VERSION "dbc-export 1 2025.20.8"

NS_ :

BS_:

BU_: ADSP APB APP APS BB BMS CC CP DAS DI DIF DIR EPAS3P EPAS3S EPBL EPBR GTW HVP ICR IDB PCS PM TCU UI UIS VC VCFRONT VCLEFT VCRIGHT VCSEC

BO_ 628 UI_vehicleControl3: 8 UI
 SG_ UI_lightFlashRequest : 0|2@1+ (1,0) [0|3] "" Vector__XXX
 SG_ UI_phoneCallActive : 3|1@1+ (1,0) [0|1] "" Vector__XXX
 SG_ UI_lightShowClosuresEnabled : 8|1@1+ (1,0) [0|1] "" Vector__XXX
 SG_ UI_steeringWheelHeatAutoReq : 9|1@1+ (1,0) [0|1] "" Vector__XXX
 SG_ UI_steeringWheelHeatLevelReq : 10|2@1+ (1,0) [0|3] "" Vector__XXX
 SG_ UI_headlightPulseRequest : 12|1@1+ (1,0) [0|1] "" Vector__XXX
 SG_ UI_displayRedShiftActive : 24|1@1+ (1,0) [0|1] "" Vector__XXX
 SG_ UI_fasciaCameraWashRequest : 26|1@1+ (1,0) [0|1] "" Vector__XXX
 SG_ UI_leftRearSeatAdjustmentRequest : 28|3@1+ (1,0) [0|7] "" Vector__XXX
 SG_ UI_rightRearSeatAdjustmentReques : 32|3@1+ (1,0) [0|7] "" Vector__XXX
 SG_ UI_blindSpotIndicatorLightReques : 35|1@1+ (1,0) [0|1] "" Vector__XXX
 SG_ UI_keepOnAccessoryPortsReq : 38|1@1+ (1,0) [0|1] "" Vector__XXX
 SG_ UI_fasciaCameraShown : 39|1@1+ (1,0) [0|1] "" Vector__XXX
 SG_ UI_rearSeatChildLock : 40|2@1+ (1,0) [0|3] "" Vector__XXX
 SG_ UI_windowPercentageRequest : 42|6@1- (5,0) [-100|100] "%" Vector__XXX
 SG_ UI_windowRequestedFL : 48|1@1+ (1,0) [0|1] "" Vector__XXX
 SG_ UI_windowRequestedFR : 49|1@1+ (1,0) [0|1] "" Vector__XXX
 SG_ UI_windowRequestedRL : 50|1@1+ (1,0) [0|1] "" Vector__XXX
 SG_ UI_windowRequestedRR : 51|1@1+ (1,0) [0|1] "" Vector__XXX
 SG_ UI_windowRequest : 52|3@1+ (1,0) [0|7] "" Vector__XXX
 SG_ UI_closeTrunkRequest : 55|1@1+ (1,0) [0|1] "" Vector__XXX
 SG_ UI_childPresenceDetectionDisable : 56|1@1+ (1,0) [0|1] "" Vector__XXX
 SG_ UI_derivedLoadshedFeature : 59|1@1+ (1,0) [0|1] "" Vector__XXX
 SG_ UI_selfParkStandingBy : 62|1@1+ (1,0) [0|1] "" Vector__XXX

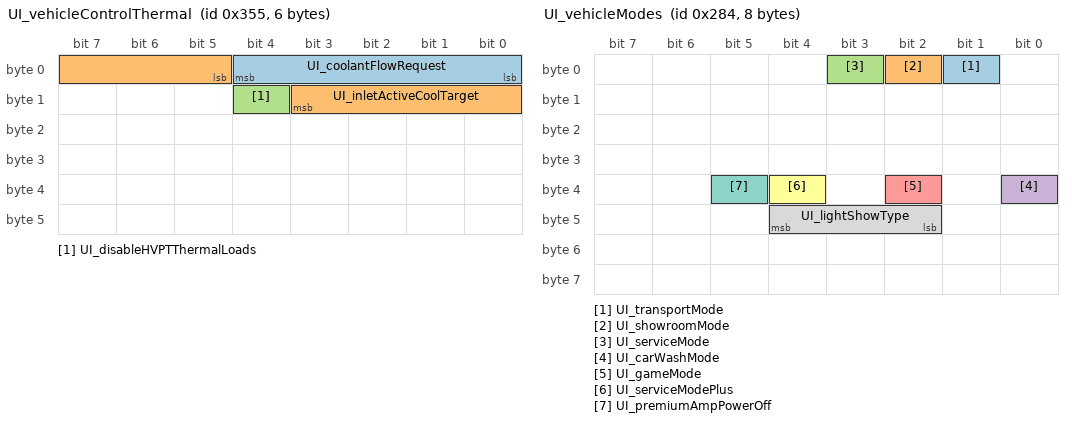
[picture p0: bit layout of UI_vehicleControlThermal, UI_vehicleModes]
BO_ 853 UI_vehicleControlThermal: 6 UI
 SG_ UI_coolantFlowRequest : 0|5@1+ (1,0) [0|25] "LPM" Vector__XXX
 SG_ UI_inletActiveCoolTarget : 5|7@1+ (1,0) [0|127] "degC" Vector__XXX
 SG_ UI_disableHVPTThermalLoads : 12|1@1+ (1,0) [0|1] "" Vector__XXX

BO_ 644 UI_vehicleModes: 8 UI
 SG_ UI_transportMode : 1|1@1+ (1,0) [0|1] "" Vector__XXX
 SG_ UI_showroomMode : 2|1@1+ (1,0) [0|1] "" Vector__XXX
 SG_ UI_serviceMode : 3|1@1+ (1,0) [0|1] "" Vector__XXX
 SG_ UI_carWashMode : 32|1@1+ (1,0) [0|1] "" Vector__XXX
 SG_ UI_gameMode : 34|1@1+ (1,0) [0|1] "" Vector__XXX
 SG_ UI_serviceModePlus : 36|1@1+ (1,0) [0|1] "" Vector__XXX
 SG_ UI_premiumAmpPowerOff : 37|1@1+ (1,0) [0|1] "" Vector__XXX
 SG_ UI_lightShowType : 42|3@1+ (1,0) [0|7] "" Vector__XXX

BO_ 595 UI_ventPanelControlRequest: 8 UI
 SG_ UI_ventPanelControlRequestIndex M : 0|1@1+ (1,0) [0|1] "" Vector__XXX
 SG_ UI_ventPanelLeftPositionX m0 : 8|8@1+ (0.5,0) [0|100] "%" Vector__XXX
 SG_ UI_ventPanelLeftPositionY m0 : 16|8@1+ (0.5,0) [0|100] "%" Vector__XXX
 SG_ UI_ventPanelLeftLateralSplit m0 : 24|8@1+ (0.5,0) [0|100] "%" Vector__XXX
 SG_ UI_ventPanelRightPositionX m0 : 32|8@1+ (0.5,0) [0|100] "%" Vector__XXX
 SG_ UI_ventPanelRightPositionY m0 : 40|8@1+ (0.5,0) [0|100] "%" Vector__XXX
 SG_ UI_ventPanelRightLateralSplit m0 : 48|8@1+ (0.5,0) [0|100] "%" Vector__XXX
 SG_ UI_ventPanelLeftLateralMode m0 : 56|2@1+ (1,0) [0|3] "" Vector__XXX
 SG_ UI_ventPanelRightLateralMode m0 : 58|2@1+ (1,0) [0|3] "" Vector__XXX
 SG_ UI_hvacReqActiveVents m0 : 60|2@1+ (1,0) [0|3] "" Vector__XXX
 SG_ UI_vent2RLeftPositionX m1 : 8|8@1+ (0.5,0) [0|100] "%" Vector__XXX
 SG_ UI_vent2RLeftPositionY m1 : 16|8@1+ (0.5,0) [0|100] "%" Vector__XXX
 SG_ UI_vent2RRightPositionX m1 : 24|8@1+ (0.5,0) [0|100] "%" Vector__XXX
 SG_ UI_vent2RRightPositionY m1 : 32|8@1+ (0.5,0) [0|100] "%" Vector__XXX

BO_ 609 VCFRONT_12VBatteryStatus: 8 VCFRONT
 SG_ VCFRONT_12VBatteryStatusIndex M : 0|3@1+ (1,0) [0|7] "" Vector__XXX
 SG_ VCFRONT_good12VforUpdate : 46|1@1+ (1,0) [0|1] "" Vector__XXX
 SG_ VCFRONT_LVLoadRequest : 47|1@1+ (1,0) [0|1] "" Vector__XXX
 SG_ VCFRONT_12VBatteryStatusCounter : 52|4@1+ (1,0) [0|15] "" Vector__XXX
 SG_ VCFRONT_12VBatteryStatusChecksum : 56|8@1+ (1,0) [0|255] "" Vector__XXX
 SG_ VCFRONT_batterySupportRequest m1 : 3|1@1+ (1,0) [0|1] "" Vector__XXX
 SG_ VCFRONT_batterySMState m1 : 4|4@1+ (1,0) [0|15] "" Vector__XXX
 SG_ VCFRONT_eFuseRecoveryStateDBG m1 : 8|3@1+ (1,0) [0|7] "" Vector__XXX
 SG_ VCFRONT_batteryLINScheduleDBG m1 : 11|3@1+ (1,0) [0|6] "" Vector__XXX
 SG_ VCFRONT_resistanceEstimationTest m1 : 14|2@1+ (1,0) [0|3] "" Vector__XXX
 SG_ VCFRONT_IBSCurrent m1 : 16|16@1- (0.005,0) [-163.84|163.835] "A" Vector__XXX
 SG_ VCFRONT_IBSVoltage m1 : 32|14@1+ (0.005443676,0) [0|65.535] "V" Vector__XXX
 SG_ VCFRONT_reverseBatteryFault m1 : 48|1@1+ (1,0) [0|1] "" Vector__XXX
 SG_ VCFRONT_LVBatterySupported m1 : 49|1@1+ (1,0) [0|1] "" Vector__XXX
 SG_ VCFRONT_LVBatteryCannotSupportVe m1 : 50|1@1+ (1,0) [0|1] "" Vector__XXX
 SG_ VCFRONT_goodTemp12VforUpdate m1 : 51|1@1+ (1,0) [0|1] "" Vector__XXX
 SG_ VCFRONT_12VBatteryTargetVoltage m2 : 3|13@1+ (0.01,0) [0|65.535] "V" Vector__XXX
 SG_ VCFRONT_IBSTemperature m2 : 16|11@1+ (0.1,-24) [-24|124] "degC" Vector__XXX
 SG_ VCFRONT_currentSensorMismatchLea m2 : 27|7@1+ (2,0) [0|254] "PCT" Vector__XXX
 SG_ VCFRONT_LVBatteryEnergyRemaining m2 : 37|7@1+ (1,0) [0|127] "%" Vector__XXX
 SG_ VCFRONT_LVBatteryStatusForDrive m2 : 44|2@1+ (1,0) [0|3] "" Vector__XXX
 SG_ VCFRONT_LVBatteryType m2 : 48|3@1+ (1,0) [0|7] "" Vector__XXX
 SG_ VCFRONT_resistanceEstimationNeed m2 : 51|1@1+ (1,0) [0|1] "" Vector__XXX
 SG_ VCFRONT_IBSVoltageFiltered m3 : 3|14@1+ (0.005443676,0) [0|65.535] "V" Vector__XXX
 SG_ VCFRONT_LVBMS_LVBusVoltageSource m3 : 17|2@1+ (1,0) [0|3] "" Vector__XXX
 SG_ VCFRONT_LVBMS_LVPackCurrentSourc m3 : 19|2@1+ (1,0) [0|3] "" Vector__XXX
 SG_ VCFRONT_LVBatterySupportRqrdTrig m3 : 24|14@1+ (1,0) [0|16383] "" Vector__XXX
 SG_ VCFRONT_goodForPCSPowerCycleLeak m3 : 40|5@1+ (0.0005,0) [0|0.0155] "Ah" Vector__XXX
 SG_ VCFRONT_LVBusControlsFutile m3 : 45|1@1+ (1,0) [0|1] "" Vector__XXX
 SG_ VCFRONT_resistanceEstimatio_0001 m3 : 48|1@1+ (1,0) [0|1] "" Vector__XXX
 SG_ VCFRONT_resistanceEstimatio_0002 m3 : 49|1@1+ (1,0) [0|1] "" Vector__XXX
 SG_ VCFRONT_goodLVChargeForUpdate m3 : 50|1@1+ (1,0) [0|1] "" Vector__XXX
 SG_ VCFRONT_opportunisticDCRTestNeed m3 : 51|1@1+ (1,0) [0|1] "" Vector__XXX
 SG_ VCFRONT_voltageProfile m4 : 3|2@1+ (1,0) [0|3] "" Vector__XXX
 SG_ VCFRONT_IBSAmpHours m4 : 5|14@1- (0.005,0) [-40.96|40.955] "Ah" Vector__XXX
 SG_ VCFRONT_IBSVoltageRawDBG m4 : 19|14@1+ (0.005443676,0) [0|65.535] "V" Vector__XXX
 SG_ VCFRONT_LVBatteryLINCommsDetecte m4 : 33|1@1+ (1,0) [0|1] "" Vector__XXX
 SG_ VCFRONT_voltageSensorMismatchLea m4 : 34|7@1+ (2,0) [0|254] "PCT" Vector__XXX
 SG_ VCFRONT_LVBatteryFctryLimOverrid m4 : 50|1@1+ (1,0) [0|1] "" Vector__XXX
 SG_ VCFRONT_LVBatterySPICommsDetecte m4 : 51|1@1+ (1,0) [0|1] "" Vector__XXX
 SG_ VCFRONT_targetCurrent m5 : 3|11@1+ (0.125,-127) [0|120] "A" Vector__XXX
 SG_ VCFRONT_PCSMia m5 : 14|1@1+ (1,0) [0|1] "" Vector__XXX
 SG_ VCFRONT_chargeNeeded m5 : 15|1@1+ (1,0) [0|1] "" Vector__XXX
 SG_ VCFRONT_voltageControlLoopIntegr m5 : 16|14@1+ (0.006,0) [0|65.535] "V" Vector__XXX
 SG_ VCFRONT_currentControlLoopIntegr m5 : 30|14@1+ (0.006,0) [0|65.535] "V" Vector__XXX

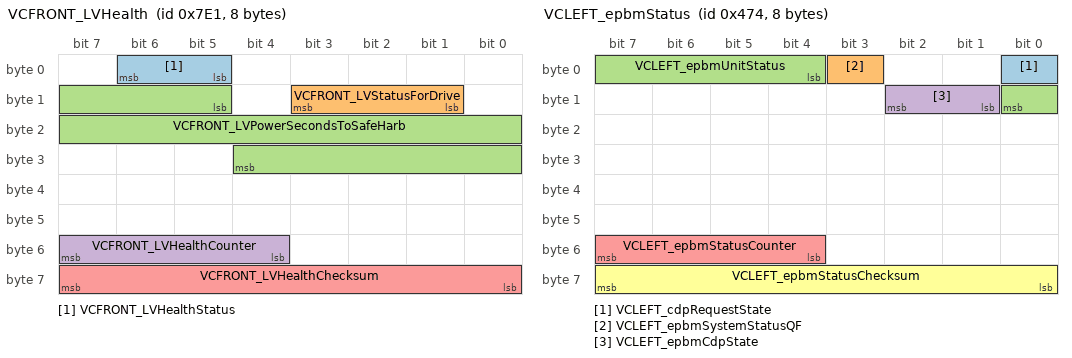
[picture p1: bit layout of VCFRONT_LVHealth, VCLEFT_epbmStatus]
BO_ 2017 VCFRONT_LVHealth: 8 VCFRONT
 SG_ VCFRONT_LVHealthStatus : 5|2@1+ (1,0) [0|3] "" Vector__XXX
 SG_ VCFRONT_LVStatusForDrive : 9|3@1+ (1,0) [0|7] "" Vector__XXX
 SG_ VCFRONT_LVPowerSecondsToSafeHarb : 13|16@1+ (1,0) [0|65535] "" Vector__XXX
 SG_ VCFRONT_LVHealthCounter : 52|4@1+ (1,0) [0|15] "" Vector__XXX
 SG_ VCFRONT_LVHealthChecksum : 56|8@1+ (1,0) [0|255] "" Vector__XXX

BO_ 2016 VCFRONT_LVHealthDebug: 6 VCFRONT
 SG_ VCFRONT_LVHealthDebugIndex M : 0|4@1+ (1,0) [0|15] "" Vector__XXX
 SG_ VCFRONT_LVHEALTH_placeholder m0 : 8|1@1+ (1,0) [0|1] "" Vector__XXX
 SG_ VCFRONT_LVHEALTH_activeDecelEner m0 : 9|1@1+ (1,0) [0|1] "" Vector__XXX
 SG_ VCFRONT_LVHEALTH_criticalPullove m0 : 10|1@1+ (1,0) [0|1] "" Vector__XXX
 SG_ VCFRONT_LVHEALTH_revBattEFuseOff m0 : 11|1@1+ (1,0) [0|1] "" Vector__XXX
 SG_ VCFRONT_LVHEALTH_LVBMBEFuseOpen m0 : 12|1@1+ (1,0) [0|1] "" Vector__XXX
 SG_ VCFRONT_LVHEALTH_lvBatteryCommsM m0 : 13|1@1+ (1,0) [0|1] "" Vector__XXX
 SG_ VCFRONT_LVHEALTH_pcsEFuseOff m0 : 14|1@1+ (1,0) [0|1] "" Vector__XXX
 SG_ VCFRONT_LVHEALTH_pcsNotActive m0 : 15|1@1+ (1,0) [0|1] "" Vector__XXX
 SG_ VCFRONT_LVHEALTH_pcsMIA m0 : 16|1@1+ (1,0) [0|1] "" Vector__XXX
 SG_ VCFRONT_LVHEALTH_IBSMIA m0 : 17|1@1+ (1,0) [0|1] "" Vector__XXX
 SG_ VCFRONT_LVHEALTH_LVBatteryElecDi m0 : 18|1@1+ (1,0) [0|1] "" Vector__XXX
 SG_ VCFRONT_LVHEALTH_LVBatteryE_0001 m0 : 19|1@1+ (1,0) [0|1] "" Vector__XXX
 SG_ VCFRONT_LVHEALTH_pcsOpenCircuit m0 : 20|1@1+ (1,0) [0|1] "" Vector__XXX
 SG_ VCFRONT_LVHEALTH_activeDecelPowe m0 : 21|1@1+ (1,0) [0|1] "" Vector__XXX
 SG_ VCFRONT_LVHEALTH_lvBatteryCapabi m0 : 22|1@1+ (1,0) [0|1] "" Vector__XXX
 SG_ VCFRONT_LVHEALTH_lvBatteryConfig m0 : 23|1@1+ (1,0) [0|1] "" Vector__XXX
 SG_ VCFRONT_LVHEALTH_lvBatteryImpeda m0 : 24|1@1+ (1,0) [0|1] "" Vector__XXX

BO_ 545 VCFRONT_LVPowerState: 8 VCFRONT
 SG_ VCFRONT_LVPowerStateIndex M : 0|5@1+ (1,0) [0|31] "" Vector__XXX
 SG_ VCFRONT_vehiclePowerState : 5|2@1+ (1,0) [0|3] "" Vector__XXX
 SG_ VCFRONT_inAccessoryPlus : 50|1@1+ (1,0) [0|1] "" Vector__XXX
 SG_ VCFRONT_LVShuttingDown : 51|1@1+ (1,0) [0|1] "" Vector__XXX
 SG_ VCFRONT_LVPowerStateCounter : 52|4@1+ (1,0) [0|15] "" Vector__XXX
 SG_ VCFRONT_LVPowerStateChecksum : 56|8@1+ (1,0) [0|255] "" Vector__XXX
 SG_ VCFRONT_cpLVRequest m1 : 8|2@1+ (1,0) [0|3] "" Vector__XXX
 SG_ VCFRONT_epasLVState m1 : 10|2@1+ (1,0) [0|3] "" Vector__XXX
 SG_ VCFRONT_hvcLVRequest m1 : 12|2@1+ (1,0) [0|3] "" Vector__XXX
 SG_ VCFRONT_tasLVState m1 : 14|2@1+ (1,0) [0|3] "" Vector__XXX
 SG_ VCFRONT_pcsLVState m1 : 16|2@1+ (1,0) [0|3] "" Vector__XXX
 SG_ VCFRONT_CMPDLVState m1 : 18|2@1+ (1,0) [0|3] "" Vector__XXX
 SG_ VCFRONT_hcmlLVState m1 : 20|2@1+ (1,0) [0|3] "" Vector__XXX
 SG_ VCFRONT_hcmrLVState m1 : 22|2@1+ (1,0) [0|3] "" Vector__XXX
 SG_ VCFRONT_MCUAudioLVState m1 : 24|2@1+ (1,0) [0|3] "" Vector__XXX
 SG_ VCFRONT_espValveLVState m1 : 26|2@1+ (1,0) [0|3] "" Vector__XXX
 SG_ VCFRONT_MCUGraphicsLVState m1 : 28|2@1+ (1,0) [0|3] "" Vector__XXX
 SG_ VC_dcdcSupportRequest m1 : 30|1@1+ (1,0) [0|1] "" Vector__XXX
 SG_ VC_hvStateRequest m1 : 31|3@1+ (1,0) [0|7] "" Vector__XXX
 SG_ VC_persistAccPowerRequestOverrid m1 : 39|1@1+ (1,0) [0|1] "" Vector__XXX
 SG_ VC_accPortPowerRequest m1 : 40|1@1+ (1,0) [0|1] "" Vector__XXX
 SG_ VC_persistAccPortPowerState m1 : 41|3@1+ (1,0) [0|7] "" Vector__XXX

BO_ 753 VCFRONT_eFuseDebugStatus: 8 VCFRONT
 SG_ VCFRONT_eFuseDebugStatusIndex M : 0|5@1+ (1,0) [0|31] "" Vector__XXX
 SG_ VCFRONT_leftControllerState m1 : 8|2@1+ (1,0) [0|2] "" Vector__XXX
 SG_ VCFRONT_leftControllerFault m1 : 10|1@1+ (1,0) [0|1] "" Vector__XXX
 SG_ VCFRONT_vcleftSelfTestResult m1 : 11|4@1+ (1,0) [0|15] "" Vector__XXX
 SG_ VCFRONT_leftControllerTemp m1 : 15|11@1+ (0.125,-40) [-40|150] "degC" Vector__XXX
 SG_ VCFRONT_leftControllerEFuseVNFSt m1 : 26|3@1+ (1,0) [0|7] "" Vector__XXX
 SG_ VCFRONT_leftControllerEFuseOutpu m1 : 29|1@1+ (1,0) [0|1] "" Vector__XXX
 SG_ VCFRONT_leftControllerEFuse_0002 m1 : 30|1@1+ (1,0) [0|1] "" Vector__XXX
 SG_ VCFRONT_leftControllerVoltage m1 : 31|14@1+ (0.1,0) [0|1638.3] "V" Vector__XXX
 SG_ VCFRONT_leftControllerEFuseBypas m1 : 45|1@1+ (1,0) [0|1] "" Vector__XXX
 SG_ VCFRONT_leftControllerEFuse_0001 m1 : 46|1@1+ (1,0) [0|1] "" Vector__XXX
 SG_ VCFRONT_leftControllerCurrent m1 : 47|14@1+ (0.1,0) [0|1638.3] "A" Vector__XXX
 SG_ VCFRONT_leftControllerEFuseVNFSe m1 : 61|2@1+ (1,0) [0|3] "" Vector__XXX
 SG_ VCFRONT_PCSState m2 : 8|2@1+ (1,0) [0|2] "" Vector__XXX
 SG_ VCFRONT_PCSFault m2 : 10|1@1+ (1,0) [0|1] "" Vector__XXX
 SG_ VCFRONT_pcsSelfTestResult m2 : 11|4@1+ (1,0) [0|15] "" Vector__XXX
 SG_ VCFRONT_PCSTemp m2 : 15|11@1+ (0.125,-40) [-40|150] "degC" Vector__XXX
 SG_ VCFRONT_PCSEFuseVNFState m2 : 26|3@1+ (1,0) [0|7] "" Vector__XXX
 SG_ VCFRONT_PCSEFuseOutput m2 : 29|1@1+ (1,0) [0|1] "" Vector__XXX
 SG_ VCFRONT_PCSEFuseOutputDesired m2 : 30|1@1+ (1,0) [0|1] "" Vector__XXX
 SG_ VCFRONT_PCSVoltage m2 : 31|14@1+ (0.1,0) [0|1638.3] "V" Vector__XXX
 SG_ VCFRONT_PCSEFuseBypass m2 : 45|1@1+ (1,0) [0|1] "" Vector__XXX
 SG_ VCFRONT_PCSEFuseBypassDesired m2 : 46|1@1+ (1,0) [0|1] "" Vector__XXX
 SG_ VCFRONT_PCSEFuseVNFSelfTestStatu m2 : 61|2@1+ (1,0) [0|3] "" Vector__XXX
 SG_ VCFRONT_iBoosterState m3 : 8|2@1+ (1,0) [0|2] "" Vector__XXX
 SG_ VCFRONT_iBoosterFault m3 : 10|1@1+ (1,0) [0|1] "" Vector__XXX
 SG_ VCFRONT_iBoosterSelfTestResult m3 : 11|4@1+ (1,0) [0|15] "" Vector__XXX
 SG_ VCFRONT_iBoosterTemp m3 : 15|11@1+ (0.125,-40) [-40|150] "degC" Vector__XXX
 SG_ VCFRONT_iBoosterVoltage m3 : 31|14@1+ (0.1,0) [0|51.1] "V" Vector__XXX
 SG_ VCFRONT_iBoosterCurrent m3 : 47|14@1+ (0.1,0) [0|1638.3] "A" Vector__XXX
 SG_ VCFRONT_EPAS3PState m4 : 8|2@1+ (1,0) [0|2] "" Vector__XXX
 SG_ VCFRONT_EPAS3PFault m4 : 10|1@1+ (1,0) [0|1] "" Vector__XXX
 SG_ VCFRONT_EPAS3PSelfTestResult m4 : 11|4@1+ (1,0) [0|15] "" Vector__XXX
 SG_ VCFRONT_EPAS3PTemp m4 : 15|11@1+ (0.125,-40) [-40|150] "degC" Vector__XXX
 SG_ VCFRONT_EPAS3PEFuseVNFState m4 : 26|3@1+ (1,0) [0|7] "" Vector__XXX
 SG_ VCFRONT_EPAS3PEFuseOutput m4 : 29|1@1+ (1,0) [0|1] "" Vector__XXX
 SG_ VCFRONT_EPAS3PEFuseOutputDesired m4 : 30|1@1+ (1,0) [0|1] "" Vector__XXX
 SG_ VCFRONT_EPAS3PVoltage m4 : 31|9@1+ (0.1,0) [0|51.1] "V" Vector__XXX
 SG_ VCFRONT_EPAS3PEFuseHardshortThre m4 : 40|4@1+ (1,0) [0|15] "" Vector__XXX
 SG_ VCFRONT_EPAS3PEFuseBypass m4 : 45|1@1+ (1,0) [0|1] "" Vector__XXX
 SG_ VCFRONT_EPAS3PEFuseBypassDesired m4 : 46|1@1+ (1,0) [0|1] "" Vector__XXX
 SG_ VCFRONT_EPAS3PCurrent m4 : 47|14@1+ (0.1,0) [0|1638.3] "A" Vector__XXX
 SG_ VCFRONT_EPAS3PEFuseVNFSelfTestSt m4 : 61|2@1+ (1,0) [0|3] "" Vector__XXX
 SG_ VCFRONT_EPAS3SState m5 : 8|2@1+ (1,0) [0|2] "" Vector__XXX
 SG_ VCFRONT_EPAS3SFault m5 : 10|1@1+ (1,0) [0|1] "" Vector__XXX
 SG_ VCFRONT_EPAS3SSelfTestResult m5 : 11|4@1+ (1,0) [0|15] "" Vector__XXX
 SG_ VCFRONT_EPAS3STemp m5 : 15|11@1+ (0.125,-40) [-40|150] "degC" Vector__XXX
 SG_ VCFRONT_EPAS3SEFuseVNFState m5 : 26|3@1+ (1,0) [0|7] "" Vector__XXX
 SG_ VCFRONT_EPAS3SEFuseOutput m5 : 29|1@1+ (1,0) [0|1] "" Vector__XXX
 SG_ VCFRONT_EPAS3SEFuseOutputDesired m5 : 30|1@1+ (1,0) [0|1] "" Vector__XXX
 SG_ VCFRONT_EPAS3SVoltage m5 : 31|14@1+ (0.1,0) [0|1638.3] "V" Vector__XXX
 SG_ VCFRONT_EPAS3SEFuseBypass m5 : 45|1@1+ (1,0) [0|1] "" Vector__XXX
 SG_ VCFRONT_EPAS3SEFuseBypassDesired m5 : 46|1@1+ (1,0) [0|1] "" Vector__XXX
 SG_ VCFRONT_EPAS3SCurrent m5 : 47|14@1+ (0.1,0) [0|1638.3] "A" Vector__XXX
 SG_ VCFRONT_EPAS3SEFuseVNFSelfTestSt m5 : 61|2@1+ (1,0) [0|3] "" Vector__XXX
 SG_ VCFRONT_ESPMotorState m6 : 8|2@1+ (1,0) [0|2] "" Vector__XXX
 SG_ VCFRONT_ESPMotorFault m6 : 10|1@1+ (1,0) [0|1] "" Vector__XXX
 SG_ VCFRONT_ESPMotorSelfTestResult m6 : 11|4@1+ (1,0) [0|15] "" Vector__XXX
 SG_ VCFRONT_ESPMotorTemp m6 : 15|11@1+ (0.125,-40) [-40|150] "degC" Vector__XXX
 SG_ VCFRONT_ESPMotorEFuseVNFState m6 : 26|3@1+ (1,0) [0|7] "" Vector__XXX
 SG_ VCFRONT_ESPMotorEFuseOutput m6 : 29|1@1+ (1,0) [0|1] "" Vector__XXX
 SG_ VCFRONT_ESPMotorEFuseOutputDesir m6 : 30|1@1+ (1,0) [0|1] "" Vector__XXX
 SG_ VCFRONT_ESPMotorVoltage m6 : 31|14@1+ (0.1,0) [0|1638.3] "V" Vector__XXX
 SG_ VCFRONT_ESPMotorEFuseBypass m6 : 45|1@1+ (1,0) [0|1] "" Vector__XXX
 SG_ VCFRONT_ESPMotorEFuseBypassDesir m6 : 46|1@1+ (1,0) [0|1] "" Vector__XXX
 SG_ VCFRONT_ESPMotorCurrent m6 : 47|14@1+ (0.1,0) [0|1638.3] "A" Vector__XXX
 SG_ VCFRONT_ESPMotorEFuseVNFSelfTest m6 : 61|2@1+ (1,0) [0|3] "" Vector__XXX
 SG_ VCFRONT_ESPValveState m7 : 8|2@1+ (1,0) [0|2] "" Vector__XXX
 SG_ VCFRONT_ESPValveFault m7 : 10|1@1+ (1,0) [0|1] "" Vector__XXX
 SG_ VCFRONT_ESPValveTemp m7 : 12|11@1+ (0.125,-40) [-40|150] "degC" Vector__XXX
 SG_ VCFRONT_ESPValveVoltage m7 : 28|16@1+ (0.1,0) [0|6553.5] "V" Vector__XXX
 SG_ VCFRONT_ESPValveCurrent m7 : 44|16@1+ (0.01,0) [0|655.35] "A" Vector__XXX
 SG_ VCFRONT_autopilot2State m9 : 8|2@1+ (1,0) [0|2] "" Vector__XXX
 SG_ VCFRONT_autopilot2Fault m9 : 10|1@1+ (1,0) [0|1] "" Vector__XXX
 SG_ VCFRONT_autopilot2Temp m9 : 11|11@1+ (0.125,-40) [-40|150] "degC" Vector__XXX
 SG_ VCFRONT_autopilot2Voltage m9 : 27|16@1+ (0.1,0) [0|6553.5] "V" Vector__XXX
 SG_ VCFRONT_autopilot2Current m9 : 43|10@1+ (0.044,0) [0|45.012] "A" Vector__XXX
 SG_ VCFRONT_sleepBypassState m10 : 8|1@1+ (1,0) [0|1] "" Vector__XXX
 SG_ VCFRONT_sleepBypassFault m10 : 9|1@1+ (1,0) [0|1] "" Vector__XXX
 SG_ VCFRONT_sleepBypassVoltage m10 : 10|16@1+ (0.1,0) [0|6553.5] "V" Vector__XXX
 SG_ VCFRONT_sleepBypassCurrent m10 : 26|16@1+ (0.1,0) [0|6553.5] "A" Vector__XXX
 SG_ VCFRONT_vbatFusedHighState m13 : 8|1@1+ (1,0) [0|1] "" Vector__XXX
 SG_ VCFRONT_vbatFusedHighFault m13 : 9|1@1+ (1,0) [0|1] "" Vector__XXX
 SG_ VCFRONT_vbatFusedSelfTestResult m13 : 10|4@1+ (1,0) [0|15] "" Vector__XXX
 SG_ VCFRONT_vbatFusedHighTemp m13 : 14|11@1+ (0.125,-40) [-40|150] "degC" Vector__XXX
 SG_ VCFRONT_vbatFusedHighVoltage m13 : 30|16@1+ (0.1,0) [0|6553.5] "V" Vector__XXX
 SG_ VCFRONT_vbatFusedHighCurrent m13 : 46|16@1+ (0.1,0) [0|6553.5] "A" Vector__XXX
 SG_ VCFRONT_chargedIBSAmpHours m17 : 8|16@1+ (1,0) [0|65535] "Ah" Vector__XXX
 SG_ VCFRONT_dischargedIBSAmpHours m17 : 24|16@1+ (1,0) [0|65535] "Ah" Vector__XXX
 SG_ VCFRONT_IBSUnfilteredTemperature m17 : 40|16@1- (0.01,0) [-327.67|327.67] "degC" Vector__XXX

BO_ 769 VCFRONT_info: 8 VCFRONT
 SG_ VCFRONT_infoIndex M : 0|8@1+ (1,0) [0|255] "" Vector__XXX
 SG_ VCFRONT_infoBuildType m10 : 8|3@1+ (1,0) [0|7] "" Vector__XXX
 SG_ VCFRONT_infoBuildConfigId m10 : 16|16@1+ (1,0) [0|65535] "" Vector__XXX
 SG_ VCFRONT_infoHardwareId m10 : 32|16@1+ (1,0) [0|65535] "" Vector__XXX
 SG_ VCFRONT_infoComponentId m10 : 48|16@1+ (1,0) [0|65535] "" Vector__XXX
 SG_ VCFRONT_infoPcbaId m11 : 8|8@1+ (1,0) [0|255] "" Vector__XXX
 SG_ VCFRONT_infoAssemblyId m11 : 16|8@1+ (1,0) [0|254] "" Vector__XXX
 SG_ VCFRONT_infoUsageId m11 : 24|16@1+ (1,0) [0|65535] "" Vector__XXX
 SG_ VCFRONT_infoSubUsageId m11 : 40|16@1+ (1,0) [0|65535] "" Vector__XXX
 SG_ VCFRONT_infoAppCrc m13 : 8|32@1+ (1,0) [0|4294967295] "" Vector__XXX
 SG_ VC_infoHCMLAppCRC m16 : 32|32@1+ (1,0) [0|4294967295] "" Vector__XXX
 SG_ VCFRONT_infoAppGitHash m17 : 8|56@1+ (1,0) [0|7.20575940379e+16] "" Vector__XXX
 SG_ VCFRONT_infoBootGitHash m18 : 8|56@1+ (1,0) [0|7.20575940379e+16] "" Vector__XXX
 SG_ VCFRONT_infoPlatformType m19 : 8|8@1+ (1,0) [0|255] "" Vector__XXX
 SG_ VCFRONT_infoBootUdsProtoVersion m20 : 8|16@1+ (1,0) [0|65535] "" Vector__XXX
 SG_ VCFRONT_infoBootCrc m20 : 24|32@1+ (1,0) [0|4294967295] "" Vector__XXX
 SG_ VC_infoHCMRAppCRC m23 : 32|32@1+ (1,0) [0|4294967295] "" Vector__XXX

BO_ 1801 VCFRONT_logging0point1Hz: 8 VCFRONT
 SG_ VCFRONT_logging0point1HzIndex M : 0|5@1+ (1,0) [0|31] "" Vector__XXX
 SG_ VC_hcmlFactoryOfOrigin m26 : 5|2@1+ (1,0) [0|3] "" Vector__XXX
 SG_ VC_hcmlHellaPartNumberStatus m26 : 7|1@1+ (1,0) [0|1] "" Vector__XXX
 SG_ VC_hcmlHellaPartNumber m26 : 8|32@1+ (1,0) [0|4294967295] "-" Vector__XXX
 SG_ VC_hcmlCurrentBinMappingType m26 : 40|2@1+ (1,0) [0|3] "" Vector__XXX
 SG_ VC_hcmlCurrentBin0Value m26 : 42|3@1+ (1,0) [1|7] "" Vector__XXX
 SG_ VC_hcmlCurrentBin1Value m26 : 45|3@1+ (1,0) [1|7] "" Vector__XXX
 SG_ VC_hcmlCurrentBin2Value m26 : 48|3@1+ (1,0) [1|7] "" Vector__XXX
 SG_ VC_hcmlCurrentBin3Value m26 : 51|3@1+ (1,0) [1|7] "" Vector__XXX
 SG_ VC_hcmlCurrentBin4Value m26 : 54|3@1+ (1,0) [1|7] "" Vector__XXX
 SG_ VC_hcmlCurrentBin5Value m26 : 57|3@1+ (1,0) [1|7] "" Vector__XXX
 SG_ VC_hcmlRegionAndSide m26 : 60|3@1+ (1,0) [1|7] "" Vector__XXX
 SG_ VC_hcmrFactoryOfOrigin m27 : 5|2@1+ (1,0) [0|3] "" Vector__XXX
 SG_ VC_hcmrHellaPartNumberStatus m27 : 7|1@1+ (1,0) [0|1] "" Vector__XXX
 SG_ VC_hcmrHellaPartNumber m27 : 8|32@1+ (1,0) [0|4294967295] "-" Vector__XXX
 SG_ VC_hcmrCurrentBinMappingType m27 : 40|2@1+ (1,0) [0|3] "" Vector__XXX
 SG_ VC_hcmrCurrentBin0Value m27 : 42|3@1+ (1,0) [1|7] "" Vector__XXX
 SG_ VC_hcmrCurrentBin1Value m27 : 45|3@1+ (1,0) [1|7] "" Vector__XXX
 SG_ VC_hcmrCurrentBin2Value m27 : 48|3@1+ (1,0) [1|7] "" Vector__XXX
 SG_ VC_hcmrCurrentBin3Value m27 : 51|3@1+ (1,0) [1|7] "" Vector__XXX
 SG_ VC_hcmrCurrentBin4Value m27 : 54|3@1+ (1,0) [1|7] "" Vector__XXX
 SG_ VC_hcmrCurrentBin5Value m27 : 57|3@1+ (1,0) [1|7] "" Vector__XXX
 SG_ VC_hcmrRegionAndSide m27 : 60|3@1+ (1,0) [1|7] "" Vector__XXX

BO_ 705 VCFRONT_logging10Hz: 8 VCFRONT
 SG_ VCFRONT_logging10HzIndex M : 0|3@1+ (1,0) [0|7] "" Vector__XXX
 SG_ VCFRONT_pumpBatteryOutVoltage m0 : 3|7@1+ (0.2,0) [0|20] "V" Vector__XXX
 SG_ VCFRONT_pumpPowertrainOutVoltage m0 : 10|7@1+ (0.2,0) [0|20] "V" Vector__XXX
 SG_ VCFRONT_pumpBatteryInitd m0 : 17|1@1+ (1,0) [0|1] "" Vector__XXX
 SG_ VCFRONT_pumpPowertrainInitd m0 : 18|1@1+ (1,0) [0|1] "" Vector__XXX
 SG_ VCFRONT_pumpBatteryEnabled m0 : 19|1@1+ (1,0) [0|1] "" Vector__XXX
 SG_ VCFRONT_pumpPowertrainEnabled m0 : 20|1@1+ (1,0) [0|1] "" Vector__XXX
 SG_ VCFRONT_pumpBatteryPowerOn m0 : 21|1@1+ (1,0) [0|1] "" Vector__XXX
 SG_ VCFRONT_pumpPowertrainPowerOn m0 : 22|1@1+ (1,0) [0|1] "" Vector__XXX
 SG_ VCFRONT_pumpsWake m0 : 23|1@1+ (1,0) [0|1] "" Vector__XXX
 SG_ VCFRONT_pumpBatSpiError m0 : 24|1@1+ (1,0) [0|1] "" Vector__XXX
 SG_ VCFRONT_pumpPtSpiError m0 : 25|1@1+ (1,0) [0|1] "" Vector__XXX
 SG_ VCFRONT_coolantFlowChillerActual m0 : 26|8@1+ (0.1,0) [0|25] "LPM" Vector__XXX
 SG_ VCFRONT_radiatorFanOutVoltage m0 : 34|7@1+ (0.2,0) [0|20] "V" Vector__XXX
 SG_ VCFRONT_radiatorFanInitd m0 : 41|1@1+ (1,0) [0|1] "" Vector__XXX
 SG_ VCFRONT_radiatorFanEnabled m0 : 42|1@1+ (1,0) [0|1] "" Vector__XXX
 SG_ VCFRONT_radiatorFanPowerOn m0 : 43|1@1+ (1,0) [0|1] "" Vector__XXX
 SG_ VCFRONT_radiatorFanPhaseCurrent m0 : 44|8@1+ (0.25,-10) [-10|50] "A" Vector__XXX
 SG_ VCFRONT_radiatorFanPhaseIMax m0 : 52|7@1+ (0.25,5) [5|35] "A" Vector__XXX
 SG_ VCFRONT_thmlFanSpiError m0 : 59|1@1+ (1,0) [0|1] "" Vector__XXX
 SG_ VCFRONT_chargeTrapNominalCOP1Bat m0 : 60|1@1+ (1,0) [0|1] "" Vector__XXX
 SG_ VCFRONT_chargeTrapNominalCOP1Chi m0 : 61|1@1+ (1,0) [0|1] "" Vector__XXX

BO_ 897 VCFRONT_logging1Hz: 8 VCFRONT
 SG_ VCFRONT_logging1HzIndex M : 0|5@1+ (1,0) [0|31] "" Vector__XXX
 SG_ VCFRONT_modeTransitionID m0 : 5|6@1+ (1,0) [0|63] "" Vector__XXX
 SG_ VCFRONT_modeDesired m0 : 11|2@1+ (1,0) [0|3] "" Vector__XXX
 SG_ VCFRONT_targetPTActiveCool m0 : 13|7@1+ (1,0) [0|100] "degC" Vector__XXX
 SG_ VCFRONT_targetPtOptionalActiveCo m0 : 20|7@1+ (1,0) [0|100] "degC" Vector__XXX
 SG_ VCFRONT_targetPTPassive m0 : 27|7@1+ (1,-20) [-20|80] "degC" Vector__XXX
 SG_ VCFRONT_targetBatActiveCool m0 : 34|7@1+ (1,0) [0|100] "degC" Vector__XXX
 SG_ VCFRONT_targetBatOptionalActiveC m0 : 41|7@1+ (1,0) [0|100] "degC" Vector__XXX
 SG_ VCFRONT_targetBatPassive m0 : 48|7@1+ (1,-20) [-20|80] "degC" Vector__XXX
 SG_ VCFRONT_targetBatActiveHeat m0 : 55|7@1+ (1,-40) [-40|60] "degC" Vector__XXX
 SG_ VCFRONT_condenserPressureLimit m1 : 5|6@1+ (0.16,10) [10|20] "bar" Vector__XXX
 SG_ VCFRONT_fanDemandCondenser m1 : 11|7@1+ (1,0) [0|100] "%" Vector__XXX
 SG_ VCFRONT_fanDemandRadiator m1 : 18|7@1+ (1,0) [0|100] "%" Vector__XXX
 SG_ VCFRONT_tempRefrigSuction m1 : 25|8@1+ (0.5,-40) [-40|85] "degC" Vector__XXX
 SG_ VCFRONT_pumpBatteryFETTemp m1 : 33|8@1+ (1,-40) [-40|150] "degC" Vector__XXX
 SG_ VCFRONT_pumpPowertrainFETTemp m1 : 41|8@1+ (1,-40) [-40|150] "degC" Vector__XXX
 SG_ VCFRONT_radiatorFanFETTemp m1 : 49|8@1+ (1,-40) [-40|150] "degC" Vector__XXX
 SG_ VCFRONT_radiatorFanRunReason m1 : 57|4@1+ (1,0) [0|15] "" Vector__XXX
 SG_ VCFRONT_coolantValveModeWrong m1 : 61|1@1+ (1,0) [0|1] "" Vector__XXX
 SG_ VCFRONT_coolantTempBasedMode m1 : 62|2@1+ (1,0) [0|3] "" Vector__XXX
 SG_ VCFRONT_coolantValveRecalReason m2 : 5|3@1+ (1,0) [0|7] "" Vector__XXX
 SG_ VCFRONT_coolantValveCountRange m2 : 8|10@1+ (1,375) [375|1375] "ticks" Vector__XXX
 SG_ VCFRONT_coolantValveAngleDrift m2 : 18|10@1+ (0.25,-127) [-127|127] "degrees" Vector__XXX
 SG_ VCFRONT_coolantValveRecalCount m2 : 28|16@1+ (1,0) [0|65535] "" Vector__XXX
 SG_ VCFRONT_coolantValveWindupEst m2 : 44|6@1+ (2,0) [0|126] "ticks" Vector__XXX
 SG_ VCFRONT_coolantValveRadBypass m2 : 50|7@1+ (1,0) [0|100] "%" Vector__XXX
 SG_ VCFRONT_usingModeledPs m2 : 57|1@1+ (1,0) [0|1] "" Vector__XXX
 SG_ VCFRONT_usingModeledPd m2 : 58|1@1+ (1,0) [0|1] "" Vector__XXX
 SG_ VCFRONT_usingModeledPl m2 : 59|1@1+ (1,0) [0|1] "" Vector__XXX
 SG_ VCFRONT_usingModeledTs m2 : 60|1@1+ (1,0) [0|1] "" Vector__XXX
 SG_ VCFRONT_usingModeledTd m2 : 61|1@1+ (1,0) [0|1] "" Vector__XXX
 SG_ VCFRONT_usingModeledTl m2 : 62|1@1+ (1,0) [0|1] "" Vector__XXX
 SG_ VCFRONT_hpChargeCableType m5 : 5|2@1+ (1,0) [0|3] "" Vector__XXX
 SG_ VCFRONT_subcoolActual m5 : 8|7@1- (0.4,15.2) [-10|40] "degC" Vector__XXX
 SG_ VCFRONT_hpSubcoolTarget m5 : 16|5@1+ (1,0) [0|31] "degC" Vector__XXX
 SG_ VCFRONT_CMPDischargeSuperheat m5 : 21|5@1- (1,6) [-10|21] "degC" Vector__XXX
 SG_ VCFRONT_hpCOP m5 : 26|6@1+ (0.1,0) [0|6] "-" Vector__XXX
 SG_ VCFRONT_lowSideWattsLift m5 : 32|7@1+ (60,0) [0|7600] "W" Vector__XXX
 SG_ VCFRONT_tempSuperheatActual m5 : 39|10@1+ (0.1,-20) [-20|80] "degC" Vector__XXX
 SG_ VCFRONT_tempSuperheatTarget m5 : 49|10@1+ (0.1,0) [0|60] "degC" Vector__XXX
 SG_ VCFRONT_refrigerantHasBeenFilled m5 : 59|1@1+ (1,0) [0|1] "" Vector__XXX
 SG_ VCFRONT_refCommissionStatus m5 : 60|2@1+ (1,0) [0|3] "" Vector__XXX
 SG_ VCFRONT_LCCPurgeActive m5 : 62|1@1+ (1,0) [0|1] "" Vector__XXX
 SG_ VCFRONT_exteriorQuietModeEnabled m6 : 5|1@1+ (1,0) [0|1] "" Vector__XXX
 SG_ VCFRONT_exteriorQuietModeAllowed m6 : 6|1@1+ (1,0) [0|1] "" Vector__XXX
 SG_ VCFRONT_CCQdotFdFrwrdTarget m6 : 7|7@1+ (80,0) [0|10100] "W" Vector__XXX
 SG_ VCFRONT_CCQdotFdbk m6 : 14|7@1- (80,0) [-5000|5000] "W" Vector__XXX
 SG_ VCFRONT_CCQdotActual m6 : 21|7@1+ (80,0) [0|10100] "W" Vector__XXX
 SG_ VCFRONT_evapFdFrwrdTarget m6 : 28|7@1+ (80,0) [0|10100] "W" Vector__XXX
 SG_ VCFRONT_evapFdbk m6 : 35|7@1- (100,-3300) [-9700|3000] "W" Vector__XXX
 SG_ VCFRONT_DIQdotA m6 : 42|7@1+ (80,0) [0|10000] "W" Vector__XXX
 SG_ VCFRONT_evapFdFrwrdTargetMinimum m6 : 49|7@1+ (80,0) [0|10000] "W" Vector__XXX
 SG_ VCFRONT_passiveCoolingState m6 : 56|2@1+ (1,0) [0|3] "" Vector__XXX
 SG_ VCFRONT_totalLoadCoolingDominant m6 : 58|1@1+ (1,0) [0|1] "" Vector__XXX
 SG_ VCFRONT_feedfwdLoadCoolingDomina m6 : 59|1@1+ (1,0) [0|1] "" Vector__XXX
 SG_ VCFRONT_modelLoadCoolingDominant m6 : 60|1@1+ (1,0) [0|1] "" Vector__XXX
 SG_ VCFRONT_hpPotentialLowRefrig m6 : 61|1@1+ (1,0) [0|1] "" Vector__XXX
 SG_ VCFRONT_hpRefrigerantPurgeState m6 : 62|2@1+ (1,0) [0|3] "" Vector__XXX
 SG_ VCFRONT_estPressureLiq m7 : 5|6@1+ (0.5,0) [0|31] "bar" Vector__XXX
 SG_ VCFRONT_estPressureSuct m7 : 11|7@1+ (0.125,0) [0|11.5] "bar" Vector__XXX
 SG_ VCFRONT_estPressureDisch m7 : 18|7@1+ (0.25,0) [0|31.75] "bar" Vector__XXX
 SG_ VCFRONT_estTempLiq m7 : 25|8@1- (0.8,68.8) [-33|170] "degC" Vector__XXX
 SG_ VCFRONT_estTempSuct m7 : 33|6@1- (1,2) [-30|33] "degC" Vector__XXX
 SG_ VCFRONT_estTempDisch m7 : 39|7@1- (1.5,75) [-20|169] "degC" Vector__XXX
 SG_ VCFRONT_estCompressorRpm m7 : 46|9@1+ (30,0) [0|15000] "rpm" Vector__XXX
 SG_ VCFRONT_estQLift m7 : 55|6@1+ (100,0) [0|6300] "W" Vector__XXX
 SG_ VCFRONT_cycleModelConverged m7 : 61|1@1+ (1,0) [0|1] "" Vector__XXX
 SG_ VCFRONT_compStandbyCoastDownMode m7 : 62|1@1+ (1,0) [0|1] "" Vector__XXX
 SG_ VCFRONT_compStandbyShowroomMode m7 : 63|1@1+ (1,0) [0|1] "" Vector__XXX
 SG_ VCFRONT_chillerExvCalibOffset m8 : 5|5@1- (8,0) [-127|120] "ticks" Vector__XXX
 SG_ VCFRONT_evapExvCalibOffset m8 : 10|5@1- (8,0) [-127|120] "ticks" Vector__XXX
 SG_ VCFRONT_recircExvCalibOffset m8 : 15|5@1- (8,0) [-127|120] "ticks" Vector__XXX
 SG_ VCFRONT_lccExvCalibOffset m8 : 20|5@1- (8,0) [-127|120] "ticks" Vector__XXX
 SG_ VCFRONT_ccLeftExvCalibOffset m8 : 25|5@1- (8,0) [-127|120] "ticks" Vector__XXX
 SG_ VCFRONT_ccRightExvCalibOffset m8 : 30|5@1- (8,0) [-127|120] "ticks" Vector__XXX
 SG_ VCFRONT_chillerEXVControlState m8 : 35|3@1+ (1,0) [0|7] "" Vector__XXX
 SG_ VCFRONT_evapEXVControlState m8 : 38|3@1+ (1,0) [0|7] "" Vector__XXX
 SG_ VCFRONT_recircEXVControlState m8 : 41|3@1+ (1,0) [0|7] "" Vector__XXX
 SG_ VCFRONT_lccEXVControlState m8 : 44|3@1+ (1,0) [0|7] "" Vector__XXX
 SG_ VCFRONT_cclEXVControlState m8 : 47|3@1+ (1,0) [0|7] "" Vector__XXX
 SG_ VCFRONT_ccrEXVControlState m8 : 50|3@1+ (1,0) [0|7] "" Vector__XXX
 SG_ VCFRONT_chillerExvCalibFailed m8 : 53|1@1+ (1,0) [0|1] "" Vector__XXX
 SG_ VCFRONT_evapExvCalibFailed m8 : 54|1@1+ (1,0) [0|1] "" Vector__XXX
 SG_ VCFRONT_recircExvCalibFailed m8 : 55|1@1+ (1,0) [0|1] "" Vector__XXX
 SG_ VCFRONT_lccExvCalibFailed m8 : 56|1@1+ (1,0) [0|1] "" Vector__XXX
 SG_ VCFRONT_ccLeftExvCalibFailed m8 : 57|1@1+ (1,0) [0|1] "" Vector__XXX
 SG_ VCFRONT_ccRightExvCalibFailed m8 : 58|1@1+ (1,0) [0|1] "" Vector__XXX
 SG_ VCFRONT_ambientTempSniffActive m8 : 59|1@1+ (1,0) [0|1] "" Vector__XXX
 SG_ VCFRONT_ambientTempPassiveSniffi m8 : 60|1@1+ (1,0) [0|1] "" Vector__XXX
 SG_ VCFRONT_ambientTempRadSampling m8 : 61|1@1+ (1,0) [0|1] "" Vector__XXX
 SG_ VCFRONT_ambientTempSpeedSampling m8 : 62|1@1+ (1,0) [0|1] "" Vector__XXX
 SG_ VCFRONT_feedFwdMDotEvaporator m12 : 5|8@1+ (0.005,0) [0|1] "-" Vector__XXX
 SG_ VCFRONT_hpCabinHeatBatteryHeatAm m12 : 13|1@1+ (1,0) [0|1] "" Vector__XXX
 SG_ VCFRONT_hpCabinHeatBatteryHeatCO m12 : 14|1@1+ (1,0) [0|1] "" Vector__XXX
 SG_ VCFRONT_feedFwdMDotCabinCondense m12 : 15|8@1+ (0.005,0) [0|1] "-" Vector__XXX
 SG_ VCFRONT_feedBackEvapTempControll m12 : 23|7@1+ (0.01,-0.5) [-0.5|0.5] "-" Vector__XXX
 SG_ VCFRONT_feedBackDuctTempControll m12 : 30|8@1+ (0.01,-1) [-1|1] "-" Vector__XXX
 SG_ VCFRONT_isSolenoidAllowed m12 : 38|1@1+ (1,0) [0|1] "" Vector__XXX
 SG_ VCFRONT_maxChillerCoolingPower m12 : 39|8@1+ (100,0) [0|20000] "W" Vector__XXX
 SG_ VCFRONT_fanControlRadCanCool m12 : 47|1@1+ (1,0) [0|1] "" Vector__XXX
 SG_ VCFRONT_fanControlFeedfwdActive m12 : 48|1@1+ (1,0) [0|1] "" Vector__XXX
 SG_ VCFRONT_fanControlRadiatorUa m12 : 49|7@1+ (8,0) [0|1000] "W/C" Vector__XXX
 SG_ VCFRONT_fanControlRadiatorInletT m12 : 56|6@1- (1.8,36) [-20|90] "C" Vector__XXX
 SG_ VCFRONT_hpASBatteryHeatingAllowe m14 : 5|1@1+ (1,0) [0|1] "" Vector__XXX
 SG_ VCFRONT_hpCOP1BatteryHeatingAllo m14 : 6|1@1+ (1,0) [0|1] "" Vector__XXX
 SG_ VCFRONT_hpCabinHeatScavengeOnly m14 : 7|1@1+ (1,0) [0|1] "" Vector__XXX
 SG_ VCFRONT_hpCabinHeatAmbientSource m14 : 8|1@1+ (1,0) [0|1] "" Vector__XXX
 SG_ VCFRONT_hpCabinHeatReheatScaveng m14 : 9|1@1+ (1,0) [0|1] "" Vector__XXX
 SG_ VCFRONT_hpCabinHeatReheatAmbient m14 : 10|1@1+ (1,0) [0|1] "" Vector__XXX
 SG_ VCFRONT_hpCabinHeatBlend m14 : 11|1@1+ (1,0) [0|1] "" Vector__XXX
 SG_ VCFRONT_hpCabinHeatCOP1 m14 : 12|1@1+ (1,0) [0|1] "" Vector__XXX
 SG_ VCFRONT_hpCabinHeatBatteryHeatRe m14 : 13|1@1+ (1,0) [0|1] "" Vector__XXX
 SG_ VCFRONT_hpCabinHeatBatteryCoolRe m14 : 14|1@1+ (1,0) [0|1] "" Vector__XXX
 SG_ VCFRONT_hpCabinCoolEvaporator m14 : 15|1@1+ (1,0) [0|1] "" Vector__XXX
 SG_ VCFRONT_hpCabinCoolEvaporatorReh m14 : 16|1@1+ (1,0) [0|1] "" Vector__XXX
 SG_ VCFRONT_hpBatteryHeatAmbientSour m14 : 17|1@1+ (1,0) [0|1] "" Vector__XXX
 SG_ VCFRONT_hpBatteryHeatCOP1 m14 : 18|1@1+ (1,0) [0|1] "" Vector__XXX
 SG_ VCFRONT_hpBatteryCool m14 : 19|1@1+ (1,0) [0|1] "" Vector__XXX
 SG_ VCFRONT_hpBatteryCoolCabinConden m14 : 20|1@1+ (1,0) [0|1] "" Vector__XXX
 SG_ VCFRONT_hpBatteryCoolCabinC_0001 m14 : 21|1@1+ (1,0) [0|1] "" Vector__XXX
 SG_ VCFRONT_hpBatteryCoolCabinReheat m14 : 22|1@1+ (1,0) [0|1] "" Vector__XXX
 SG_ VCFRONT_hpBatteryCoolEvaporator m14 : 23|1@1+ (1,0) [0|1] "" Vector__XXX
 SG_ VCFRONT_suctionSuperheatEstTsSNA m14 : 24|4@1+ (2,0) [0|30] "degC" Vector__XXX
 SG_ VCFRONT_tempRefrigSuctionEst m14 : 28|6@1- (1.2,0) [-25|37.2] "degC" Vector__XXX
 SG_ VCFRONT_hpBattOverTempHvacDisabl m14 : 34|1@1+ (1,0) [0|1] "" Vector__XXX
 SG_ VCFRONT_hpDiagLouverCalib m14 : 35|1@1+ (1,0) [0|1] "" Vector__XXX
 SG_ VCFRONT_hpDiagHighSideNotNominal m14 : 36|1@1+ (1,0) [0|1] "" Vector__XXX
 SG_ VCFRONT_hpForceModeRadClear m14 : 37|1@1+ (1,0) [0|1] "" Vector__XXX
 SG_ VCFRONT_estPressureDischargeSat m14 : 38|7@1+ (0.25,0) [0|31.75] "bar" Vector__XXX
 SG_ VCFRONT_tempRefrigLiquid m14 : 45|11@1+ (0.125,-40) [-40|150] "degC" Vector__XXX
 SG_ VCFRONT_totalBattHeatingPower m14 : 56|7@1+ (150,0) [0|19050] "W" Vector__XXX
 SG_ VCFRONT_hpPotentialFrozenRadiato m14 : 63|1@1+ (1,0) [0|1] "" Vector__XXX
 SG_ VCFRONT_passiveSeriesRegOn m16 : 5|1@1+ (1,0) [0|1] "" Vector__XXX
 SG_ VCFRONT_passiveDemandRadBypass m16 : 8|7@1+ (1,0) [0|100] "%" Vector__XXX
 SG_ VCFRONT_targetLccActiveCoolCap m16 : 16|7@1+ (1,0) [0|100] "degC" Vector__XXX
 SG_ VCFRONT_targetLccActiveCoolEff m16 : 24|7@1+ (1,0) [0|100] "degC" Vector__XXX
 SG_ VCFRONT_coolantValveDailyAngleTr m16 : 32|7@1+ (60,0) [0|7500] "degrees" Vector__XXX
 SG_ VCFRONT_dischargePressureLimit m16 : 40|7@1+ (0.25,0) [0|26] "bar" Vector__XXX
 SG_ VCFRONT_radMovementBlockActive m16 : 47|1@1+ (1,0) [0|1] "" Vector__XXX
 SG_ VCFRONT_radBypassMoveReason m16 : 48|4@1+ (1,0) [0|15] "" Vector__XXX
 SG_ VCFRONT_hpBattHeatingPower m16 : 52|7@1+ (100,0) [0|10000] "W" Vector__XXX
 SG_ VCFRONT_hpColdStagnationLimit m17 : 8|7@1+ (1,-40) [-40|80] "degC" Vector__XXX
 SG_ VCFRONT_hpHotStagnationLimit m17 : 16|7@1+ (1,-40) [-40|80] "degC" Vector__XXX
 SG_ VCFRONT_hpCompFlowIndex m17 : 23|8@1+ (1,0) [30|255] "-" Vector__XXX
 SG_ VCFRONT_hpCompFlowIndexFiltered m17 : 31|8@1+ (1,0) [30|255] "-" Vector__XXX
 SG_ VCFRONT_subcoolEstTlSNA m17 : 39|6@1- (2,0) [-10|53] "degC" Vector__XXX
 SG_ VCFRONT_subcoolEstPlSNA m17 : 45|6@1- (2,0) [-10|53] "degC" Vector__XXX
 SG_ VCFRONT_tempRefrigLiquidEst m17 : 51|6@1+ (2,0) [0|125] "degC" Vector__XXX
 SG_ VCFRONT_pressureRefrigLiquidEst m17 : 57|6@1+ (0.5,0) [0|31] "bar" Vector__XXX
 SG_ VCFRONT_cmpIsentropicCheckPassed m17 : 63|1@1+ (1,0) [0|1] "" Vector__XXX
 SG_ VCFRONT_louverPosReason m18 : 5|4@1+ (1,0) [0|15] "" Vector__XXX
 SG_ VCFRONT_hpEnergyFlowIndex m18 : 9|8@1+ (4,0) [0|1020] "-" Vector__XXX
 SG_ VCFRONT_hpEnergyFlowIndexFiltere m18 : 17|8@1+ (4,0) [0|1020] "-" Vector__XXX
 SG_ VCFRONT_ductLeftAtSS m18 : 25|1@1+ (1,0) [0|1] "" Vector__XXX
 SG_ VCFRONT_ductRightAtSS m18 : 26|1@1+ (1,0) [0|1] "" Vector__XXX
 SG_ VCFRONT_minCompressorRPMAllowed m18 : 27|7@1+ (90,0) [0|11430] "rpm" Vector__XXX
 SG_ VCFRONT_ccRefrigerantMassFlow m18 : 34|6@1+ (4,0) [0|251] "g/s" Vector__XXX
 SG_ VCFRONT_highSideDpResidual m18 : 40|7@1- (0.1,0) [-6|6] "bar" Vector__XXX
 SG_ VCFRONT_abnormalHighSuctionSuper m18 : 47|1@1+ (1,0) [0|1] "" Vector__XXX
 SG_ VCFRONT_coolantValveAngleTravel m18 : 48|10@1+ (5,0) [0|5000] "degrees" Vector__XXX
 SG_ VCFRONT_chargeShuttleType m18 : 58|2@1+ (1,0) [0|3] "" Vector__XXX
 SG_ VCFRONT_hpRefrigTempSensorCheckC m18 : 60|1@1+ (1,0) [0|1] "" Vector__XXX
 SG_ VCFRONT_hpRefrigPressureSensorCh m18 : 61|1@1+ (1,0) [0|1] "" Vector__XXX
 SG_ VCFRONT_tempSuperheatActFiltered m21 : 5|8@1- (0.25,26.5) [-5|58] "degC" Vector__XXX
 SG_ VCFRONT_tempRefrigDischarge m21 : 13|11@1+ (0.125,-40) [-40|150] "degC" Vector__XXX
 SG_ VCFRONT_pumpBatteryRPMTarget m21 : 24|8@1+ (30,0) [0|7500] "rpm" Vector__XXX
 SG_ VCFRONT_pumpPowertrainRPMTarget m21 : 32|8@1+ (30,0) [0|7500] "rpm" Vector__XXX
 SG_ VCFRONT_coolantFlowChillerTarget m21 : 40|8@1+ (0.161,0) [0|25] "LPM" Vector__XXX
 SG_ VCFRONT_radiatorFanRPMTarget m21 : 48|8@1+ (40,0) [0|10000] "rpm" Vector__XXX
 SG_ VCFRONT_preventReEntryTillNexthp m21 : 59|1@1+ (1,0) [0|1] "" Vector__XXX
 SG_ VCFRONT_chillerBattHeatingPowerA m21 : 60|1@1+ (1,0) [0|1] "" Vector__XXX
 SG_ VCFRONT_isExpectedQChillerVeryHi m21 : 61|1@1+ (1,0) [0|1] "" Vector__XXX
 SG_ VCFRONT_superheatProtectionLimit m25 : 5|10@1+ (0.1,0) [0|60] "degC" Vector__XXX
 SG_ VCFRONT_chillerDemandWatts m25 : 16|8@1+ (100,0) [0|20000] "W" Vector__XXX
 SG_ VCFRONT_nominalTevapHWLimit m25 : 24|7@1+ (0.5,0) [0|60] "degC" Vector__XXX
 SG_ VCFRONT_battCoolEvapEnableDelay m25 : 38|1@1+ (1,0) [0|1] "" Vector__XXX
 SG_ VCFRONT_ambientTempState m25 : 46|2@1+ (1,0) [0|3] "" Vector__XXX
 SG_ VCFRONT_ambientTempUnlatchReason m25 : 48|3@1+ (1,0) [0|7] "" Vector__XXX
 SG_ VCFRONT_compressorSuctionVaporQu m25 : 51|5@1+ (0.01,0.7) [0.7|1] "-" Vector__XXX
 SG_ VCFRONT_cabinHeatingCOP1MinActiv m25 : 56|7@1+ (10,0) [0|1100] "-" Vector__XXX

BO_ 513 VCFRONT_loggingAndVitals10Hz: 8 VCFRONT
 SG_ VCFRONT_loggingAndVitals10HzInde M : 0|3@1+ (1,0) [0|7] "" Vector__XXX
 SG_ VCFRONT_pumpBatteryRPMActual m0 : 8|8@1+ (30,0) [0|7500] "rpm" Vector__XXX
 SG_ VCFRONT_pumpPowertrainRPMActual m0 : 16|8@1+ (30,0) [0|7500] "rpm" Vector__XXX
 SG_ VCFRONT_radiatorFanRPMActual m0 : 24|8@1+ (40,0) [0|10000] "rpm" Vector__XXX
 SG_ VCFRONT_exvFlowTarget m0 : 32|8@1+ (0.5,0) [0|100] "%" Vector__XXX
 SG_ VCFRONT_activeLouverOpenPosTarg m0 : 40|7@1+ (1,0) [0|100] "%" Vector__XXX
 SG_ VCFRONT_pressureRefrigLiquid m0 : 47|9@1+ (0.08,0) [0|37.25] "bar" Vector__XXX
 SG_ VCFRONT_compSleepRequest m0 : 56|1@1+ (1,0) [0|1] "" Vector__XXX
 SG_ VCFRONT_fanDemand m1 : 3|7@1+ (1,0) [0|100] "%" Vector__XXX
 SG_ VCFRONT_compressorState m1 : 10|2@1+ (1,0) [0|3] "" Vector__XXX
 SG_ VCFRONT_compDemandEvap m1 : 12|7@1+ (1,0) [0|100] "%" Vector__XXX
 SG_ VCFRONT_exvState m1 : 19|4@1+ (1,0) [0|15] "" Vector__XXX
 SG_ VCFRONT_solenoidEvapState m1 : 23|2@1+ (1,0) [0|3] "" Vector__XXX
 SG_ VCFRONT_compDemandChiller m1 : 25|7@1+ (1,0) [0|100] "%" Vector__XXX
 SG_ VCFRONT_coolantValveMode m1 : 32|2@1+ (1,0) [0|3] "" Vector__XXX
 SG_ VCFRONT_compFaultSeverity m1 : 34|2@1+ (1,0) [0|3] "" Vector__XXX
 SG_ VCFRONT_solenoidEngaged m1 : 36|1@1+ (1,0) [0|1] "" Vector__XXX
 SG_ VCFRONT_hpHighSideHX m1 : 37|2@1+ (1,0) [0|3] "" Vector__XXX
 SG_ VCFRONT_hpLowSideHX m1 : 39|2@1+ (1,0) [0|3] "" Vector__XXX
 SG_ VCFRONT_hpDominantLoad m1 : 41|3@1+ (1,0) [0|7] "" Vector__XXX
 SG_ VCFRONT_hpBlendType m1 : 44|2@1+ (1,0) [0|3] "" Vector__XXX
 SG_ VCFRONT_hpQuietModeEnabled m1 : 46|1@1+ (1,0) [0|1] "" Vector__XXX
 SG_ VCFRONT_hpCabinLoadType m1 : 47|2@1+ (1,0) [0|3] "" Vector__XXX
 SG_ VCFRONT_hpBatteryLoadType m1 : 49|2@1+ (1,0) [0|3] "" Vector__XXX
 SG_ VCFRONT_hpReqCoolantMode m1 : 51|3@1+ (1,0) [0|7] "" Vector__XXX
 SG_ VCFRONT_hpReqTransScavenge m1 : 54|1@1+ (1,0) [0|1] "" Vector__XXX
 SG_ VCFRONT_compLiqPumpOutState m1 : 55|3@1+ (1,0) [0|7] "" Vector__XXX
 SG_ VCFRONT_frunkStateDBG m1 : 58|4@1+ (1,0) [0|15] "" Vector__XXX
 SG_ VCFRONT_frunkSwitchGroupState m1 : 62|2@1+ (1,0) [0|3] "" Vector__XXX
 SG_ VCFRONT_chillerExvFlow m2 : 3|8@1+ (0.5,0) [0|100] "%" Vector__XXX
 SG_ VCFRONT_evapExvFlow m2 : 11|8@1+ (0.5,0) [0|100] "%" Vector__XXX
 SG_ VCFRONT_recircExvFlow m2 : 19|8@1+ (0.5,0) [0|100] "%" Vector__XXX
 SG_ VCFRONT_lccExvFlow m2 : 27|8@1+ (0.5,0) [0|100] "%" Vector__XXX
 SG_ VCFRONT_cclExvFlow m2 : 35|8@1+ (0.5,0) [0|100] "%" Vector__XXX
 SG_ VCFRONT_ccrExvFlow m2 : 43|8@1+ (0.5,0) [0|100] "%" Vector__XXX
 SG_ VCFRONT_chillerExvState m2 : 51|4@1+ (1,0) [0|15] "" Vector__XXX
 SG_ VCFRONT_evapExvState m2 : 55|4@1+ (1,0) [0|15] "" Vector__XXX
 SG_ VCFRONT_recircExvState m2 : 59|4@1+ (1,0) [0|15] "" Vector__XXX
 SG_ VCFRONT_chillerExvFlowTarget m3 : 3|8@1+ (0.5,0) [0|100] "%" Vector__XXX
 SG_ VCFRONT_evapExvFlowTarget m3 : 11|8@1+ (0.5,0) [0|100] "%" Vector__XXX
 SG_ VCFRONT_recircExvFlowTarget m3 : 19|8@1+ (0.5,0) [0|100] "%" Vector__XXX
 SG_ VCFRONT_lccExvFlowTarget m3 : 27|8@1+ (0.5,0) [0|100] "%" Vector__XXX
 SG_ VCFRONT_cclExvFlowTarget m3 : 35|8@1+ (0.5,0) [0|100] "%" Vector__XXX
 SG_ VCFRONT_ccrExvFlowTarget m3 : 43|8@1+ (0.5,0) [0|100] "%" Vector__XXX
 SG_ VCFRONT_lccExvState m3 : 51|4@1+ (1,0) [0|15] "" Vector__XXX
 SG_ VCFRONT_cclExvState m3 : 55|4@1+ (1,0) [0|15] "" Vector__XXX
 SG_ VCFRONT_ccrExvState m3 : 59|4@1+ (1,0) [0|15] "" Vector__XXX

BO_ 737 VCFRONT_status: 8 VCFRONT
 SG_ VCFRONT_statusIndex M : 0|3@1+ (1,0) [0|7] "" Vector__XXX
 SG_ VCFRONT_homelinkV2Response0 m2 : 8|8@1+ (1,0) [0|255] "" Vector__XXX
 SG_ VCFRONT_homelinkV2Response1 m2 : 16|8@1+ (1,0) [0|255] "" Vector__XXX
 SG_ VCFRONT_homelinkV2Response2 m2 : 24|8@1+ (1,0) [0|255] "" Vector__XXX
 SG_ VCFRONT_homelinkV2Response3 m2 : 32|8@1+ (1,0) [0|255] "" Vector__XXX
 SG_ VCFRONT_homelinkV2Response4 m2 : 40|8@1+ (1,0) [0|255] "" Vector__XXX
 SG_ VCFRONT_homelinkCommStatus m2 : 48|2@1+ (1,0) [1|3] "" Vector__XXX

BO_ 929 VCFRONT_vehicleStatus: 8 VCFRONT
 SG_ VCFRONT_vehicleStatusMuxIndex M : 0|1@1+ (1,0) [0|1] "" Vector__XXX
 SG_ VCFRONT_vehicleStatusCounter : 52|4@1+ (1,0) [0|15] "" Vector__XXX
 SG_ VCFRONT_vehicleStatusChecksum : 56|8@1+ (1,0) [0|255] "" Vector__XXX
 SG_ VCFRONT_preconditionRequest m0 : 1|1@1+ (1,0) [0|1] "" Vector__XXX
 SG_ VCFRONT_APGlassHeaterState m0 : 2|3@1+ (1,0) [1|7] "" Vector__XXX
 SG_ VCFRONT_thermalSystemType m0 : 5|1@1+ (1,0) [0|1] "" Vector__XXX
 SG_ VCFRONT_standbySupplySupported m0 : 6|1@1+ (1,0) [0|1] "" Vector__XXX
 SG_ VCFRONT_driverPresent m0 : 7|1@1+ (1,0) [0|1] "" Vector__XXX
 SG_ VCFRONT_passengerPresent m0 : 8|1@1+ (1,0) [0|1] "" Vector__XXX
 SG_ VCFRONT_accPlusAvailable m0 : 9|1@1+ (1,0) [0|1] "" Vector__XXX
 SG_ VCFRONT_diPowerOnState m0 : 10|3@1+ (1,0) [0|7] "" Vector__XXX
 SG_ VCFRONT_12vStatusForDrive m0 : 14|2@1+ (1,0) [0|3] "" Vector__XXX
 SG_ VCFRONT_dcr12VMilliOhms m0 : 16|8@1+ (1,0) [0|255] "mOhm" Vector__XXX
 SG_ VC_userPresenceState m0 : 24|2@1+ (1,0) [0|3] "" Vector__XXX
 SG_ VCFRONT_factoryLimitsOverrideOk m0 : 27|1@1+ (1,0) [0|1] "" Vector__XXX
 SG_ VCFRONT_ota12VSupportRequest m0 : 29|1@1+ (1,0) [0|1] "" Vector__XXX
 SG_ VCFRONT_driverBuckleStatus m0 : 30|1@1+ (1,0) [0|1] "" Vector__XXX
 SG_ VCFRONT_driverDoorStatus m0 : 31|1@1+ (1,0) [0|1] "" Vector__XXX
 SG_ VCFRONT_driverUnbuckled m0 : 32|2@1+ (1,0) [0|3] "" Vector__XXX
 SG_ VCFRONT_passengerUnbuckled m0 : 34|2@1+ (1,0) [0|3] "" Vector__XXX
 SG_ VCFRONT_2RowLeftUnbuckled m0 : 36|2@1+ (1,0) [0|3] "" Vector__XXX
 SG_ VCFRONT_2RowCenterUnbuckled m0 : 38|2@1+ (1,0) [0|3] "" Vector__XXX
 SG_ VCFRONT_2RowRightUnbuckled m0 : 40|2@1+ (1,0) [0|3] "" Vector__XXX
 SG_ VCFRONT_pcsEFuseVoltage m0 : 42|10@1+ (0.1,0) [0|102.2] "V" Vector__XXX
 SG_ VCFRONT_bmsHvChargeEnable m1 : 1|1@1+ (1,0) [0|1] "" Vector__XXX
 SG_ VCFRONT_3RowLeftUnbuckled m1 : 2|2@1+ (1,0) [0|3] "" Vector__XXX
 SG_ VCFRONT_3RowRightUnbuckled m1 : 4|2@1+ (1,0) [0|3] "" Vector__XXX
 SG_ VCFRONT_maxBattHeatRejection m1 : 6|10@1+ (30,0) [0|30690] "W" Vector__XXX
 SG_ VCFRONT_hvacReqBattCoolOutTemp m1 : 16|9@1+ (0.1,40) [40|91.1] "degC" Vector__XXX
 SG_ VCFRONT_PCSCurrent m1 : 25|13@1- (0.1,0) [-409.6|409.5] "A" Vector__XXX
 SG_ VCFRONT_refSystemNominal m1 : 38|1@1+ (1,0) [0|1] "" Vector__XXX
 SG_ VCFRONT_driverEnteredCabinEstima m1 : 39|1@1+ (1,0) [0|1] "" Vector__XXX
 SG_ VCFRONT_anySWEFuseActive m1 : 40|1@1+ (1,0) [0|1] "" Vector__XXX
 SG_ VCFRONT_hpBattHeatingPowerTrgt m1 : 41|7@1+ (100,0) [0|10000] "W" Vector__XXX

BO_ 258 VCLEFT_doorStatus: 8 VCLEFT
 SG_ VCLEFT_doorClosureStatusFront : 0|4@1+ (1,0) [1|15] "" Vector__XXX
 SG_ VCLEFT_doorClosureStatusRear : 4|4@1+ (1,0) [1|15] "" Vector__XXX
 SG_ VCLEFT_frontLatchSwitch : 8|1@1+ (1,0) [0|1] "" Vector__XXX
 SG_ VCLEFT_rearLatchSwitch : 9|1@1+ (1,0) [0|1] "" Vector__XXX
 SG_ VCLEFT_frontHandlePulled : 10|1@1+ (1,0) [0|1] "" Vector__XXX
 SG_ VCLEFT_rearHandlePulled : 11|1@1+ (1,0) [0|1] "" Vector__XXX
 SG_ VCLEFT_frontRelActuatorSwitch : 12|1@1+ (1,0) [0|1] "" Vector__XXX
 SG_ VCLEFT_rearRelActuatorSwitch : 13|1@1+ (1,0) [0|1] "" Vector__XXX
 SG_ VCLEFT_frontLatchStatus : 14|4@1+ (1,0) [1|15] "" Vector__XXX
 SG_ VCLEFT_rearLatchStatus : 18|4@1+ (1,0) [1|15] "" Vector__XXX
 SG_ VCLEFT_lastDoorReqSourceFront : 22|3@1+ (1,0) [0|7] "" Vector__XXX
 SG_ VCLEFT_lastDoorReqSourceRear : 25|3@1+ (1,0) [0|7] "" Vector__XXX
 SG_ VCLEFT_frontIntSwitchPressed : 31|1@1+ (1,0) [0|1] "" Vector__XXX
 SG_ VCLEFT_rearIntSwitchPressed : 32|1@1+ (1,0) [0|1] "" Vector__XXX
 SG_ VCLEFT_mirrorTiltXPosition : 33|8@1+ (0.02,0) [0|5] "V" Vector__XXX
 SG_ VCLEFT_mirrorTiltYPosition : 41|8@1+ (0.02,0) [0|5] "V" Vector__XXX
 SG_ VCLEFT_mirrorState : 49|3@1+ (1,0) [0|7] "" Vector__XXX
 SG_ VCLEFT_mirrorFoldState : 52|3@1+ (1,0) [0|7] "" Vector__XXX
 SG_ VCLEFT_mirrorRecallState : 55|3@1+ (1,0) [0|7] "" Vector__XXX
 SG_ VCLEFT_mirrorHeatState : 58|3@1+ (1,0) [1|7] "" Vector__XXX
 SG_ VCLEFT_rearHandlePulledPersist : 61|1@1+ (1,0) [0|1] "" Vector__XXX
 SG_ VCLEFT_frontHandlePulledPersist : 62|1@1+ (1,0) [0|1] "" Vector__XXX
 SG_ VCLEFT_mirrorDipped : 63|1@1+ (1,0) [0|1] "" Vector__XXX

BO_ 626 VCLEFT_epbmDebug: 8 VCLEFT
 SG_ VCLEFT_epbmDebugIndex M : 0|1@1+ (1,0) [0|1] "" Vector__XXX
 SG_ VCLEFT_epbmCaliperState m0 : 1|3@1+ (1,0) [0|7] "" Vector__XXX
 SG_ VCLEFT_epbmMotorEnabled m0 : 4|1@1+ (1,0) [0|1] "" Vector__XXX
 SG_ VCLEFT_epbMotorCurrent m0 : 5|11@1+ (0.01,0) [0|20.47] "A" Vector__XXX
 SG_ VCLEFT_epbmApplyVoltage m0 : 16|11@1+ (0.01,0) [0|20.47] "A" Vector__XXX
 SG_ VCLEFT_epbmReleaseVoltage m0 : 27|11@1+ (0.01,0) [0|20.47] "A" Vector__XXX
 SG_ VCLEFT_summonFaultReason m0 : 40|5@1+ (1,0) [0|31] "" Vector__XXX
 SG_ VCLEFT_epbSummonState m0 : 45|3@1+ (1,0) [0|7] "" Vector__XXX
 SG_ VCLEFT_epbmSummonState m0 : 48|3@1+ (1,0) [0|7] "" Vector__XXX
 SG_ VCLEFT_epbUnitStatus m0 : 51|5@1+ (1,0) [0|31] "" Vector__XXX
 SG_ VCLEFT_epbmFaultStatus m0 : 56|2@1+ (1,0) [0|3] "" Vector__XXX
 SG_ VCLEFT_epbFaultStatus m0 : 58|2@1+ (1,0) [0|3] "" Vector__XXX
 SG_ VCLEFT_epbmSystemStatus m0 : 60|4@1+ (1,0) [0|15] "" Vector__XXX

BO_ 1140 VCLEFT_epbmStatus: 8 VCLEFT
 SG_ VCLEFT_cdpRequestState : 0|1@1+ (1,0) [0|1] "" Vector__XXX
 SG_ VCLEFT_epbmSystemStatusQF : 3|1@1+ (1,0) [0|1] "" Vector__XXX
 SG_ VCLEFT_epbmUnitStatus : 4|5@1+ (1,0) [0|31] "" Vector__XXX
 SG_ VCLEFT_epbmCdpState : 9|2@1+ (1,0) [0|3] "" Vector__XXX
 SG_ VCLEFT_epbmStatusCounter : 52|4@1+ (1,0) [0|15] "" Vector__XXX
 SG_ VCLEFT_epbmStatusChecksum : 56|8@1+ (1,0) [0|255] "" Vector__XXX

BO_ 770 VCLEFT_info: 8 VCLEFT
 SG_ VCLEFT_infoIndex M : 0|8@1+ (1,0) [0|255] "" Vector__XXX
 SG_ VCLEFT_infoBuildType m10 : 8|3@1+ (1,0) [0|7] "" Vector__XXX
 SG_ VCLEFT_infoBuildConfigId m10 : 16|16@1+ (1,0) [0|65535] "" Vector__XXX
 SG_ VCLEFT_infoHardwareId m10 : 32|16@1+ (1,0) [0|65535] "" Vector__XXX
 SG_ VCLEFT_infoComponentId m10 : 48|16@1+ (1,0) [0|65535] "" Vector__XXX
 SG_ VCLEFT_infoPcbaId m11 : 8|8@1+ (1,0) [0|255] "" Vector__XXX
 SG_ VCLEFT_infoAssemblyId m11 : 16|8@1+ (1,0) [0|254] "" Vector__XXX
 SG_ VCLEFT_infoUsageId m11 : 24|16@1+ (1,0) [0|65535] "" Vector__XXX
 SG_ VCLEFT_infoSubUsageId m11 : 40|16@1+ (1,0) [0|65535] "" Vector__XXX
 SG_ VCLEFT_infoAppCrc m13 : 8|32@1+ (1,0) [0|4294967295] "" Vector__XXX
 SG_ VCLEFT_infoAppGitHash m17 : 8|56@1+ (1,0) [0|7.20575940379e+16] "" Vector__XXX
 SG_ VCLEFT_infoBootGitHash m18 : 8|56@1+ (1,0) [0|7.20575940379e+16] "" Vector__XXX
 SG_ VCLEFT_infoPlatformType m19 : 8|8@1+ (1,0) [0|255] "" Vector__XXX
 SG_ VCLEFT_infoBootUdsProtoVersion m20 : 8|16@1+ (1,0) [0|65535] "" Vector__XXX
 SG_ VCLEFT_infoBootCrc m20 : 24|32@1+ (1,0) [0|4294967295] "" Vector__XXX

BO_TX_BU_ 628 : UI;
BO_TX_BU_ 853 : UI;
BO_TX_BU_ 644 : UI;
BO_TX_BU_ 595 : UI;
BO_TX_BU_ 609 : VCFRONT;
BO_TX_BU_ 2017 : VCFRONT;
BO_TX_BU_ 2016 : VCFRONT;
BO_TX_BU_ 545 : VCFRONT;
BO_TX_BU_ 753 : VCFRONT;
BO_TX_BU_ 769 : VCFRONT;
BO_TX_BU_ 1801 : VCFRONT;
BO_TX_BU_ 705 : VCFRONT;
BO_TX_BU_ 897 : VCFRONT;
BO_TX_BU_ 513 : VCFRONT;
BO_TX_BU_ 737 : VCFRONT;
BO_TX_BU_ 929 : VCFRONT;
BO_TX_BU_ 258 : VCLEFT;
BO_TX_BU_ 626 : VCLEFT;
BO_TX_BU_ 1140 : VCLEFT;
BO_TX_BU_ 770 : VCLEFT;
CM_ BO_ 628 "Touchscreen user interface computer message: vehicle control3";
CM_ SG_ 628 UI_lightFlashRequest "UI flash lights request";
CM_ SG_ 628 UI_phoneCallActive "On phone call via Bluetooth if active";
CM_ SG_ 628 UI_lightShowClosuresEnabled "Closure movements enabled during light show";
CM_ SG_ 628 UI_steeringWheelHeatAutoReq "UI setting to request auto steering wheel heat";
CM_ SG_ 628 UI_steeringWheelHeatLevelReq "Request for steering wheel heat";
CM_ SG_ 628 UI_headlightPulseRequest "Request headlights to pulse";
CM_ SG_ 628 UI_displayRedShiftActive "UI's reduce blue light setting is active";
CM_ SG_ 628 UI_fasciaCameraWashRequest "User request to activate fascia camera wash";
CM_ SG_ 628 UI_leftRearSeatAdjustmentRequest "Reports request from UI to actuate the left rear seat";
CM_ SG_ 628 UI_rightRearSeatAdjustmentReques "Reports request from UI to actuate the right rear seat";
CM_ SG_ 628 UI_blindSpotIndicatorLightReques "Request for blind spot indicator light";
CM_ SG_ 628 UI_keepOnAccessoryPortsReq "User setting to keep 12V outlets, USB ports, and phone chargers powered in CONDITIONING";
CM_ SG_ 628 UI_fasciaCameraShown "Whether the UI is currently showing the fascia camera view";
CM_ SG_ 628 UI_rearSeatChildLock "Reports the state of second row seat fold flat child lock from the UI";
CM_ SG_ 628 UI_windowPercentageRequest "Reports the window percentage value when window request is WINDOW_REQUEST_GOTO_PERCENT.";
CM_ SG_ 628 UI_windowRequestedFL "Reports that the front left window is requested.";
CM_ SG_ 628 UI_windowRequestedFR "Reports that the front right window is requested.";
CM_ SG_ 628 UI_windowRequestedRL "Reports that the rear left window is requested.";
CM_ SG_ 628 UI_windowRequestedRR "Reports that the rear right window is requested.";
CM_ SG_ 628 UI_windowRequest "Window operation request from the mobile app.";
CM_ SG_ 628 UI_closeTrunkRequest "Explicity request for the rear trunk to close";
CM_ SG_ 628 UI_childPresenceDetectionDisable "User request to disable child presence detection behaviors until the next drive cycle";
CM_ SG_ 628 UI_derivedLoadshedFeature "Reports whether vehicle controllers should enable derived loadshed feature.";
CM_ SG_ 628 UI_selfParkStandingBy "Reports that summon is in standby.";
CM_ BO_ 853 "Touchscreen user interface computer message: vehicle control thermal";
CM_ SG_ 853 UI_coolantFlowRequest "request for coolant flow to MCU in LPM";
CM_ SG_ 853 UI_inletActiveCoolTarget "request for coolant temperature at Car Computer inlet";
CM_ SG_ 853 UI_disableHVPTThermalLoads "Request thermal system to disable active battery heating";
CM_ BO_ 644 "Touchscreen user interface computer message: vehicle modes";
CM_ SG_ 644 UI_transportMode "Reports UI Transport mode. Distinct from GTW transport mode.";
CM_ SG_ 644 UI_showroomMode "Reports UI showroom mode.";
CM_ SG_ 644 UI_serviceMode "Service diagnostics mode active";
CM_ SG_ 644 UI_carWashMode "Car Wash Mode";
CM_ SG_ 644 UI_gameMode "Game mode";
CM_ SG_ 644 UI_serviceModePlus "Extended service diagnostics mode active";
CM_ SG_ 644 UI_premiumAmpPowerOff "Premium amplifier power off request";
CM_ SG_ 644 UI_lightShowType "Type of the light show to be run";
CM_ BO_ 595 "Touchscreen user interface computer message: vent panel control request";
CM_ SG_ 595 UI_ventPanelControlRequestIndex "Touchscreen user interface computer: vent panel control request index";
CM_ SG_ 595 UI_ventPanelLeftPositionX "Airwave left X position.";
CM_ SG_ 595 UI_ventPanelLeftPositionY "Airwave left Y position.";
CM_ SG_ 595 UI_ventPanelLeftLateralSplit "Airwave left split amount.";
CM_ SG_ 595 UI_ventPanelRightPositionX "Airwave right X position.";
CM_ SG_ 595 UI_ventPanelRightPositionY "Airwave right Y position.";
CM_ SG_ 595 UI_ventPanelRightLateralSplit "Airwave right split amount.";
CM_ SG_ 595 UI_ventPanelLeftLateralMode "Airwave left focus or split.";
CM_ SG_ 595 UI_ventPanelRightLateralMode "Airwave right focus or split.";
CM_ SG_ 595 UI_hvacReqActiveVents "Active airwave sides - left/right/both";
CM_ SG_ 595 UI_vent2RLeftPositionX "Airwave left X position.";
CM_ SG_ 595 UI_vent2RLeftPositionY "Airwave left Y position.";
CM_ SG_ 595 UI_vent2RRightPositionX "Airwave left X position.";
CM_ SG_ 595 UI_vent2RRightPositionY "Airwave left Y position.";
CM_ BO_ 609 "Front body controller message: 12 v battery status";
CM_ SG_ 609 VCFRONT_12VBatteryStatusIndex "Front body controller: 12 v battery status index";
CM_ SG_ 609 VCFRONT_good12VforUpdate "Indicates the Low Voltage (LV) battery health as it pertains to permitting an Over-The-Air (OTA) update.";
CM_ SG_ 609 VCFRONT_LVLoadRequest "Controls the loading of the Low Voltage (LV) battery for diagnostic purposes.";
CM_ SG_ 609 VCFRONT_12VBatteryStatusCounter "Front body controller: 12 v battery status counter";
CM_ SG_ 609 VCFRONT_12VBatteryStatusChecksum "Front body controller: 12 v battery status checksum";
CM_ SG_ 609 VCFRONT_batterySupportRequest "Reports the request to the Power Conversion System (PCS) to supply power to the Low Voltage (LV) battery.";
CM_ SG_ 609 VCFRONT_batterySMState "Reports the Low Voltage (LV) battery maintenance state machine state.";
CM_ SG_ 609 VCFRONT_eFuseRecoveryStateDBG "Reports the state of the Low Voltage (LV) battery eFuse recovery state machine.";
CM_ SG_ 609 VCFRONT_batteryLINScheduleDBG "Front body controller: battery LIN schedule DBG; raw 7 = signal not available (SNA)";
CM_ SG_ 609 VCFRONT_resistanceEstimationTest "Front body controller: resistance estimation test counter";
CM_ SG_ 609 VCFRONT_IBSCurrent "Electrical current into the 12V battery";
CM_ SG_ 609 VCFRONT_IBSVoltage "Voltage of the 12V battery; raw 4095 = signal not available (SNA)";
CM_ SG_ 609 VCFRONT_reverseBatteryFault "Indicates a fault on the reverse battery eFuse.";
CM_ SG_ 609 VCFRONT_LVBatterySupported "Indicates whether the Low Voltage (LV) battery is being supported.";
CM_ SG_ 609 VCFRONT_LVBatteryCannotSupportVe "Front body controller: LV battery cannot support vehicle";
CM_ SG_ 609 VCFRONT_goodTemp12VforUpdate "Front body controller: good temp12 vfor update";
CM_ SG_ 609 VCFRONT_12VBatteryTargetVoltage "Reports the target Low Voltage (LV) battery voltage.";
CM_ SG_ 609 VCFRONT_IBSTemperature "Front body controller: IBS temperature; raw 2047 = signal not available (SNA)";
CM_ SG_ 609 VCFRONT_currentSensorMismatchLea "Front body controller: current sensor mismatch leaky bkt pct DBG";
CM_ SG_ 609 VCFRONT_LVBatteryEnergyRemaining "Reports the percentage of energy remaining in the Low Voltage (LV) battery.";
CM_ SG_ 609 VCFRONT_LVBatteryStatusForDrive "Indicates the Low Voltage (LV) battery health status as it pertains to drive readiness. May trigger a Graceful Power Off (GPO) and block drive.";
CM_ SG_ 609 VCFRONT_LVBatteryType "Reports the type of Low Voltage (LV) battery that the firmware is configured for.";
CM_ SG_ 609 VCFRONT_resistanceEstimationNeed "Indication that the conditions which require a resistance estimation test to be performed have been met";
CM_ SG_ 609 VCFRONT_IBSVoltageFiltered "Measures the filtered voltage of the Low Voltage (LV) bus; raw 16383 = signal not available (SNA)";
CM_ SG_ 609 VCFRONT_LVBMS_LVBusVoltageSource "Reports the source of the Low Voltage (LV) bus voltage used for the Low Voltage Battery Management System (LVBMS).";
CM_ SG_ 609 VCFRONT_LVBMS_LVPackCurrentSourc "Reports the source of the Low Voltage (LV) pack current used for LV battery charge regulation.";
CM_ SG_ 609 VCFRONT_LVBatterySupportRqrdTrig "Reports what caused the Low Voltage (LV) battery support required trigger when the vehicle wakes to charge.";
CM_ SG_ 609 VCFRONT_goodForPCSPowerCycleLeak "Front body controller: good for PCS power cycle leaky bkt DBG";
CM_ SG_ 609 VCFRONT_LVBusControlsFutile "Indicates that a required condition is not met for the Low Voltage (LV) bus controllers to operate properly.";
CM_ SG_ 609 VCFRONT_resistanceEstimatio_0001 "Front body controller: resistance estimation test valid";
CM_ SG_ 609 VCFRONT_resistanceEstimatio_0002 "Front body controller: resistance estimation tests expended";
CM_ SG_ 609 VCFRONT_goodLVChargeForUpdate "Indicates that the Low Voltage (LV) battery charge is sufficient to permit an Over-The-Air (OTA) update.";
CM_ SG_ 609 VCFRONT_opportunisticDCRTestNeed "Front body controller: opportunistic DCR test needed";
CM_ SG_ 609 VCFRONT_voltageProfile "Indicates which voltage profile is used to support the 12V battery";
CM_ SG_ 609 VCFRONT_IBSAmpHours "Measures the energy state of the Low Voltage (LV) battery in amp hours.";
CM_ SG_ 609 VCFRONT_IBSVoltageRawDBG "Front body controller: IBS voltage raw DBG; raw 16383 = signal not available (SNA)";
CM_ SG_ 609 VCFRONT_LVBatteryLINCommsDetecte "Front body controller: LV battery LIN comms detected DBG";
CM_ SG_ 609 VCFRONT_voltageSensorMismatchLea "Front body controller: voltage sensor mismatch leaky bkt pct DBG";
CM_ SG_ 609 VCFRONT_LVBatteryFctryLimOverrid "Front body controller: LV battery fctry lim override ok";
CM_ SG_ 609 VCFRONT_LVBatterySPICommsDetecte "Front body controller: LV battery SPI comms detected DBG";
CM_ SG_ 609 VCFRONT_targetCurrent "Reports the target current set by the Low Voltage Battery Management System (LVBMS).";
CM_ SG_ 609 VCFRONT_PCSMia "Indicates that the Power Conversion System (PCS) is not communicating on CAN.";
CM_ SG_ 609 VCFRONT_chargeNeeded "Indicates that the Low Voltage (LV) battery needs to be charged.";
CM_ SG_ 609 VCFRONT_voltageControlLoopIntegr "Front body controller: voltage control loop integration val";
CM_ SG_ 609 VCFRONT_currentControlLoopIntegr "Front body controller: current control loop integration val";
CM_ BO_ 2017 "Front body controller message: LV health";
CM_ SG_ 2017 VCFRONT_LVHealthStatus "Health status of the LV system";
CM_ SG_ 2017 VCFRONT_LVStatusForDrive "Front body controller: LV status for drive";
CM_ SG_ 2017 VCFRONT_LVPowerSecondsToSafeHarb "Reports the amount of time (in seconds) the Low Voltage (LV) power system indicates the vehicle has to achieve safe harbor.";
CM_ SG_ 2017 VCFRONT_LVHealthCounter "Front body controller: LV health counter";
CM_ SG_ 2017 VCFRONT_LVHealthChecksum "Front body controller: LV health checksum";
CM_ BO_ 2016 "Front body controller message: LV health debug";
CM_ SG_ 2016 VCFRONT_LVHealthDebugIndex "Front body controller: LV health debug index";
CM_ SG_ 2016 VCFRONT_LVHEALTH_placeholder "Whether the LV health has determined that the <placeholder>";
CM_ SG_ 2016 VCFRONT_LVHEALTH_activeDecelEner "Whether the VCFRONT cannot confirm that the battery has sufficient energy to support an active decel scenario";
CM_ SG_ 2016 VCFRONT_LVHEALTH_criticalPullove "Whether the VCFRONT cannot confirm that the battery has sufficient energy to support a critical pullover scenario";
CM_ SG_ 2016 VCFRONT_LVHEALTH_revBattEFuseOff "Whether the LV health has determined that the LVBMB EFuse has opened";
CM_ SG_ 2016 VCFRONT_LVHEALTH_LVBMBEFuseOpen "Whether the LV health has determined that the LVBMB EFuse has opened";
CM_ SG_ 2016 VCFRONT_LVHEALTH_lvBatteryCommsM "Whether the LV health has determined that LV battery communications are missing";
CM_ SG_ 2016 VCFRONT_LVHEALTH_pcsEFuseOff "Whether VCFRONT has determined that the PCS eFuse is off or faulted when it's needed to be on";
CM_ SG_ 2016 VCFRONT_LVHEALTH_pcsNotActive "Whether the LV health has determined that the PCS is not actively providing LV support";
CM_ SG_ 2016 VCFRONT_LVHEALTH_pcsMIA "Whether the LV health has determined that messages are missing from PCS critical for determining health";
CM_ SG_ 2016 VCFRONT_LVHEALTH_IBSMIA "Whether the LV health has determined that the INA228 LV battery sensor signals are invalid or not yet configured";
CM_ SG_ 2016 VCFRONT_LVHEALTH_LVBatteryElecDi "Whether the VCFRONT has determined that the LV battery is electrically disconnected";
CM_ SG_ 2016 VCFRONT_LVHEALTH_LVBatteryE_0001 "Whether the VCFRONT has determined that the LV battery electrical connection status has been unknown for too long";
CM_ SG_ 2016 VCFRONT_LVHEALTH_pcsOpenCircuit "Whether VCFRONT has determined that the electrical connection between the PCS and VCFRONT is disconnected";
CM_ SG_ 2016 VCFRONT_LVHEALTH_activeDecelPowe "Whether the VCFRONT cannot confirm that the battery has sufficient power to support a active decel scenario";
CM_ SG_ 2016 VCFRONT_LVHEALTH_lvBatteryCapabi "Whether the LV health has determined that LV battery power/energy capability estimation accuracy is too low";
CM_ SG_ 2016 VCFRONT_LVHEALTH_lvBatteryConfig "Whether the LV health has determined that LV battery configuration is incorrect";
CM_ SG_ 2016 VCFRONT_LVHEALTH_lvBatteryImpeda "Whether the LV health has determined that LV battery impedance is too high";
CM_ BO_ 545 "Front body controller message: LV power state";
CM_ SG_ 545 VCFRONT_LVPowerStateIndex "Front body controller: LV power state index";
CM_ SG_ 545 VCFRONT_vehiclePowerState "Front body controller: vehicle power state";
CM_ SG_ 545 VCFRONT_inAccessoryPlus "Front body controller: in accessory plus";
CM_ SG_ 545 VCFRONT_LVShuttingDown "Front body controller: LV shutting down";
CM_ SG_ 545 VCFRONT_LVPowerStateCounter "Front body controller: LV power state counter";
CM_ SG_ 545 VCFRONT_LVPowerStateChecksum "Front body controller: LV power state checksum";
CM_ SG_ 545 VCFRONT_cpLVRequest "Front body controller: cp LV request";
CM_ SG_ 545 VCFRONT_epasLVState "Front body controller: epas LV state";
CM_ SG_ 545 VCFRONT_hvcLVRequest "Front body controller: hvc LV request";
CM_ SG_ 545 VCFRONT_tasLVState "Front body controller: tas LV state";
CM_ SG_ 545 VCFRONT_pcsLVState "Front body controller: pcs LV state";
CM_ SG_ 545 VCFRONT_CMPDLVState "Front body controller: CMPDLV state";
CM_ SG_ 545 VCFRONT_hcmlLVState "Front body controller: hcml LV state";
CM_ SG_ 545 VCFRONT_hcmrLVState "Front body controller: hcmr LV state";
CM_ SG_ 545 VCFRONT_MCUAudioLVState "Front body controller: MCU audio LV state";
CM_ SG_ 545 VCFRONT_espValveLVState "Front body controller: esp valve LV state";
CM_ SG_ 545 VCFRONT_MCUGraphicsLVState "Front body controller: MCU graphics LV state";
CM_ SG_ 545 VC_dcdcSupportRequest "Front body controller: dcdc support request";
CM_ SG_ 545 VC_hvStateRequest "Reports the request for the High Voltage (HV) system state.";
CM_ SG_ 545 VC_persistAccPowerRequestOverrid "Front body controller: persist acc power request overridden";
CM_ SG_ 545 VC_accPortPowerRequest "Front body controller: acc port power request";
CM_ SG_ 545 VC_persistAccPortPowerState "Front body controller: persist acc port power state";
CM_ BO_ 753 "Front body controller message: e fuse debug status";
CM_ SG_ 753 VCFRONT_eFuseDebugStatusIndex "Front body controller: e fuse debug status index";
CM_ SG_ 753 VCFRONT_leftControllerState "Front body controller: left controller state; raw 3 = signal not available (SNA)";
CM_ SG_ 753 VCFRONT_leftControllerFault "Front body controller: left controller fault";
CM_ SG_ 753 VCFRONT_vcleftSelfTestResult "Reports the result of the most recent self-test of the Vehicle Controller Left (VCLEFT) eFuse; raw 12 = signal not available (SNA)";
CM_ SG_ 753 VCFRONT_leftControllerTemp "Front body controller: left controller temp";
CM_ SG_ 753 VCFRONT_leftControllerEFuseVNFSt "State of the leftController eFuse";
CM_ SG_ 753 VCFRONT_leftControllerEFuseOutpu "Output state of the leftController efuse";
CM_ SG_ 753 VCFRONT_leftControllerEFuse_0002 "Output of the leftController efuse";
CM_ SG_ 753 VCFRONT_leftControllerVoltage "Front body controller: left controller voltage";
CM_ SG_ 753 VCFRONT_leftControllerEFuseBypas "Bypass output state of the leftController efuse";
CM_ SG_ 753 VCFRONT_leftControllerEFuse_0001 "Bypass output of the leftController efuse";
CM_ SG_ 753 VCFRONT_leftControllerCurrent "Front body controller: left controller current";
CM_ SG_ 753 VCFRONT_leftControllerEFuseVNFSe "Front body controller: left controller e fuse VNF self test status";
CM_ SG_ 753 VCFRONT_PCSState "Front body controller: PCS state; raw 3 = signal not available (SNA)";
CM_ SG_ 753 VCFRONT_PCSFault "Front body controller: PCS fault";
CM_ SG_ 753 VCFRONT_pcsSelfTestResult "Reports the result of the most recent self-test of the Power Conversion System (PCS) eFuse; raw 12 = signal not available (SNA)";
CM_ SG_ 753 VCFRONT_PCSTemp "Front body controller: PCS temp";
CM_ SG_ 753 VCFRONT_PCSEFuseVNFState "State of the PCS eFuse";
CM_ SG_ 753 VCFRONT_PCSEFuseOutput "Output state of the PCS efuse";
CM_ SG_ 753 VCFRONT_PCSEFuseOutputDesired "Output of the PCS efuse";
CM_ SG_ 753 VCFRONT_PCSVoltage "Voltage of the power conversion system circuit";
CM_ SG_ 753 VCFRONT_PCSEFuseBypass "Bypass output state of the PCS efuse";
CM_ SG_ 753 VCFRONT_PCSEFuseBypassDesired "Bypass output of the PCS efuse";
CM_ SG_ 753 VCFRONT_PCSEFuseVNFSelfTestStatu "Front body controller: PCSE fuse VNF self test status";
CM_ SG_ 753 VCFRONT_iBoosterState "Front body controller: i booster state; raw 3 = signal not available (SNA)";
CM_ SG_ 753 VCFRONT_iBoosterFault "Front body controller: i booster fault";
CM_ SG_ 753 VCFRONT_iBoosterSelfTestResult "Reports the result of the most recent self-test of the iBooster eFuse; raw 12 = signal not available (SNA)";
CM_ SG_ 753 VCFRONT_iBoosterTemp "Front body controller: i booster temp";
CM_ SG_ 753 VCFRONT_iBoosterVoltage "Front body controller: i booster voltage";
CM_ SG_ 753 VCFRONT_iBoosterCurrent "Front body controller: i booster current";
CM_ SG_ 753 VCFRONT_EPAS3PState "State of the primary power steering circuit; raw 3 = signal not available (SNA)";
CM_ SG_ 753 VCFRONT_EPAS3PFault "Front body controller: EPAS3 p fault";
CM_ SG_ 753 VCFRONT_EPAS3PSelfTestResult "Reports the result of the most recent self-test of the Electric Power Assisted Steering Primary (EPAS3P) eFuse; raw 12 = signal not available (SNA)";
CM_ SG_ 753 VCFRONT_EPAS3PTemp "Front body controller: EPAS3 p temp";
CM_ SG_ 753 VCFRONT_EPAS3PEFuseVNFState "State of the EPAS3P eFuse";
CM_ SG_ 753 VCFRONT_EPAS3PEFuseOutput "Output state of the EPAS3P efuse";
CM_ SG_ 753 VCFRONT_EPAS3PEFuseOutputDesired "Output of the EPAS3P efuse";
CM_ SG_ 753 VCFRONT_EPAS3PVoltage "Voltage of the primary power steering circuit";
CM_ SG_ 753 VCFRONT_EPAS3PEFuseHardshortThre "Front body controller: EPAS3 PE fuse hardshort threshold dbg";
CM_ SG_ 753 VCFRONT_EPAS3PEFuseBypass "Bypass output state of the EPAS3P efuse";
CM_ SG_ 753 VCFRONT_EPAS3PEFuseBypassDesired "Bypass output of the EPAS3P efuse";
CM_ SG_ 753 VCFRONT_EPAS3PCurrent "Electrical current of the primary power steering circuit";
CM_ SG_ 753 VCFRONT_EPAS3PEFuseVNFSelfTestSt "Front body controller: EPAS3 PE fuse VNF self test status";
CM_ SG_ 753 VCFRONT_EPAS3SState "State of the secondary power steering circuit; raw 3 = signal not available (SNA)";
CM_ SG_ 753 VCFRONT_EPAS3SFault "Front body controller: EPAS3 s fault";
CM_ SG_ 753 VCFRONT_EPAS3SSelfTestResult "Reports the result of the most recent self-test of the Electric Power Assisted Steering Secondary (EPAS3S) eFuse; raw 12 = signal not available (SNA)";
CM_ SG_ 753 VCFRONT_EPAS3STemp "Front body controller: EPAS3 s temp";
CM_ SG_ 753 VCFRONT_EPAS3SEFuseVNFState "State of the EPAS3S eFuse";
CM_ SG_ 753 VCFRONT_EPAS3SEFuseOutput "Output state of the EPAS3S efuse";
CM_ SG_ 753 VCFRONT_EPAS3SEFuseOutputDesired "Output of the EPAS3S efuse";
CM_ SG_ 753 VCFRONT_EPAS3SVoltage "Voltage of the secondary power steering circuit";
CM_ SG_ 753 VCFRONT_EPAS3SEFuseBypass "Bypass output state of the EPAS3S efuse";
CM_ SG_ 753 VCFRONT_EPAS3SEFuseBypassDesired "Bypass output of the EPAS3S efuse";
CM_ SG_ 753 VCFRONT_EPAS3SCurrent "Electrical current of the secondary power steering circuit";
CM_ SG_ 753 VCFRONT_EPAS3SEFuseVNFSelfTestSt "Front body controller: EPAS3 SE fuse VNF self test status";
CM_ SG_ 753 VCFRONT_ESPMotorState "Front body controller: ESP motor state; raw 3 = signal not available (SNA)";
CM_ SG_ 753 VCFRONT_ESPMotorFault "Front body controller: ESP motor fault";
CM_ SG_ 753 VCFRONT_ESPMotorSelfTestResult "Reports the result of the most recent self-test of the Electronic Stability Program Motor (ESP Motor) eFuse; raw 12 = signal not available (SNA)";
CM_ SG_ 753 VCFRONT_ESPMotorTemp "Front body controller: ESP motor temp";
CM_ SG_ 753 VCFRONT_ESPMotorEFuseVNFState "State of the ESPMotor eFuse";
CM_ SG_ 753 VCFRONT_ESPMotorEFuseOutput "Output state of the ESPMotor efuse";
CM_ SG_ 753 VCFRONT_ESPMotorEFuseOutputDesir "Output of the ESPMotor efuse";
CM_ SG_ 753 VCFRONT_ESPMotorVoltage "Front body controller: ESP motor voltage";
CM_ SG_ 753 VCFRONT_ESPMotorEFuseBypass "Bypass output state of the ESPMotor efuse";
CM_ SG_ 753 VCFRONT_ESPMotorEFuseBypassDesir "Bypass output of the ESPMotor efuse";
CM_ SG_ 753 VCFRONT_ESPMotorCurrent "Front body controller: ESP motor current";
CM_ SG_ 753 VCFRONT_ESPMotorEFuseVNFSelfTest "Front body controller: ESP motor e fuse VNF self test status";
CM_ SG_ 753 VCFRONT_ESPValveState "State of the stability controller motor circuit; raw 3 = signal not available (SNA)";
CM_ SG_ 753 VCFRONT_ESPValveFault "Front body controller: ESP valve fault";
CM_ SG_ 753 VCFRONT_ESPValveTemp "Front body controller: ESP valve temp";
CM_ SG_ 753 VCFRONT_ESPValveVoltage "Front body controller: ESP valve voltage";
CM_ SG_ 753 VCFRONT_ESPValveCurrent "Electrical current of the stability controller motor circuit";
CM_ SG_ 753 VCFRONT_autopilot2State "Front body controller: autopilot2 state; raw 3 = signal not available (SNA)";
CM_ SG_ 753 VCFRONT_autopilot2Fault "Front body controller: autopilot2 fault";
CM_ SG_ 753 VCFRONT_autopilot2Temp "Front body controller: autopilot2 temp";
CM_ SG_ 753 VCFRONT_autopilot2Voltage "Front body controller: autopilot2 voltage";
CM_ SG_ 753 VCFRONT_autopilot2Current "Front body controller: autopilot2 current";
CM_ SG_ 753 VCFRONT_sleepBypassState "State of the sleep bypass circuit";
CM_ SG_ 753 VCFRONT_sleepBypassFault "Front body controller: sleep bypass fault";
CM_ SG_ 753 VCFRONT_sleepBypassVoltage "Front body controller: sleep bypass voltage";
CM_ SG_ 753 VCFRONT_sleepBypassCurrent "Front body controller: sleep bypass current";
CM_ SG_ 753 VCFRONT_vbatFusedHighState "Front body controller: vbat fused high state";
CM_ SG_ 753 VCFRONT_vbatFusedHighFault "Front body controller: vbat fused high fault";
CM_ SG_ 753 VCFRONT_vbatFusedSelfTestResult "Front body controller: vbat fused self test result; raw 12 = signal not available (SNA)";
CM_ SG_ 753 VCFRONT_vbatFusedHighTemp "Front body controller: vbat fused high temp";
CM_ SG_ 753 VCFRONT_vbatFusedHighVoltage "Front body controller: vbat fused high voltage";
CM_ SG_ 753 VCFRONT_vbatFusedHighCurrent "Front body controller: vbat fused high current";
CM_ SG_ 753 VCFRONT_chargedIBSAmpHours "Front body controller: charged IBS amp hours";
CM_ SG_ 753 VCFRONT_dischargedIBSAmpHours "Front body controller: discharged IBS amp hours";
CM_ SG_ 753 VCFRONT_IBSUnfilteredTemperature "Front body controller: IBS unfiltered temperature; raw 32768 = signal not available (SNA)";
CM_ BO_ 769 "Front body controller message: info";
CM_ SG_ 769 VCFRONT_infoIndex "Front body controller: info index";
CM_ SG_ 769 VCFRONT_infoBuildType "Front body controller: info build type";
CM_ SG_ 769 VCFRONT_infoBuildConfigId "Front body controller: info build config id";
CM_ SG_ 769 VCFRONT_infoHardwareId "Front body controller: info hardware id";
CM_ SG_ 769 VCFRONT_infoComponentId "Front body controller: info component id";
CM_ SG_ 769 VCFRONT_infoPcbaId "Front body controller: info pcba id";
CM_ SG_ 769 VCFRONT_infoAssemblyId "Front body controller: info assembly id; raw 255 = signal not available (SNA)";
CM_ SG_ 769 VCFRONT_infoUsageId "Front body controller: info usage id";
CM_ SG_ 769 VCFRONT_infoSubUsageId "Front body controller: info sub usage id";
CM_ SG_ 769 VCFRONT_infoAppCrc "Front body controller: info app crc";
CM_ SG_ 769 VC_infoHCMLAppCRC "Front body controller: info HCML app CRC";
CM_ SG_ 769 VCFRONT_infoAppGitHash "Front body controller: info app git hash";
CM_ SG_ 769 VCFRONT_infoBootGitHash "Front body controller: info boot git hash";
CM_ SG_ 769 VCFRONT_infoPlatformType "Front body controller: info platform type";
CM_ SG_ 769 VCFRONT_infoBootUdsProtoVersion "Front body controller: info boot uds proto version";
CM_ SG_ 769 VCFRONT_infoBootCrc "Front body controller: info boot crc";
CM_ SG_ 769 VC_infoHCMRAppCRC "Front body controller: info HCMR app CRC";
CM_ BO_ 1801 "Front body controller message: logging0point1 hz";
CM_ SG_ 1801 VCFRONT_logging0point1HzIndex "Front body controller: logging0point1 hz index";
CM_ SG_ 1801 VC_hcmlFactoryOfOrigin "Tier 1 supplier (Hella) factory of origin of the left headlamp";
CM_ SG_ 1801 VC_hcmlHellaPartNumberStatus "Front body controller: hcml hella part number status";
CM_ SG_ 1801 VC_hcmlHellaPartNumber "Value of the Hella Part Number written into EEPROM in the left headlamp";
CM_ SG_ 1801 VC_hcmlCurrentBinMappingType "Front body controller: hcml current bin mapping type";
CM_ SG_ 1801 VC_hcmlCurrentBin0Value "Front body controller: hcml current bin0 value; raw 0 = signal not available (SNA)";
CM_ SG_ 1801 VC_hcmlCurrentBin1Value "Front body controller: hcml current bin1 value; raw 0 = signal not available (SNA)";
CM_ SG_ 1801 VC_hcmlCurrentBin2Value "Front body controller: hcml current bin2 value; raw 0 = signal not available (SNA)";
CM_ SG_ 1801 VC_hcmlCurrentBin3Value "Front body controller: hcml current bin3 value; raw 0 = signal not available (SNA)";
CM_ SG_ 1801 VC_hcmlCurrentBin4Value "Front body controller: hcml current bin4 value; raw 0 = signal not available (SNA)";
CM_ SG_ 1801 VC_hcmlCurrentBin5Value "Front body controller: hcml current bin5 value; raw 0 = signal not available (SNA)";
CM_ SG_ 1801 VC_hcmlRegionAndSide "Left headlamp EEPROM region and side; raw 0 = signal not available (SNA)";
CM_ SG_ 1801 VC_hcmrFactoryOfOrigin "Tier 1 supplier (Hella) factory of origin of the right headlamp";
CM_ SG_ 1801 VC_hcmrHellaPartNumberStatus "Front body controller: hcmr hella part number status";
CM_ SG_ 1801 VC_hcmrHellaPartNumber "Value of the Hella Part Number written into EEPROM in the right headlamp";
CM_ SG_ 1801 VC_hcmrCurrentBinMappingType "Front body controller: hcmr current bin mapping type";
CM_ SG_ 1801 VC_hcmrCurrentBin0Value "Front body controller: hcmr current bin0 value; raw 0 = signal not available (SNA)";
CM_ SG_ 1801 VC_hcmrCurrentBin1Value "Front body controller: hcmr current bin1 value; raw 0 = signal not available (SNA)";
CM_ SG_ 1801 VC_hcmrCurrentBin2Value "Front body controller: hcmr current bin2 value; raw 0 = signal not available (SNA)";
CM_ SG_ 1801 VC_hcmrCurrentBin3Value "Front body controller: hcmr current bin3 value; raw 0 = signal not available (SNA)";
CM_ SG_ 1801 VC_hcmrCurrentBin4Value "Front body controller: hcmr current bin4 value; raw 0 = signal not available (SNA)";
CM_ SG_ 1801 VC_hcmrCurrentBin5Value "Front body controller: hcmr current bin5 value; raw 0 = signal not available (SNA)";
CM_ SG_ 1801 VC_hcmrRegionAndSide "Right headlamp EEPROM region and side; raw 0 = signal not available (SNA)";
CM_ BO_ 705 "Front body controller message: logging10 hz";
CM_ SG_ 705 VCFRONT_logging10HzIndex "Front body controller: logging10 hz index";
CM_ SG_ 705 VCFRONT_pumpBatteryOutVoltage "Front body controller: pump battery out voltage";
CM_ SG_ 705 VCFRONT_pumpPowertrainOutVoltage "Front body controller: pump powertrain out voltage";
CM_ SG_ 705 VCFRONT_pumpBatteryInitd "Front body controller: pump battery initd";
CM_ SG_ 705 VCFRONT_pumpPowertrainInitd "Front body controller: pump powertrain initd";
CM_ SG_ 705 VCFRONT_pumpBatteryEnabled "Front body controller: pump battery enabled";
CM_ SG_ 705 VCFRONT_pumpPowertrainEnabled "Front body controller: pump powertrain enabled";
CM_ SG_ 705 VCFRONT_pumpBatteryPowerOn "Front body controller: pump battery power on";
CM_ SG_ 705 VCFRONT_pumpPowertrainPowerOn "Front body controller: pump powertrain power on";
CM_ SG_ 705 VCFRONT_pumpsWake "Front body controller: pumps wake";
CM_ SG_ 705 VCFRONT_pumpBatSpiError "Front body controller: pump bat spi error";
CM_ SG_ 705 VCFRONT_pumpPtSpiError "Front body controller: pump pt spi error";
CM_ SG_ 705 VCFRONT_coolantFlowChillerActual "Front body controller: coolant flow chiller actual";
CM_ SG_ 705 VCFRONT_radiatorFanOutVoltage "Front body controller: radiator fan out voltage";
CM_ SG_ 705 VCFRONT_radiatorFanInitd "Front body controller: radiator fan initd";
CM_ SG_ 705 VCFRONT_radiatorFanEnabled "Indication that the cooling fan is enabled";
CM_ SG_ 705 VCFRONT_radiatorFanPowerOn "Indication that the cooling fan is powered on";
CM_ SG_ 705 VCFRONT_radiatorFanPhaseCurrent "Front body controller: radiator fan phase current";
CM_ SG_ 705 VCFRONT_radiatorFanPhaseIMax "Front body controller: radiator fan phase i max";
CM_ SG_ 705 VCFRONT_thmlFanSpiError "Front body controller: thml fan spi error";
CM_ SG_ 705 VCFRONT_chargeTrapNominalCOP1Bat "Front body controller: charge trap nominal COP1 batt heat";
CM_ SG_ 705 VCFRONT_chargeTrapNominalCOP1Chi "Front body controller: charge trap nominal COP1 chiller batt heat";
CM_ BO_ 897 "Front body controller message: logging1 hz";
CM_ SG_ 897 VCFRONT_logging1HzIndex "Front body controller: logging1 hz index";
CM_ SG_ 897 VCFRONT_modeTransitionID "Front body controller: mode transition ID";
CM_ SG_ 897 VCFRONT_modeDesired "Front body controller: mode desired";
CM_ SG_ 897 VCFRONT_targetPTActiveCool "Front body controller: target PT active cool";
CM_ SG_ 897 VCFRONT_targetPtOptionalActiveCo "Front body controller: target pt optional active cool";
CM_ SG_ 897 VCFRONT_targetPTPassive "Front body controller: target PT passive";
CM_ SG_ 897 VCFRONT_targetBatActiveCool "Front body controller: target bat active cool";
CM_ SG_ 897 VCFRONT_targetBatOptionalActiveC "Front body controller: target bat optional active cool";
CM_ SG_ 897 VCFRONT_targetBatPassive "Front body controller: target bat passive";
CM_ SG_ 897 VCFRONT_targetBatActiveHeat "Active heating temperature target for the battery coolant loop";
CM_ SG_ 897 VCFRONT_condenserPressureLimit "Front body controller: condenser pressure limit";
CM_ SG_ 897 VCFRONT_fanDemandCondenser "Front body controller: fan demand condenser";
CM_ SG_ 897 VCFRONT_fanDemandRadiator "Front body controller: fan demand radiator";
CM_ SG_ 897 VCFRONT_tempRefrigSuction "Refrigerant system suction temperature; raw 255 = signal not available (SNA)";
CM_ SG_ 897 VCFRONT_pumpBatteryFETTemp "Front body controller: pump battery FET temp; raw 255 = signal not available (SNA)";
CM_ SG_ 897 VCFRONT_pumpPowertrainFETTemp "Front body controller: pump powertrain FET temp; raw 255 = signal not available (SNA)";
CM_ SG_ 897 VCFRONT_radiatorFanFETTemp "Front body controller: radiator fan FET temp; raw 255 = signal not available (SNA)";
CM_ SG_ 897 VCFRONT_radiatorFanRunReason "Current radiator fan run readon";
CM_ SG_ 897 VCFRONT_coolantValveModeWrong "Front body controller: coolant valve mode wrong";
CM_ SG_ 897 VCFRONT_coolantTempBasedMode "Front body controller: coolant temp based mode";
CM_ SG_ 897 VCFRONT_coolantValveRecalReason "coolant Valve Reason for Recalibration";
CM_ SG_ 897 VCFRONT_coolantValveCountRange "Range of tick counts of the coolant valve actuator; raw 1023 = signal not available (SNA)";
CM_ SG_ 897 VCFRONT_coolantValveAngleDrift "Estimated angular drift of the coolant valve";
CM_ SG_ 897 VCFRONT_coolantValveRecalCount "coolant Valve Calibration Count";
CM_ SG_ 897 VCFRONT_coolantValveWindupEst "Front body controller: coolant valve windup est";
CM_ SG_ 897 VCFRONT_coolantValveRadBypass "Percent of coolant bypassing the powertrain radiator; raw 127 = signal not available (SNA)";
CM_ SG_ 897 VCFRONT_usingModeledPs "Front body controller: using modeled ps";
CM_ SG_ 897 VCFRONT_usingModeledPd "Front body controller: using modeled pd";
CM_ SG_ 897 VCFRONT_usingModeledPl "Front body controller: using modeled pl";
CM_ SG_ 897 VCFRONT_usingModeledTs "Front body controller: using modeled ts";
CM_ SG_ 897 VCFRONT_usingModeledTd "Front body controller: using modeled td";
CM_ SG_ 897 VCFRONT_usingModeledTl "Front body controller: using modeled tl";
CM_ SG_ 897 VCFRONT_hpChargeCableType "Front body controller: hp charge cable type";
CM_ SG_ 897 VCFRONT_subcoolActual "Front body controller: subcool actual";
CM_ SG_ 897 VCFRONT_hpSubcoolTarget "Front body controller: hp subcool target";
CM_ SG_ 897 VCFRONT_CMPDischargeSuperheat "Front body controller: CMP discharge superheat";
CM_ SG_ 897 VCFRONT_hpCOP "Front body controller: hp COP";
CM_ SG_ 897 VCFRONT_lowSideWattsLift "Front body controller: low side watts lift";
CM_ SG_ 897 VCFRONT_tempSuperheatActual "Front body controller: temp superheat actual; raw 1023 = signal not available (SNA)";
CM_ SG_ 897 VCFRONT_tempSuperheatTarget "Front body controller: temp superheat target";
CM_ SG_ 897 VCFRONT_refrigerantHasBeenFilled "Front body controller: refrigerant has been filled";
CM_ SG_ 897 VCFRONT_refCommissionStatus "Front body controller: ref commission status";
CM_ SG_ 897 VCFRONT_LCCPurgeActive "Reports if Liquid Cooled Condenser (LCC) refrigerant purge is active on the heat pump.";
CM_ SG_ 897 VCFRONT_exteriorQuietModeEnabled "Front body controller: exterior quiet mode enabled";
CM_ SG_ 897 VCFRONT_exteriorQuietModeAllowed "Front body controller: exterior quiet mode allowed";
CM_ SG_ 897 VCFRONT_CCQdotFdFrwrdTarget "Front body controller: CC qdot fd frwrd target";
CM_ SG_ 897 VCFRONT_CCQdotFdbk "Front body controller: CC qdot fdbk";
CM_ SG_ 897 VCFRONT_CCQdotActual "Front body controller: CC qdot actual";
CM_ SG_ 897 VCFRONT_evapFdFrwrdTarget "Front body controller: evap fd frwrd target";
CM_ SG_ 897 VCFRONT_evapFdbk "Front body controller: evap fdbk";
CM_ SG_ 897 VCFRONT_DIQdotA "Front body controller: DI qdot a";
CM_ SG_ 897 VCFRONT_evapFdFrwrdTargetMinimum "Front body controller: evap fd frwrd target minimum";
CM_ SG_ 897 VCFRONT_passiveCoolingState "Front body controller: passive cooling state";
CM_ SG_ 897 VCFRONT_totalLoadCoolingDominant "Front body controller: total load cooling dominant";
CM_ SG_ 897 VCFRONT_feedfwdLoadCoolingDomina "Front body controller: feedfwd load cooling dominant";
CM_ SG_ 897 VCFRONT_modelLoadCoolingDominant "Front body controller: model load cooling dominant";
CM_ SG_ 897 VCFRONT_hpPotentialLowRefrig "Front body controller: hp potential low refrig";
CM_ SG_ 897 VCFRONT_hpRefrigerantPurgeState "Front body controller: hp refrigerant purge state";
CM_ SG_ 897 VCFRONT_estPressureLiq "Front body controller: est pressure liq";
CM_ SG_ 897 VCFRONT_estPressureSuct "Front body controller: est pressure suct";
CM_ SG_ 897 VCFRONT_estPressureDisch "Front body controller: est pressure disch";
CM_ SG_ 897 VCFRONT_estTempLiq "Front body controller: est temp liq";
CM_ SG_ 897 VCFRONT_estTempSuct "Front body controller: est temp suct";
CM_ SG_ 897 VCFRONT_estTempDisch "Front body controller: est temp disch";
CM_ SG_ 897 VCFRONT_estCompressorRpm "Front body controller: est compressor rpm";
CM_ SG_ 897 VCFRONT_estQLift "Front body controller: est q lift";
CM_ SG_ 897 VCFRONT_cycleModelConverged "Front body controller: cycle model converged";
CM_ SG_ 897 VCFRONT_compStandbyCoastDownMode "Front body controller: comp standby coast down mode";
CM_ SG_ 897 VCFRONT_compStandbyShowroomMode "Front body controller: comp standby showroom mode";
CM_ SG_ 897 VCFRONT_chillerExvCalibOffset "Last calibration offset calculated for the Chiller EXV";
CM_ SG_ 897 VCFRONT_evapExvCalibOffset "Last calibration offset calculated for the Evaporator EXV";
CM_ SG_ 897 VCFRONT_recircExvCalibOffset "Last calibration offset calculated for the Recirc EXV";
CM_ SG_ 897 VCFRONT_lccExvCalibOffset "Last calibration offset calculated for the Liquid Cooled Condenser EXV";
CM_ SG_ 897 VCFRONT_ccLeftExvCalibOffset "Last calibration offset calculated for the Left Cabin Condenser EXV";
CM_ SG_ 897 VCFRONT_ccRightExvCalibOffset "Last calibration offset calculated for the Right Cabin Condenser EXV";
CM_ SG_ 897 VCFRONT_chillerEXVControlState "Control State of the chiller electronic expansion valve";
CM_ SG_ 897 VCFRONT_evapEXVControlState "Control State of the evaporator electronic expansion valve";
CM_ SG_ 897 VCFRONT_recircEXVControlState "Control State of the recirc electronic expansion valve";
CM_ SG_ 897 VCFRONT_lccEXVControlState "Control State of the liquid cooled condenser electronic expansion valve";
CM_ SG_ 897 VCFRONT_cclEXVControlState "Control State of the chiller electronic expansion valve";
CM_ SG_ 897 VCFRONT_ccrEXVControlState "Control State of the right cabin condenser electronic expansion valve";
CM_ SG_ 897 VCFRONT_chillerExvCalibFailed "State of the last calibration for the Chiller EXV";
CM_ SG_ 897 VCFRONT_evapExvCalibFailed "State of the last calibration for the Evaporator EXV";
CM_ SG_ 897 VCFRONT_recircExvCalibFailed "State of the last calibration for the Recirc EXV";
CM_ SG_ 897 VCFRONT_lccExvCalibFailed "State of the last calibration for the Liquid Cooled Condenser EXV";
CM_ SG_ 897 VCFRONT_ccLeftExvCalibFailed "State of the last calibration for the Left Cabin Condenser EXV";
CM_ SG_ 897 VCFRONT_ccRightExvCalibFailed "State of the last calibration for the Right Cabin Condenser EXV";
CM_ SG_ 897 VCFRONT_ambientTempSniffActive "Front body controller: ambient temp sniff active";
CM_ SG_ 897 VCFRONT_ambientTempPassiveSniffi "Front body controller: ambient temp passive sniffing";
CM_ SG_ 897 VCFRONT_ambientTempRadSampling "Front body controller: ambient temp rad sampling";
CM_ SG_ 897 VCFRONT_ambientTempSpeedSampling "Front body controller: ambient temp speed sampling";
CM_ SG_ 897 VCFRONT_feedFwdMDotEvaporator "Front body controller: feed fwd m dot evaporator";
CM_ SG_ 897 VCFRONT_hpCabinHeatBatteryHeatAm "Front body controller: hp cabin heat battery heat amb src";
CM_ SG_ 897 VCFRONT_hpCabinHeatBatteryHeatCO "Front body controller: hp cabin heat battery heat COP1";
CM_ SG_ 897 VCFRONT_feedFwdMDotCabinCondense "Feed forward MDOT for the cabin condenser controller.";
CM_ SG_ 897 VCFRONT_feedBackEvapTempControll "Evap temperature controller feedback.";
CM_ SG_ 897 VCFRONT_feedBackDuctTempControll "Feedback for the duct temp controller.";
CM_ SG_ 897 VCFRONT_isSolenoidAllowed "Front body controller: is solenoid allowed";
CM_ SG_ 897 VCFRONT_maxChillerCoolingPower "Front body controller: max chiller cooling power";
CM_ SG_ 897 VCFRONT_fanControlRadCanCool "Front body controller: fan control rad can cool";
CM_ SG_ 897 VCFRONT_fanControlFeedfwdActive "Front body controller: fan control feedfwd active";
CM_ SG_ 897 VCFRONT_fanControlRadiatorUa "Front body controller: fan control radiator ua";
CM_ SG_ 897 VCFRONT_fanControlRadiatorInletT "Front body controller: fan control radiator inlet temp";
CM_ SG_ 897 VCFRONT_hpASBatteryHeatingAllowe "Front body controller: hp AS battery heating allowed";
CM_ SG_ 897 VCFRONT_hpCOP1BatteryHeatingAllo "Front body controller: hp COP1 battery heating allowed";
CM_ SG_ 897 VCFRONT_hpCabinHeatScavengeOnly "Front body controller: hp cabin heat scavenge only";
CM_ SG_ 897 VCFRONT_hpCabinHeatAmbientSource "Front body controller: hp cabin heat ambient source";
CM_ SG_ 897 VCFRONT_hpCabinHeatReheatScaveng "Front body controller: hp cabin heat reheat scavenge";
CM_ SG_ 897 VCFRONT_hpCabinHeatReheatAmbient "Front body controller: hp cabin heat reheat ambient source";
CM_ SG_ 897 VCFRONT_hpCabinHeatBlend "Front body controller: hp cabin heat blend";
CM_ SG_ 897 VCFRONT_hpCabinHeatCOP1 "Front body controller: hp cabin heat COP1";
CM_ SG_ 897 VCFRONT_hpCabinHeatBatteryHeatRe "Front body controller: hp cabin heat battery heat reheat amb src";
CM_ SG_ 897 VCFRONT_hpCabinHeatBatteryCoolRe "Front body controller: hp cabin heat battery cool reheat";
CM_ SG_ 897 VCFRONT_hpCabinCoolEvaporator "Front body controller: hp cabin cool evaporator";
CM_ SG_ 897 VCFRONT_hpCabinCoolEvaporatorReh "Front body controller: hp cabin cool evaporator reheat";
CM_ SG_ 897 VCFRONT_hpBatteryHeatAmbientSour "Front body controller: hp battery heat ambient source";
CM_ SG_ 897 VCFRONT_hpBatteryHeatCOP1 "Front body controller: hp battery heat COP1";
CM_ SG_ 897 VCFRONT_hpBatteryCool "Front body controller: hp battery cool";
CM_ SG_ 897 VCFRONT_hpBatteryCoolCabinConden "Front body controller: hp battery cool cabin condenser CD";
CM_ SG_ 897 VCFRONT_hpBatteryCoolCabinC_0001 "Front body controller: hp battery cool cabin condenser HD";
CM_ SG_ 897 VCFRONT_hpBatteryCoolCabinReheat "Front body controller: hp battery cool cabin reheat";
CM_ SG_ 897 VCFRONT_hpBatteryCoolEvaporator "Front body controller: hp battery cool evaporator";
CM_ SG_ 897 VCFRONT_suctionSuperheatEstTsSNA "Front body controller: suction superheat est ts SNA";
CM_ SG_ 897 VCFRONT_tempRefrigSuctionEst "Front body controller: temp refrig suction est";
CM_ SG_ 897 VCFRONT_hpBattOverTempHvacDisabl "Front body controller: hp batt over temp hvac disable";
CM_ SG_ 897 VCFRONT_hpDiagLouverCalib "Diagnostics requested a louver calibration.";
CM_ SG_ 897 VCFRONT_hpDiagHighSideNotNominal "Front body controller: hp diag high side not nominal";
CM_ SG_ 897 VCFRONT_hpForceModeRadClear "Front body controller: hp force mode rad clear";
CM_ SG_ 897 VCFRONT_estPressureDischargeSat "Front body controller: est pressure discharge sat";
CM_ SG_ 897 VCFRONT_tempRefrigLiquid "Refrigerant system liquid line temperature; raw 2047 = signal not available (SNA)";
CM_ SG_ 897 VCFRONT_totalBattHeatingPower "Total battery heating power requested";
CM_ SG_ 897 VCFRONT_hpPotentialFrozenRadiato "Front body controller: hp potential frozen radiator";
CM_ SG_ 897 VCFRONT_passiveSeriesRegOn "Front body controller: passive series reg on";
CM_ SG_ 897 VCFRONT_passiveDemandRadBypass "Front body controller: passive demand rad bypass";
CM_ SG_ 897 VCFRONT_targetLccActiveCoolCap "Front body controller: target lcc active cool cap";
CM_ SG_ 897 VCFRONT_targetLccActiveCoolEff "Front body controller: target lcc active cool eff";
CM_ SG_ 897 VCFRONT_coolantValveDailyAngleTr "Running 10-day average of daily angular travel";
CM_ SG_ 897 VCFRONT_dischargePressureLimit "Front body controller: discharge pressure limit";
CM_ SG_ 897 VCFRONT_radMovementBlockActive "Front body controller: rad movement block active";
CM_ SG_ 897 VCFRONT_radBypassMoveReason "Front body controller: rad bypass move reason";
CM_ SG_ 897 VCFRONT_hpBattHeatingPower "Front body controller: hp batt heating power";
CM_ SG_ 897 VCFRONT_hpColdStagnationLimit "Front body controller: hp cold stagnation limit";
CM_ SG_ 897 VCFRONT_hpHotStagnationLimit "Front body controller: hp hot stagnation limit";
CM_ SG_ 897 VCFRONT_hpCompFlowIndex "Front body controller: hp comp flow index";
CM_ SG_ 897 VCFRONT_hpCompFlowIndexFiltered "Front body controller: hp comp flow index filtered";
CM_ SG_ 897 VCFRONT_subcoolEstTlSNA "Front body controller: subcool est tl SNA";
CM_ SG_ 897 VCFRONT_subcoolEstPlSNA "Front body controller: subcool est pl SNA";
CM_ SG_ 897 VCFRONT_tempRefrigLiquidEst "Front body controller: temp refrig liquid est";
CM_ SG_ 897 VCFRONT_pressureRefrigLiquidEst "Front body controller: pressure refrig liquid est";
CM_ SG_ 897 VCFRONT_cmpIsentropicCheckPassed "Front body controller: cmp isentropic check passed";
CM_ SG_ 897 VCFRONT_louverPosReason "Front body controller: louver pos reason";
CM_ SG_ 897 VCFRONT_hpEnergyFlowIndex "Front body controller: hp energy flow index";
CM_ SG_ 897 VCFRONT_hpEnergyFlowIndexFiltere "Refrigerant system modeled energy flow index filtered";
CM_ SG_ 897 VCFRONT_ductLeftAtSS "Front body controller: duct left at SS";
CM_ SG_ 897 VCFRONT_ductRightAtSS "Front body controller: duct right at SS";
CM_ SG_ 897 VCFRONT_minCompressorRPMAllowed "Front body controller: min compressor RPM allowed";
CM_ SG_ 897 VCFRONT_ccRefrigerantMassFlow "Front body controller: cc refrigerant mass flow";
CM_ SG_ 897 VCFRONT_highSideDpResidual "Front body controller: high side dp residual";
CM_ SG_ 897 VCFRONT_abnormalHighSuctionSuper "Front body controller: abnormal high suction superheat";
CM_ SG_ 897 VCFRONT_coolantValveAngleTravel "Total angular travel since last (re)calibration";
CM_ SG_ 897 VCFRONT_chargeShuttleType "Front body controller: charge shuttle type";
CM_ SG_ 897 VCFRONT_hpRefrigTempSensorCheckC "Front body controller: hp refrig temp sensor check can fire";
CM_ SG_ 897 VCFRONT_hpRefrigPressureSensorCh "Front body controller: hp refrig pressure sensor check can fire";
CM_ SG_ 897 VCFRONT_tempSuperheatActFiltered "Front body controller: temp superheat act filtered";
CM_ SG_ 897 VCFRONT_tempRefrigDischarge "Refrigerant system discharge temperature; raw 2047 = signal not available (SNA)";
CM_ SG_ 897 VCFRONT_pumpBatteryRPMTarget "Front body controller: pump battery RPM target; raw 255 = signal not available (SNA)";
CM_ SG_ 897 VCFRONT_pumpPowertrainRPMTarget "Front body controller: pump powertrain RPM target; raw 255 = signal not available (SNA)";
CM_ SG_ 897 VCFRONT_coolantFlowChillerTarget "Front body controller: coolant flow chiller target";
CM_ SG_ 897 VCFRONT_radiatorFanRPMTarget "Front body controller: radiator fan RPM target; raw 255 = signal not available (SNA)";
CM_ SG_ 897 VCFRONT_preventReEntryTillNexthp "Front body controller: prevent re entry till nexthp reset COP1";
CM_ SG_ 897 VCFRONT_chillerBattHeatingPowerA "Front body controller: chiller batt heating power available";
CM_ SG_ 897 VCFRONT_isExpectedQChillerVeryHi "Front body controller: is expected q chiller very high COP1";
CM_ SG_ 897 VCFRONT_superheatProtectionLimit "Front body controller: superheat protection limit";
CM_ SG_ 897 VCFRONT_chillerDemandWatts "Front body controller: chiller demand watts";
CM_ SG_ 897 VCFRONT_nominalTevapHWLimit "Front body controller: nominal tevap HW limit";
CM_ SG_ 897 VCFRONT_battCoolEvapEnableDelay "Front body controller: batt cool evap enable delay";
CM_ SG_ 897 VCFRONT_ambientTempState "Front body controller: ambient temp state";
CM_ SG_ 897 VCFRONT_ambientTempUnlatchReason "Front body controller: ambient temp unlatch reason";
CM_ SG_ 897 VCFRONT_compressorSuctionVaporQu "Front body controller: compressor suction vapor quality";
CM_ SG_ 897 VCFRONT_cabinHeatingCOP1MinActiv "Estimation of minimal active refrigerant charge during cabin heating COP1 mode";
CM_ BO_ 513 "Front body controller message: logging and vitals10 hz";
CM_ SG_ 513 VCFRONT_loggingAndVitals10HzInde "Front body controller: logging and vitals10 hz index";
CM_ SG_ 513 VCFRONT_pumpBatteryRPMActual "Front body controller: pump battery RPM actual; raw 255 = signal not available (SNA)";
CM_ SG_ 513 VCFRONT_pumpPowertrainRPMActual "Front body controller: pump powertrain RPM actual; raw 255 = signal not available (SNA)";
CM_ SG_ 513 VCFRONT_radiatorFanRPMActual "Front body controller: radiator fan RPM actual; raw 255 = signal not available (SNA)";
CM_ SG_ 513 VCFRONT_exvFlowTarget "Front body controller: exv flow target";
CM_ SG_ 513 VCFRONT_activeLouverOpenPosTarg "The target position for the active louver";
CM_ SG_ 513 VCFRONT_pressureRefrigLiquid "Refrigerant system Liquid line pressure; raw 511 = signal not available (SNA)";
CM_ SG_ 513 VCFRONT_compSleepRequest "Front body controller: comp sleep request";
CM_ SG_ 513 VCFRONT_fanDemand "Front body controller: fan demand";
CM_ SG_ 513 VCFRONT_compressorState "State of the refrigerant compressor.";
CM_ SG_ 513 VCFRONT_compDemandEvap "Front body controller: comp demand evap";
CM_ SG_ 513 VCFRONT_exvState "Front body controller: exv state";
CM_ SG_ 513 VCFRONT_solenoidEvapState "Front body controller: solenoid evap state";
CM_ SG_ 513 VCFRONT_compDemandChiller "Front body controller: comp demand chiller";
CM_ SG_ 513 VCFRONT_coolantValveMode "Coolant mode of the powertrain cooling circuit";
CM_ SG_ 513 VCFRONT_compFaultSeverity "Front body controller: comp fault severity";
CM_ SG_ 513 VCFRONT_solenoidEngaged "Front body controller: solenoid engaged";
CM_ SG_ 513 VCFRONT_hpHighSideHX "Front body controller: hp high side HX";
CM_ SG_ 513 VCFRONT_hpLowSideHX "Front body controller: hp low side HX";
CM_ SG_ 513 VCFRONT_hpDominantLoad "Dominant load type for the refrigerant system";
CM_ SG_ 513 VCFRONT_hpBlendType "Front body controller: hp blend type";
CM_ SG_ 513 VCFRONT_hpQuietModeEnabled "Front body controller: hp quiet mode enabled";
CM_ SG_ 513 VCFRONT_hpCabinLoadType "Front body controller: hp cabin load type";
CM_ SG_ 513 VCFRONT_hpBatteryLoadType "Front body controller: hp battery load type";
CM_ SG_ 513 VCFRONT_hpReqCoolantMode "Front body controller: hp req coolant mode";
CM_ SG_ 513 VCFRONT_hpReqTransScavenge "Front body controller: hp req trans scavenge";
CM_ SG_ 513 VCFRONT_compLiqPumpOutState "Front body controller: comp liq pump out state";
CM_ SG_ 513 VCFRONT_frunkStateDBG "The verbose debug state of the frunk latch";
CM_ SG_ 513 VCFRONT_frunkSwitchGroupState "Front body controller: frunk switch group state";
CM_ SG_ 513 VCFRONT_chillerExvFlow "Percent of full range that the Chiller EXV has opened";
CM_ SG_ 513 VCFRONT_evapExvFlow "Percent of full range that the evap EXV has opened";
CM_ SG_ 513 VCFRONT_recircExvFlow "Percent of full range that the recirc EXV has opened";
CM_ SG_ 513 VCFRONT_lccExvFlow "Percent of full range that the Liquid cooled condenser EXV has opened";
CM_ SG_ 513 VCFRONT_cclExvFlow "Percent of full range that the left cabin condenser EXV has opened";
CM_ SG_ 513 VCFRONT_ccrExvFlow "Percent of full range that the right cabin condenser EXV has opened";
CM_ SG_ 513 VCFRONT_chillerExvState "State of the chiller electronic expansion valve";
CM_ SG_ 513 VCFRONT_evapExvState "State of the evaporator electronic expansion valve";
CM_ SG_ 513 VCFRONT_recircExvState "State of the recirc electronic expansion valve";
CM_ SG_ 513 VCFRONT_chillerExvFlowTarget "Target percentage of full range that the chiler electronic expansion valve is commanded to open";
CM_ SG_ 513 VCFRONT_evapExvFlowTarget "Target percentage of full range that the evap electronic expansion valve is commanded to open";
CM_ SG_ 513 VCFRONT_recircExvFlowTarget "Target percentage of full range that the recirc electronic expansion valve is commanded to open";
CM_ SG_ 513 VCFRONT_lccExvFlowTarget "Target percentage of full range that the liquid cooled condenser electronic expansion valve is commanded to open";
CM_ SG_ 513 VCFRONT_cclExvFlowTarget "Target percentage of full range that the cabin condenser left electronic expansion valve is commanded to open";
CM_ SG_ 513 VCFRONT_ccrExvFlowTarget "Target percentage of full range that the cabin condenser right electronic expansion valve is commanded to open";
CM_ SG_ 513 VCFRONT_lccExvState "State of the liquid cooled condenser electronic expansion valve";
CM_ SG_ 513 VCFRONT_cclExvState "State of the cabin condenser left electronic expansion valve";
CM_ SG_ 513 VCFRONT_ccrExvState "State of the cabin conddenser left electronic expansion valve";
CM_ BO_ 737 "Front body controller message: status";
CM_ SG_ 737 VCFRONT_statusIndex "Front body controller: status index";
CM_ SG_ 737 VCFRONT_homelinkV2Response0 "Front body controller: homelink V2 response0";
CM_ SG_ 737 VCFRONT_homelinkV2Response1 "Front body controller: homelink V2 response1";
CM_ SG_ 737 VCFRONT_homelinkV2Response2 "Front body controller: homelink V2 response2";
CM_ SG_ 737 VCFRONT_homelinkV2Response3 "Front body controller: homelink V2 response3";
CM_ SG_ 737 VCFRONT_homelinkV2Response4 "Front body controller: homelink V2 response4";
CM_ SG_ 737 VCFRONT_homelinkCommStatus "Homelink communication status; raw 0 = signal not available (SNA)";
CM_ BO_ 929 "Front body controller message: vehicle status";
CM_ SG_ 929 VCFRONT_vehicleStatusMuxIndex "Front body controller: vehicle status mux index";
CM_ SG_ 929 VCFRONT_vehicleStatusCounter "Front body controller: vehicle status counter";
CM_ SG_ 929 VCFRONT_vehicleStatusChecksum "Front body controller: vehicle status checksum";
CM_ SG_ 929 VCFRONT_preconditionRequest "Front body controller: precondition request";
CM_ SG_ 929 VCFRONT_APGlassHeaterState "Front body controller: AP glass heater state; raw 0 = signal not available (SNA)";
CM_ SG_ 929 VCFRONT_thermalSystemType "Front body controller: thermal system type; raw 1 = signal not available (SNA)";
CM_ SG_ 929 VCFRONT_standbySupplySupported "Front body controller: standby supply supported";
CM_ SG_ 929 VCFRONT_driverPresent "Front body controller: driver present";
CM_ SG_ 929 VCFRONT_passengerPresent "Front body controller: passenger present";
CM_ SG_ 929 VCFRONT_accPlusAvailable "Front body controller: acc plus available";
CM_ SG_ 929 VCFRONT_diPowerOnState "Front body controller: di power on state";
CM_ SG_ 929 VCFRONT_12vStatusForDrive "Front body controller: 12v status for drive";
CM_ SG_ 929 VCFRONT_dcr12VMilliOhms "Front body controller: dcr12 v milli ohms";
CM_ SG_ 929 VC_userPresenceState "User presence state";
CM_ SG_ 929 VCFRONT_factoryLimitsOverrideOk "Front body controller: factory limits override ok";
CM_ SG_ 929 VCFRONT_ota12VSupportRequest "Front body controller: ota12 v support request";
CM_ SG_ 929 VCFRONT_driverBuckleStatus "Front body controller: driver buckle status";
CM_ SG_ 929 VCFRONT_driverDoorStatus "Front body controller: driver door status";
CM_ SG_ 929 VCFRONT_driverUnbuckled "Front body controller: driver unbuckled; raw 2 = signal not available (SNA)";
CM_ SG_ 929 VCFRONT_passengerUnbuckled "Front body controller: passenger unbuckled; raw 2 = signal not available (SNA)";
CM_ SG_ 929 VCFRONT_2RowLeftUnbuckled "Front body controller: 2 row left unbuckled; raw 2 = signal not available (SNA)";
CM_ SG_ 929 VCFRONT_2RowCenterUnbuckled "Front body controller: 2 row center unbuckled; raw 2 = signal not available (SNA)";
CM_ SG_ 929 VCFRONT_2RowRightUnbuckled "Front body controller: 2 row right unbuckled; raw 2 = signal not available (SNA)";
CM_ SG_ 929 VCFRONT_pcsEFuseVoltage "Front body controller: pcs e fuse voltage; raw 1023 = signal not available (SNA)";
CM_ SG_ 929 VCFRONT_bmsHvChargeEnable "Front body controller: bms hv charge enable";
CM_ SG_ 929 VCFRONT_3RowLeftUnbuckled "Indication that the third row left passenger has unbuckled their seat belt; raw 2 = signal not available (SNA)";
CM_ SG_ 929 VCFRONT_3RowRightUnbuckled "Indication that the third row right passenger has unbuckled their seat belt; raw 2 = signal not available (SNA)";
CM_ SG_ 929 VCFRONT_maxBattHeatRejection "Radiator max heat rejection estimated at zero vehicle speed.";
CM_ SG_ 929 VCFRONT_hvacReqBattCoolOutTemp "Battery outlet coolant temp target to allow HVAC min comfort";
CM_ SG_ 929 VCFRONT_PCSCurrent "Front body controller: PCS current";
CM_ SG_ 929 VCFRONT_refSystemNominal "Front body controller: ref system nominal";
CM_ SG_ 929 VCFRONT_driverEnteredCabinEstima "Front body controller: driver entered cabin estimate DBG";
CM_ SG_ 929 VCFRONT_anySWEFuseActive "Front body controller: any SWE fuse active";
CM_ SG_ 929 VCFRONT_hpBattHeatingPowerTrgt "Reports the heat pump battery heating power target.";
CM_ BO_ 258 "Left body controller message: door status";
CM_ SG_ 258 VCLEFT_doorClosureStatusFront "Status of the door from a closures perspective; raw 0 = signal not available (SNA)";
CM_ SG_ 258 VCLEFT_doorClosureStatusRear "Status of the door from a closures perspective; raw 0 = signal not available (SNA)";
CM_ SG_ 258 VCLEFT_frontLatchSwitch "State of front left door latch switch representing door open/closed. 0 is open and 1 is closed";
CM_ SG_ 258 VCLEFT_rearLatchSwitch "State of rear left door latch switch representing door open/closed. 0 is open and 1 is closed";
CM_ SG_ 258 VCLEFT_frontHandlePulled "Left body controller: front handle pulled";
CM_ SG_ 258 VCLEFT_rearHandlePulled "Left body controller: rear handle pulled";
CM_ SG_ 258 VCLEFT_frontRelActuatorSwitch "State of front left door latch switch representing latch arm/unarmed. Disarms while door handle is pulled.";
CM_ SG_ 258 VCLEFT_rearRelActuatorSwitch "State of rear left door latch switch representing latch arm/unarmed. Disarms while door handle is pulled";
CM_ SG_ 258 VCLEFT_frontLatchStatus "Status of left front door latch; raw 0 = signal not available (SNA)";
CM_ SG_ 258 VCLEFT_rearLatchStatus "Status of rear left door latch; raw 0 = signal not available (SNA)";
CM_ SG_ 258 VCLEFT_lastDoorReqSourceFront "last source of front door open request";
CM_ SG_ 258 VCLEFT_lastDoorReqSourceRear "last source of rear door open request";
CM_ SG_ 258 VCLEFT_frontIntSwitchPressed "Left body controller: front int switch pressed";
CM_ SG_ 258 VCLEFT_rearIntSwitchPressed "Left body controller: rear int switch pressed";
CM_ SG_ 258 VCLEFT_mirrorTiltXPosition "Value representing left side view mirror tilt horizontal position";
CM_ SG_ 258 VCLEFT_mirrorTiltYPosition "Value representing left side view mirror tilt vertical position";
CM_ SG_ 258 VCLEFT_mirrorState "State of the left side view mirror.";
CM_ SG_ 258 VCLEFT_mirrorFoldState "Fold state for the left side view mirror";
CM_ SG_ 258 VCLEFT_mirrorRecallState "State of Mirror Recall.";
CM_ SG_ 258 VCLEFT_mirrorHeatState "Left body controller: mirror heat state; raw 0 = signal not available (SNA)";
CM_ SG_ 258 VCLEFT_rearHandlePulledPersist "Left body controller: rear handle pulled persist";
CM_ SG_ 258 VCLEFT_frontHandlePulledPersist "Left body controller: front handle pulled persist";
CM_ SG_ 258 VCLEFT_mirrorDipped "Reports if the side view mirrors in are in the dipped position.";
CM_ BO_ 626 "Left body controller message: epbm debug";
CM_ SG_ 626 VCLEFT_epbmDebugIndex "Left body controller: epbm debug index";
CM_ SG_ 626 VCLEFT_epbmCaliperState "Left body controller: epbm caliper state";
CM_ SG_ 626 VCLEFT_epbmMotorEnabled "Left body controller: epbm motor enabled";
CM_ SG_ 626 VCLEFT_epbMotorCurrent "Left body controller: epb motor current";
CM_ SG_ 626 VCLEFT_epbmApplyVoltage "Left body controller: epbm apply voltage";
CM_ SG_ 626 VCLEFT_epbmReleaseVoltage "Left body controller: epbm release voltage";
CM_ SG_ 626 VCLEFT_summonFaultReason "Electronic Parking Brake Monitors error code associated with previous summon failure.";
CM_ SG_ 626 VCLEFT_epbSummonState "Electronic Parking Brake Monitors reading of Electronic Parking Brake's summon state.";
CM_ SG_ 626 VCLEFT_epbmSummonState "Electronic Parking Brake Monitors summon state.";
CM_ SG_ 626 VCLEFT_epbUnitStatus "Electronic Parking Brake Monitors reading of Electronic Parking Brake's state.";
CM_ SG_ 626 VCLEFT_epbmFaultStatus "Electronic Parking Brake Monitors fault state.";
CM_ SG_ 626 VCLEFT_epbFaultStatus "Electronic Parking Brake Monitors reading of Electronic Parking Brake's fault state.";
CM_ SG_ 626 VCLEFT_epbmSystemStatus "Electronic Parking Brake Monitors reading of Electronic Parking Brake's state.";
CM_ BO_ 1140 "Left body controller message: epbm status";
CM_ SG_ 1140 VCLEFT_cdpRequestState "If the Electronic Parking Brake makes a Controlled Deceleration for Parking Brake request, when cdpOkayToRequest is EPB_CDP_REQUEST_INVALID, cdpRequestState shall transition to EPB_CDP_REQUEST_INVALID, untill the Electronic Parking Brake Monitor enters unitStatus PARKED. Stability Control listens to this signal to qualify Controlled Deceleration for Parking Brake requests from the Electronic Parking Brake.";
CM_ SG_ 1140 VCLEFT_epbmSystemStatusQF "Left body controller: epbm system status QF";
CM_ SG_ 1140 VCLEFT_epbmUnitStatus "Electronic Parking Brake Monitors state.";
CM_ SG_ 1140 VCLEFT_epbmCdpState "Left body controller: epbm cdp state";
CM_ SG_ 1140 VCLEFT_epbmStatusCounter "Left body controller: epbm status counter";
CM_ SG_ 1140 VCLEFT_epbmStatusChecksum "Left body controller: epbm status checksum";
CM_ BO_ 770 "Left body controller message: info";
CM_ SG_ 770 VCLEFT_infoIndex "Left body controller: info index";
CM_ SG_ 770 VCLEFT_infoBuildType "Left body controller: info build type";
CM_ SG_ 770 VCLEFT_infoBuildConfigId "Left body controller: info build config id";
CM_ SG_ 770 VCLEFT_infoHardwareId "Left body controller: info hardware id";
CM_ SG_ 770 VCLEFT_infoComponentId "Left body controller: info component id";
CM_ SG_ 770 VCLEFT_infoPcbaId "Left body controller: info pcba id";
CM_ SG_ 770 VCLEFT_infoAssemblyId "Left body controller: info assembly id; raw 255 = signal not available (SNA)";
CM_ SG_ 770 VCLEFT_infoUsageId "Left body controller: info usage id";
CM_ SG_ 770 VCLEFT_infoSubUsageId "Left body controller: info sub usage id";
CM_ SG_ 770 VCLEFT_infoAppCrc "Left body controller: info app crc";
CM_ SG_ 770 VCLEFT_infoAppGitHash "Left body controller: info app git hash";
CM_ SG_ 770 VCLEFT_infoBootGitHash "Left body controller: info boot git hash";
CM_ SG_ 770 VCLEFT_infoPlatformType "Left body controller: info platform type";
CM_ SG_ 770 VCLEFT_infoBootUdsProtoVersion "Left body controller: info boot uds proto version";
CM_ SG_ 770 VCLEFT_infoBootCrc "Left body controller: info boot crc";
BA_DEF_ BO_ "GenMsgCycleTime" INT 0 3600000;
BA_DEF_ BO_ "GenMsgSendType" ENUM "Cyclic","NotUsed","NotUsed","NotUsed","NotUsed","NotUsed","NotUsed","IfActive","NoMsgSendType","NotUsed";
BA_DEF_ BO_ "VFrameFormat" ENUM "StandardCAN","ExtendedCAN","reserved","J1939PG","reserved","reserved","reserved","reserved","reserved","reserved","reserved","reserved","reserved","reserved","StandardCAN_FD","ExtendedCAN_FD";
BA_DEF_ BO_ "CANFD_BRS" ENUM "0","1";
BA_DEF_ SG_ "GenSigSNA" STRING;
BA_DEF_ SG_ "SystemSignalLongSymbol" STRING;
BA_DEF_ SG_ "Confidence" ENUM "validated","plausible","layout-only","contradicted";
BA_DEF_DEF_ "GenMsgCycleTime" 0;
BA_DEF_DEF_ "GenMsgSendType" "NoMsgSendType";
BA_DEF_DEF_ "VFrameFormat" "StandardCAN";
BA_DEF_DEF_ "CANFD_BRS" "1";
BA_DEF_DEF_ "GenSigSNA" "";
BA_DEF_DEF_ "SystemSignalLongSymbol" "";
BA_DEF_DEF_ "Confidence" "layout-only";
BA_ "GenMsgCycleTime" BO_ 628 500;
BA_ "GenMsgSendType" BO_ 628 0;
BA_ "GenMsgCycleTime" BO_ 853 1000;
BA_ "GenMsgSendType" BO_ 853 0;
BA_ "GenMsgCycleTime" BO_ 644 500;
BA_ "GenMsgSendType" BO_ 644 0;
BA_ "GenMsgCycleTime" BO_ 595 500;
BA_ "GenMsgSendType" BO_ 595 0;
BA_ "GenMsgCycleTime" BO_ 609 16;
BA_ "GenMsgSendType" BO_ 609 0;
BA_ "GenMsgCycleTime" BO_ 2017 100;
BA_ "GenMsgSendType" BO_ 2017 0;
BA_ "GenMsgCycleTime" BO_ 2016 1000;
BA_ "GenMsgSendType" BO_ 2016 0;
BA_ "GenMsgCycleTime" BO_ 545 50;
BA_ "GenMsgSendType" BO_ 545 0;
BA_ "GenMsgCycleTime" BO_ 753 100;
BA_ "GenMsgSendType" BO_ 753 0;
BA_ "GenMsgCycleTime" BO_ 769 1000;
BA_ "GenMsgSendType" BO_ 769 0;
BA_ "GenMsgCycleTime" BO_ 1801 322;
BA_ "GenMsgSendType" BO_ 1801 0;
BA_ "GenMsgCycleTime" BO_ 705 20;
BA_ "GenMsgSendType" BO_ 705 0;
BA_ "GenMsgCycleTime" BO_ 897 38;
BA_ "GenMsgSendType" BO_ 897 0;
BA_ "GenMsgCycleTime" BO_ 513 25;
BA_ "GenMsgSendType" BO_ 513 0;
BA_ "GenMsgCycleTime" BO_ 737 14;
BA_ "GenMsgSendType" BO_ 737 0;
BA_ "GenMsgCycleTime" BO_ 929 50;
BA_ "GenMsgSendType" BO_ 929 0;
BA_ "GenMsgCycleTime" BO_ 258 100;
BA_ "GenMsgSendType" BO_ 258 0;
BA_ "GenMsgCycleTime" BO_ 626 100;
BA_ "GenMsgSendType" BO_ 626 0;
BA_ "GenMsgCycleTime" BO_ 1140 100;
BA_ "GenMsgSendType" BO_ 1140 0;
BA_ "GenMsgCycleTime" BO_ 770 1000;
BA_ "GenMsgSendType" BO_ 770 0;
BA_ "Confidence" SG_ 628 UI_lightFlashRequest 0;
BA_ "Confidence" SG_ 628 UI_phoneCallActive 0;
BA_ "Confidence" SG_ 628 UI_lightShowClosuresEnabled 0;
BA_ "Confidence" SG_ 628 UI_steeringWheelHeatAutoReq 0;
BA_ "Confidence" SG_ 628 UI_steeringWheelHeatLevelReq 0;
BA_ "Confidence" SG_ 628 UI_headlightPulseRequest 0;
BA_ "Confidence" SG_ 628 UI_displayRedShiftActive 0;
BA_ "Confidence" SG_ 628 UI_fasciaCameraWashRequest 0;
BA_ "Confidence" SG_ 628 UI_leftRearSeatAdjustmentRequest 0;
BA_ "Confidence" SG_ 628 UI_rightRearSeatAdjustmentReques 0;
BA_ "SystemSignalLongSymbol" SG_ 628 UI_rightRearSeatAdjustmentReques "UI_rightRearSeatAdjustmentRequest";
BA_ "Confidence" SG_ 628 UI_blindSpotIndicatorLightReques 0;
BA_ "SystemSignalLongSymbol" SG_ 628 UI_blindSpotIndicatorLightReques "UI_blindSpotIndicatorLightRequest";
BA_ "Confidence" SG_ 628 UI_keepOnAccessoryPortsReq 0;
BA_ "Confidence" SG_ 628 UI_fasciaCameraShown 0;
BA_ "Confidence" SG_ 628 UI_rearSeatChildLock 0;
BA_ "Confidence" SG_ 628 UI_windowPercentageRequest 0;
BA_ "Confidence" SG_ 628 UI_windowRequestedFL 0;
BA_ "Confidence" SG_ 628 UI_windowRequestedFR 0;
BA_ "Confidence" SG_ 628 UI_windowRequestedRL 0;
BA_ "Confidence" SG_ 628 UI_windowRequestedRR 0;
BA_ "Confidence" SG_ 628 UI_windowRequest 0;
BA_ "Confidence" SG_ 628 UI_closeTrunkRequest 0;
BA_ "Confidence" SG_ 628 UI_childPresenceDetectionDisable 0;
BA_ "SystemSignalLongSymbol" SG_ 628 UI_childPresenceDetectionDisable "UI_childPresenceDetectionDisableRequest";
BA_ "Confidence" SG_ 628 UI_derivedLoadshedFeature 0;
BA_ "Confidence" SG_ 628 UI_selfParkStandingBy 0;
BA_ "Confidence" SG_ 853 UI_coolantFlowRequest 0;
BA_ "Confidence" SG_ 853 UI_inletActiveCoolTarget 0;
BA_ "Confidence" SG_ 853 UI_disableHVPTThermalLoads 0;
BA_ "Confidence" SG_ 644 UI_transportMode 0;
BA_ "Confidence" SG_ 644 UI_showroomMode 0;
BA_ "Confidence" SG_ 644 UI_serviceMode 0;
BA_ "Confidence" SG_ 644 UI_carWashMode 0;
BA_ "Confidence" SG_ 644 UI_gameMode 0;
BA_ "Confidence" SG_ 644 UI_serviceModePlus 0;
BA_ "Confidence" SG_ 644 UI_premiumAmpPowerOff 0;
BA_ "Confidence" SG_ 644 UI_lightShowType 0;
BA_ "Confidence" SG_ 595 UI_ventPanelControlRequestIndex 1;
BA_ "Confidence" SG_ 595 UI_ventPanelLeftPositionX 0;
BA_ "Confidence" SG_ 595 UI_ventPanelLeftPositionY 0;
BA_ "Confidence" SG_ 595 UI_ventPanelLeftLateralSplit 0;
BA_ "Confidence" SG_ 595 UI_ventPanelRightPositionX 0;
BA_ "Confidence" SG_ 595 UI_ventPanelRightPositionY 0;
BA_ "Confidence" SG_ 595 UI_ventPanelRightLateralSplit 0;
BA_ "Confidence" SG_ 595 UI_ventPanelLeftLateralMode 0;
BA_ "Confidence" SG_ 595 UI_ventPanelRightLateralMode 0;
BA_ "Confidence" SG_ 595 UI_hvacReqActiveVents 0;
BA_ "Confidence" SG_ 595 UI_vent2RLeftPositionX 0;
BA_ "Confidence" SG_ 595 UI_vent2RLeftPositionY 0;
BA_ "Confidence" SG_ 595 UI_vent2RRightPositionX 0;
BA_ "Confidence" SG_ 595 UI_vent2RRightPositionY 0;
BA_ "Confidence" SG_ 609 VCFRONT_12VBatteryStatusIndex 1;
BA_ "Confidence" SG_ 609 VCFRONT_good12VforUpdate 0;
BA_ "Confidence" SG_ 609 VCFRONT_LVLoadRequest 0;
BA_ "Confidence" SG_ 609 VCFRONT_12VBatteryStatusCounter 0;
BA_ "Confidence" SG_ 609 VCFRONT_12VBatteryStatusChecksum 0;
BA_ "Confidence" SG_ 609 VCFRONT_batterySupportRequest 0;
BA_ "Confidence" SG_ 609 VCFRONT_batterySMState 0;
BA_ "Confidence" SG_ 609 VCFRONT_eFuseRecoveryStateDBG 0;
BA_ "Confidence" SG_ 609 VCFRONT_batteryLINScheduleDBG 0;
BA_ "GenSigSNA" SG_ 609 VCFRONT_batteryLINScheduleDBG "7";
BA_ "Confidence" SG_ 609 VCFRONT_resistanceEstimationTest 0;
BA_ "SystemSignalLongSymbol" SG_ 609 VCFRONT_resistanceEstimationTest "VCFRONT_resistanceEstimationTestCounter";
BA_ "Confidence" SG_ 609 VCFRONT_IBSCurrent 0;
BA_ "Confidence" SG_ 609 VCFRONT_IBSVoltage 0;
BA_ "GenSigSNA" SG_ 609 VCFRONT_IBSVoltage "4095";
BA_ "Confidence" SG_ 609 VCFRONT_reverseBatteryFault 0;
BA_ "Confidence" SG_ 609 VCFRONT_LVBatterySupported 0;
BA_ "Confidence" SG_ 609 VCFRONT_LVBatteryCannotSupportVe 0;
BA_ "SystemSignalLongSymbol" SG_ 609 VCFRONT_LVBatteryCannotSupportVe "VCFRONT_LVBatteryCannotSupportVehicle";
BA_ "Confidence" SG_ 609 VCFRONT_goodTemp12VforUpdate 0;
BA_ "Confidence" SG_ 609 VCFRONT_12VBatteryTargetVoltage 0;
BA_ "Confidence" SG_ 609 VCFRONT_IBSTemperature 0;
BA_ "GenSigSNA" SG_ 609 VCFRONT_IBSTemperature "2047";
BA_ "Confidence" SG_ 609 VCFRONT_currentSensorMismatchLea 0;
BA_ "SystemSignalLongSymbol" SG_ 609 VCFRONT_currentSensorMismatchLea "VCFRONT_currentSensorMismatchLeakyBktPctDBG";
BA_ "Confidence" SG_ 609 VCFRONT_LVBatteryEnergyRemaining 0;
BA_ "SystemSignalLongSymbol" SG_ 609 VCFRONT_LVBatteryEnergyRemaining "VCFRONT_LVBatteryEnergyRemainingPCT";
BA_ "Confidence" SG_ 609 VCFRONT_LVBatteryStatusForDrive 0;
BA_ "Confidence" SG_ 609 VCFRONT_LVBatteryType 0;
BA_ "Confidence" SG_ 609 VCFRONT_resistanceEstimationNeed 0;
BA_ "SystemSignalLongSymbol" SG_ 609 VCFRONT_resistanceEstimationNeed "VCFRONT_resistanceEstimationNeeded";
BA_ "Confidence" SG_ 609 VCFRONT_IBSVoltageFiltered 0;
BA_ "GenSigSNA" SG_ 609 VCFRONT_IBSVoltageFiltered "16383";
BA_ "Confidence" SG_ 609 VCFRONT_LVBMS_LVBusVoltageSource 0;
BA_ "SystemSignalLongSymbol" SG_ 609 VCFRONT_LVBMS_LVBusVoltageSource "VCFRONT_LVBMS_LVBusVoltageSourceDBG";
BA_ "Confidence" SG_ 609 VCFRONT_LVBMS_LVPackCurrentSourc 0;
BA_ "SystemSignalLongSymbol" SG_ 609 VCFRONT_LVBMS_LVPackCurrentSourc "VCFRONT_LVBMS_LVPackCurrentSourceDBG";
BA_ "Confidence" SG_ 609 VCFRONT_LVBatterySupportRqrdTrig 0;
BA_ "SystemSignalLongSymbol" SG_ 609 VCFRONT_LVBatterySupportRqrdTrig "VCFRONT_LVBatterySupportRqrdTrigger";
BA_ "Confidence" SG_ 609 VCFRONT_goodForPCSPowerCycleLeak 0;
BA_ "SystemSignalLongSymbol" SG_ 609 VCFRONT_goodForPCSPowerCycleLeak "VCFRONT_goodForPCSPowerCycleLeakyBktDBG";
BA_ "Confidence" SG_ 609 VCFRONT_LVBusControlsFutile 0;
BA_ "Confidence" SG_ 609 VCFRONT_resistanceEstimatio_0001 0;
BA_ "SystemSignalLongSymbol" SG_ 609 VCFRONT_resistanceEstimatio_0001 "VCFRONT_resistanceEstimationTestValid";
BA_ "Confidence" SG_ 609 VCFRONT_resistanceEstimatio_0002 0;
BA_ "SystemSignalLongSymbol" SG_ 609 VCFRONT_resistanceEstimatio_0002 "VCFRONT_resistanceEstimationTestsExpended";
BA_ "Confidence" SG_ 609 VCFRONT_goodLVChargeForUpdate 0;
BA_ "Confidence" SG_ 609 VCFRONT_opportunisticDCRTestNeed 0;
BA_ "SystemSignalLongSymbol" SG_ 609 VCFRONT_opportunisticDCRTestNeed "VCFRONT_opportunisticDCRTestNeeded";
BA_ "Confidence" SG_ 609 VCFRONT_voltageProfile 0;
BA_ "Confidence" SG_ 609 VCFRONT_IBSAmpHours 0;
BA_ "Confidence" SG_ 609 VCFRONT_IBSVoltageRawDBG 0;
BA_ "GenSigSNA" SG_ 609 VCFRONT_IBSVoltageRawDBG "16383";
BA_ "Confidence" SG_ 609 VCFRONT_LVBatteryLINCommsDetecte 0;
BA_ "SystemSignalLongSymbol" SG_ 609 VCFRONT_LVBatteryLINCommsDetecte "VCFRONT_LVBatteryLINCommsDetectedDBG";
BA_ "Confidence" SG_ 609 VCFRONT_voltageSensorMismatchLea 0;
BA_ "SystemSignalLongSymbol" SG_ 609 VCFRONT_voltageSensorMismatchLea "VCFRONT_voltageSensorMismatchLeakyBktPctDBG";
BA_ "Confidence" SG_ 609 VCFRONT_LVBatteryFctryLimOverrid 0;
BA_ "SystemSignalLongSymbol" SG_ 609 VCFRONT_LVBatteryFctryLimOverrid "VCFRONT_LVBatteryFctryLimOverrideOk";
BA_ "Confidence" SG_ 609 VCFRONT_LVBatterySPICommsDetecte 0;
BA_ "SystemSignalLongSymbol" SG_ 609 VCFRONT_LVBatterySPICommsDetecte "VCFRONT_LVBatterySPICommsDetectedDBG";
BA_ "Confidence" SG_ 609 VCFRONT_targetCurrent 0;
BA_ "Confidence" SG_ 609 VCFRONT_PCSMia 0;
BA_ "Confidence" SG_ 609 VCFRONT_chargeNeeded 0;
BA_ "Confidence" SG_ 609 VCFRONT_voltageControlLoopIntegr 0;
BA_ "SystemSignalLongSymbol" SG_ 609 VCFRONT_voltageControlLoopIntegr "VCFRONT_voltageControlLoopIntegrationVal";
BA_ "Confidence" SG_ 609 VCFRONT_currentControlLoopIntegr 0;
BA_ "SystemSignalLongSymbol" SG_ 609 VCFRONT_currentControlLoopIntegr "VCFRONT_currentControlLoopIntegrationVal";
BA_ "Confidence" SG_ 2017 VCFRONT_LVHealthStatus 1;
BA_ "Confidence" SG_ 2017 VCFRONT_LVStatusForDrive 1;
BA_ "Confidence" SG_ 2017 VCFRONT_LVPowerSecondsToSafeHarb 1;
BA_ "SystemSignalLongSymbol" SG_ 2017 VCFRONT_LVPowerSecondsToSafeHarb "VCFRONT_LVPowerSecondsToSafeHarbor";
BA_ "Confidence" SG_ 2016 VCFRONT_LVHealthDebugIndex 1;
BA_ "Confidence" SG_ 2016 VCFRONT_LVHEALTH_placeholder 0;
BA_ "Confidence" SG_ 2016 VCFRONT_LVHEALTH_activeDecelEner 0;
BA_ "SystemSignalLongSymbol" SG_ 2016 VCFRONT_LVHEALTH_activeDecelEner "VCFRONT_LVHEALTH_activeDecelEnergyWarning";
BA_ "Confidence" SG_ 2016 VCFRONT_LVHEALTH_criticalPullove 0;
BA_ "SystemSignalLongSymbol" SG_ 2016 VCFRONT_LVHEALTH_criticalPullove "VCFRONT_LVHEALTH_criticalPulloverEnergyWarning";
BA_ "Confidence" SG_ 2016 VCFRONT_LVHEALTH_revBattEFuseOff 0;
BA_ "Confidence" SG_ 2016 VCFRONT_LVHEALTH_LVBMBEFuseOpen 0;
BA_ "Confidence" SG_ 2016 VCFRONT_LVHEALTH_lvBatteryCommsM 0;
BA_ "SystemSignalLongSymbol" SG_ 2016 VCFRONT_LVHEALTH_lvBatteryCommsM "VCFRONT_LVHEALTH_lvBatteryCommsMia";
BA_ "Confidence" SG_ 2016 VCFRONT_LVHEALTH_pcsEFuseOff 0;
BA_ "Confidence" SG_ 2016 VCFRONT_LVHEALTH_pcsNotActive 0;
BA_ "Confidence" SG_ 2016 VCFRONT_LVHEALTH_pcsMIA 0;
BA_ "Confidence" SG_ 2016 VCFRONT_LVHEALTH_IBSMIA 0;
BA_ "Confidence" SG_ 2016 VCFRONT_LVHEALTH_LVBatteryElecDi 0;
BA_ "SystemSignalLongSymbol" SG_ 2016 VCFRONT_LVHEALTH_LVBatteryElecDi "VCFRONT_LVHEALTH_LVBatteryElecDisc";
BA_ "Confidence" SG_ 2016 VCFRONT_LVHEALTH_LVBatteryE_0001 0;
BA_ "SystemSignalLongSymbol" SG_ 2016 VCFRONT_LVHEALTH_LVBatteryE_0001 "VCFRONT_LVHEALTH_LVBatteryElecDiscUnknown";
BA_ "Confidence" SG_ 2016 VCFRONT_LVHEALTH_pcsOpenCircuit 0;
BA_ "Confidence" SG_ 2016 VCFRONT_LVHEALTH_activeDecelPowe 0;
BA_ "SystemSignalLongSymbol" SG_ 2016 VCFRONT_LVHEALTH_activeDecelPowe "VCFRONT_LVHEALTH_activeDecelPowerWarning";
BA_ "Confidence" SG_ 2016 VCFRONT_LVHEALTH_lvBatteryCapabi 0;
BA_ "SystemSignalLongSymbol" SG_ 2016 VCFRONT_LVHEALTH_lvBatteryCapabi "VCFRONT_LVHEALTH_lvBatteryCapabilityLowAccuracy";
BA_ "Confidence" SG_ 2016 VCFRONT_LVHEALTH_lvBatteryConfig 0;
BA_ "SystemSignalLongSymbol" SG_ 2016 VCFRONT_LVHEALTH_lvBatteryConfig "VCFRONT_LVHEALTH_lvBatteryConfiguration";
BA_ "Confidence" SG_ 2016 VCFRONT_LVHEALTH_lvBatteryImpeda 0;
BA_ "SystemSignalLongSymbol" SG_ 2016 VCFRONT_LVHEALTH_lvBatteryImpeda "VCFRONT_LVHEALTH_lvBatteryImpedance";
BA_ "Confidence" SG_ 545 VCFRONT_LVPowerStateIndex 1;
BA_ "Confidence" SG_ 545 VCFRONT_vehiclePowerState 0;
BA_ "Confidence" SG_ 545 VCFRONT_inAccessoryPlus 0;
BA_ "Confidence" SG_ 545 VCFRONT_LVShuttingDown 0;
BA_ "Confidence" SG_ 545 VCFRONT_LVPowerStateCounter 0;
BA_ "Confidence" SG_ 545 VCFRONT_LVPowerStateChecksum 0;
BA_ "Confidence" SG_ 545 VCFRONT_cpLVRequest 0;
BA_ "Confidence" SG_ 545 VCFRONT_epasLVState 0;
BA_ "Confidence" SG_ 545 VCFRONT_hvcLVRequest 0;
BA_ "Confidence" SG_ 545 VCFRONT_tasLVState 0;
BA_ "Confidence" SG_ 545 VCFRONT_pcsLVState 0;
BA_ "Confidence" SG_ 545 VCFRONT_CMPDLVState 0;
BA_ "Confidence" SG_ 545 VCFRONT_hcmlLVState 0;
BA_ "Confidence" SG_ 545 VCFRONT_hcmrLVState 0;
BA_ "Confidence" SG_ 545 VCFRONT_MCUAudioLVState 0;
BA_ "Confidence" SG_ 545 VCFRONT_espValveLVState 0;
BA_ "Confidence" SG_ 545 VCFRONT_MCUGraphicsLVState 0;
BA_ "Confidence" SG_ 545 VC_dcdcSupportRequest 0;
BA_ "Confidence" SG_ 545 VC_hvStateRequest 0;
BA_ "Confidence" SG_ 545 VC_persistAccPowerRequestOverrid 0;
BA_ "SystemSignalLongSymbol" SG_ 545 VC_persistAccPowerRequestOverrid "VC_persistAccPowerRequestOverridden";
BA_ "Confidence" SG_ 545 VC_accPortPowerRequest 0;
BA_ "Confidence" SG_ 545 VC_persistAccPortPowerState 0;
BA_ "Confidence" SG_ 753 VCFRONT_eFuseDebugStatusIndex 1;
BA_ "Confidence" SG_ 753 VCFRONT_leftControllerState 0;
BA_ "GenSigSNA" SG_ 753 VCFRONT_leftControllerState "3";
BA_ "Confidence" SG_ 753 VCFRONT_leftControllerFault 0;
BA_ "Confidence" SG_ 753 VCFRONT_vcleftSelfTestResult 0;
BA_ "GenSigSNA" SG_ 753 VCFRONT_vcleftSelfTestResult "12";
BA_ "Confidence" SG_ 753 VCFRONT_leftControllerTemp 0;
BA_ "Confidence" SG_ 753 VCFRONT_leftControllerEFuseVNFSt 0;
BA_ "SystemSignalLongSymbol" SG_ 753 VCFRONT_leftControllerEFuseVNFSt "VCFRONT_leftControllerEFuseVNFState";
BA_ "Confidence" SG_ 753 VCFRONT_leftControllerEFuseOutpu 0;
BA_ "SystemSignalLongSymbol" SG_ 753 VCFRONT_leftControllerEFuseOutpu "VCFRONT_leftControllerEFuseOutput";
BA_ "Confidence" SG_ 753 VCFRONT_leftControllerEFuse_0002 0;
BA_ "SystemSignalLongSymbol" SG_ 753 VCFRONT_leftControllerEFuse_0002 "VCFRONT_leftControllerEFuseOutputDesired";
BA_ "Confidence" SG_ 753 VCFRONT_leftControllerVoltage 0;
BA_ "Confidence" SG_ 753 VCFRONT_leftControllerEFuseBypas 0;
BA_ "SystemSignalLongSymbol" SG_ 753 VCFRONT_leftControllerEFuseBypas "VCFRONT_leftControllerEFuseBypass";
BA_ "Confidence" SG_ 753 VCFRONT_leftControllerEFuse_0001 0;
BA_ "SystemSignalLongSymbol" SG_ 753 VCFRONT_leftControllerEFuse_0001 "VCFRONT_leftControllerEFuseBypassDesired";
BA_ "Confidence" SG_ 753 VCFRONT_leftControllerCurrent 0;
BA_ "Confidence" SG_ 753 VCFRONT_leftControllerEFuseVNFSe 0;
BA_ "SystemSignalLongSymbol" SG_ 753 VCFRONT_leftControllerEFuseVNFSe "VCFRONT_leftControllerEFuseVNFSelfTestStatus";
BA_ "Confidence" SG_ 753 VCFRONT_PCSState 0;
BA_ "GenSigSNA" SG_ 753 VCFRONT_PCSState "3";
BA_ "Confidence" SG_ 753 VCFRONT_PCSFault 0;
BA_ "Confidence" SG_ 753 VCFRONT_pcsSelfTestResult 0;
BA_ "GenSigSNA" SG_ 753 VCFRONT_pcsSelfTestResult "12";
BA_ "Confidence" SG_ 753 VCFRONT_PCSTemp 0;
BA_ "Confidence" SG_ 753 VCFRONT_PCSEFuseVNFState 0;
BA_ "Confidence" SG_ 753 VCFRONT_PCSEFuseOutput 0;
BA_ "Confidence" SG_ 753 VCFRONT_PCSEFuseOutputDesired 0;
BA_ "Confidence" SG_ 753 VCFRONT_PCSVoltage 0;
BA_ "Confidence" SG_ 753 VCFRONT_PCSEFuseBypass 0;
BA_ "Confidence" SG_ 753 VCFRONT_PCSEFuseBypassDesired 0;
BA_ "Confidence" SG_ 753 VCFRONT_PCSEFuseVNFSelfTestStatu 0;
BA_ "SystemSignalLongSymbol" SG_ 753 VCFRONT_PCSEFuseVNFSelfTestStatu "VCFRONT_PCSEFuseVNFSelfTestStatus";
BA_ "Confidence" SG_ 753 VCFRONT_iBoosterState 0;
BA_ "GenSigSNA" SG_ 753 VCFRONT_iBoosterState "3";
BA_ "Confidence" SG_ 753 VCFRONT_iBoosterFault 0;
BA_ "Confidence" SG_ 753 VCFRONT_iBoosterSelfTestResult 0;
BA_ "GenSigSNA" SG_ 753 VCFRONT_iBoosterSelfTestResult "12";
BA_ "Confidence" SG_ 753 VCFRONT_iBoosterTemp 0;
BA_ "Confidence" SG_ 753 VCFRONT_iBoosterVoltage 1;
BA_ "Confidence" SG_ 753 VCFRONT_iBoosterCurrent 0;
BA_ "Confidence" SG_ 753 VCFRONT_EPAS3PState 0;
BA_ "GenSigSNA" SG_ 753 VCFRONT_EPAS3PState "3";
BA_ "Confidence" SG_ 753 VCFRONT_EPAS3PFault 0;
BA_ "Confidence" SG_ 753 VCFRONT_EPAS3PSelfTestResult 0;
BA_ "GenSigSNA" SG_ 753 VCFRONT_EPAS3PSelfTestResult "12";
BA_ "Confidence" SG_ 753 VCFRONT_EPAS3PTemp 0;
BA_ "Confidence" SG_ 753 VCFRONT_EPAS3PEFuseVNFState 0;
BA_ "Confidence" SG_ 753 VCFRONT_EPAS3PEFuseOutput 0;
BA_ "Confidence" SG_ 753 VCFRONT_EPAS3PEFuseOutputDesired 0;
BA_ "Confidence" SG_ 753 VCFRONT_EPAS3PVoltage 0;
BA_ "Confidence" SG_ 753 VCFRONT_EPAS3PEFuseHardshortThre 0;
BA_ "SystemSignalLongSymbol" SG_ 753 VCFRONT_EPAS3PEFuseHardshortThre "VCFRONT_EPAS3PEFuseHardshortThresholdDbg";
BA_ "Confidence" SG_ 753 VCFRONT_EPAS3PEFuseBypass 0;
BA_ "Confidence" SG_ 753 VCFRONT_EPAS3PEFuseBypassDesired 0;
BA_ "Confidence" SG_ 753 VCFRONT_EPAS3PCurrent 0;
BA_ "Confidence" SG_ 753 VCFRONT_EPAS3PEFuseVNFSelfTestSt 0;
BA_ "SystemSignalLongSymbol" SG_ 753 VCFRONT_EPAS3PEFuseVNFSelfTestSt "VCFRONT_EPAS3PEFuseVNFSelfTestStatus";
BA_ "Confidence" SG_ 753 VCFRONT_EPAS3SState 0;
BA_ "GenSigSNA" SG_ 753 VCFRONT_EPAS3SState "3";
BA_ "Confidence" SG_ 753 VCFRONT_EPAS3SFault 0;
BA_ "Confidence" SG_ 753 VCFRONT_EPAS3SSelfTestResult 0;
BA_ "GenSigSNA" SG_ 753 VCFRONT_EPAS3SSelfTestResult "12";
BA_ "Confidence" SG_ 753 VCFRONT_EPAS3STemp 0;
BA_ "Confidence" SG_ 753 VCFRONT_EPAS3SEFuseVNFState 0;
BA_ "Confidence" SG_ 753 VCFRONT_EPAS3SEFuseOutput 0;
BA_ "Confidence" SG_ 753 VCFRONT_EPAS3SEFuseOutputDesired 0;
BA_ "Confidence" SG_ 753 VCFRONT_EPAS3SVoltage 0;
BA_ "Confidence" SG_ 753 VCFRONT_EPAS3SEFuseBypass 0;
BA_ "Confidence" SG_ 753 VCFRONT_EPAS3SEFuseBypassDesired 0;
BA_ "Confidence" SG_ 753 VCFRONT_EPAS3SCurrent 0;
BA_ "Confidence" SG_ 753 VCFRONT_EPAS3SEFuseVNFSelfTestSt 0;
BA_ "SystemSignalLongSymbol" SG_ 753 VCFRONT_EPAS3SEFuseVNFSelfTestSt "VCFRONT_EPAS3SEFuseVNFSelfTestStatus";
BA_ "Confidence" SG_ 753 VCFRONT_ESPMotorState 0;
BA_ "GenSigSNA" SG_ 753 VCFRONT_ESPMotorState "3";
BA_ "Confidence" SG_ 753 VCFRONT_ESPMotorFault 0;
BA_ "Confidence" SG_ 753 VCFRONT_ESPMotorSelfTestResult 0;
BA_ "GenSigSNA" SG_ 753 VCFRONT_ESPMotorSelfTestResult "12";
BA_ "Confidence" SG_ 753 VCFRONT_ESPMotorTemp 0;
BA_ "Confidence" SG_ 753 VCFRONT_ESPMotorEFuseVNFState 0;
BA_ "Confidence" SG_ 753 VCFRONT_ESPMotorEFuseOutput 0;
BA_ "Confidence" SG_ 753 VCFRONT_ESPMotorEFuseOutputDesir 0;
BA_ "SystemSignalLongSymbol" SG_ 753 VCFRONT_ESPMotorEFuseOutputDesir "VCFRONT_ESPMotorEFuseOutputDesired";
BA_ "Confidence" SG_ 753 VCFRONT_ESPMotorVoltage 0;
BA_ "Confidence" SG_ 753 VCFRONT_ESPMotorEFuseBypass 0;
BA_ "Confidence" SG_ 753 VCFRONT_ESPMotorEFuseBypassDesir 0;
BA_ "SystemSignalLongSymbol" SG_ 753 VCFRONT_ESPMotorEFuseBypassDesir "VCFRONT_ESPMotorEFuseBypassDesired";
BA_ "Confidence" SG_ 753 VCFRONT_ESPMotorCurrent 0;
BA_ "Confidence" SG_ 753 VCFRONT_ESPMotorEFuseVNFSelfTest 0;
BA_ "SystemSignalLongSymbol" SG_ 753 VCFRONT_ESPMotorEFuseVNFSelfTest "VCFRONT_ESPMotorEFuseVNFSelfTestStatus";
BA_ "Confidence" SG_ 753 VCFRONT_ESPValveState 0;
BA_ "GenSigSNA" SG_ 753 VCFRONT_ESPValveState "3";
BA_ "Confidence" SG_ 753 VCFRONT_ESPValveFault 0;
BA_ "Confidence" SG_ 753 VCFRONT_ESPValveTemp 0;
BA_ "Confidence" SG_ 753 VCFRONT_ESPValveVoltage 0;
BA_ "Confidence" SG_ 753 VCFRONT_ESPValveCurrent 0;
BA_ "Confidence" SG_ 753 VCFRONT_autopilot2State 0;
BA_ "GenSigSNA" SG_ 753 VCFRONT_autopilot2State "3";
BA_ "Confidence" SG_ 753 VCFRONT_autopilot2Fault 0;
BA_ "Confidence" SG_ 753 VCFRONT_autopilot2Temp 0;
BA_ "Confidence" SG_ 753 VCFRONT_autopilot2Voltage 0;
BA_ "Confidence" SG_ 753 VCFRONT_autopilot2Current 0;
BA_ "Confidence" SG_ 753 VCFRONT_sleepBypassState 0;
BA_ "Confidence" SG_ 753 VCFRONT_sleepBypassFault 0;
BA_ "Confidence" SG_ 753 VCFRONT_sleepBypassVoltage 0;
BA_ "Confidence" SG_ 753 VCFRONT_sleepBypassCurrent 0;
BA_ "Confidence" SG_ 753 VCFRONT_vbatFusedHighState 0;
BA_ "Confidence" SG_ 753 VCFRONT_vbatFusedHighFault 0;
BA_ "Confidence" SG_ 753 VCFRONT_vbatFusedSelfTestResult 0;
BA_ "GenSigSNA" SG_ 753 VCFRONT_vbatFusedSelfTestResult "12";
BA_ "Confidence" SG_ 753 VCFRONT_vbatFusedHighTemp 0;
BA_ "Confidence" SG_ 753 VCFRONT_vbatFusedHighVoltage 0;
BA_ "Confidence" SG_ 753 VCFRONT_vbatFusedHighCurrent 0;
BA_ "Confidence" SG_ 753 VCFRONT_chargedIBSAmpHours 0;
BA_ "Confidence" SG_ 753 VCFRONT_dischargedIBSAmpHours 0;
BA_ "Confidence" SG_ 753 VCFRONT_IBSUnfilteredTemperature 0;
BA_ "GenSigSNA" SG_ 753 VCFRONT_IBSUnfilteredTemperature "32768";
BA_ "Confidence" SG_ 769 VCFRONT_infoIndex 1;
BA_ "Confidence" SG_ 769 VCFRONT_infoBuildType 0;
BA_ "Confidence" SG_ 769 VCFRONT_infoBuildConfigId 0;
BA_ "Confidence" SG_ 769 VCFRONT_infoHardwareId 0;
BA_ "Confidence" SG_ 769 VCFRONT_infoComponentId 0;
BA_ "Confidence" SG_ 769 VCFRONT_infoPcbaId 0;
BA_ "Confidence" SG_ 769 VCFRONT_infoAssemblyId 0;
BA_ "GenSigSNA" SG_ 769 VCFRONT_infoAssemblyId "255";
BA_ "Confidence" SG_ 769 VCFRONT_infoUsageId 0;
BA_ "Confidence" SG_ 769 VCFRONT_infoSubUsageId 0;
BA_ "Confidence" SG_ 769 VCFRONT_infoAppCrc 0;
BA_ "Confidence" SG_ 769 VC_infoHCMLAppCRC 0;
BA_ "Confidence" SG_ 769 VCFRONT_infoAppGitHash 0;
BA_ "Confidence" SG_ 769 VCFRONT_infoBootGitHash 0;
BA_ "Confidence" SG_ 769 VCFRONT_infoPlatformType 0;
BA_ "Confidence" SG_ 769 VCFRONT_infoBootUdsProtoVersion 0;
BA_ "Confidence" SG_ 769 VCFRONT_infoBootCrc 0;
BA_ "Confidence" SG_ 769 VC_infoHCMRAppCRC 0;
BA_ "Confidence" SG_ 1801 VCFRONT_logging0point1HzIndex 1;
BA_ "Confidence" SG_ 1801 VC_hcmlFactoryOfOrigin 1;
BA_ "Confidence" SG_ 1801 VC_hcmlHellaPartNumberStatus 1;
BA_ "Confidence" SG_ 1801 VC_hcmlHellaPartNumber 1;
BA_ "Confidence" SG_ 1801 VC_hcmlCurrentBinMappingType 1;
BA_ "Confidence" SG_ 1801 VC_hcmlCurrentBin0Value 1;
BA_ "GenSigSNA" SG_ 1801 VC_hcmlCurrentBin0Value "0";
BA_ "Confidence" SG_ 1801 VC_hcmlCurrentBin1Value 1;
BA_ "GenSigSNA" SG_ 1801 VC_hcmlCurrentBin1Value "0";
BA_ "Confidence" SG_ 1801 VC_hcmlCurrentBin2Value 1;
BA_ "GenSigSNA" SG_ 1801 VC_hcmlCurrentBin2Value "0";
BA_ "Confidence" SG_ 1801 VC_hcmlCurrentBin3Value 1;
BA_ "GenSigSNA" SG_ 1801 VC_hcmlCurrentBin3Value "0";
BA_ "Confidence" SG_ 1801 VC_hcmlCurrentBin4Value 1;
BA_ "GenSigSNA" SG_ 1801 VC_hcmlCurrentBin4Value "0";
BA_ "Confidence" SG_ 1801 VC_hcmlCurrentBin5Value 1;
BA_ "GenSigSNA" SG_ 1801 VC_hcmlCurrentBin5Value "0";
BA_ "Confidence" SG_ 1801 VC_hcmlRegionAndSide 1;
BA_ "GenSigSNA" SG_ 1801 VC_hcmlRegionAndSide "0";
BA_ "Confidence" SG_ 1801 VC_hcmrFactoryOfOrigin 1;
BA_ "Confidence" SG_ 1801 VC_hcmrHellaPartNumberStatus 1;
BA_ "Confidence" SG_ 1801 VC_hcmrHellaPartNumber 1;
BA_ "Confidence" SG_ 1801 VC_hcmrCurrentBinMappingType 1;
BA_ "Confidence" SG_ 1801 VC_hcmrCurrentBin0Value 1;
BA_ "GenSigSNA" SG_ 1801 VC_hcmrCurrentBin0Value "0";
BA_ "Confidence" SG_ 1801 VC_hcmrCurrentBin1Value 1;
BA_ "GenSigSNA" SG_ 1801 VC_hcmrCurrentBin1Value "0";
BA_ "Confidence" SG_ 1801 VC_hcmrCurrentBin2Value 1;
BA_ "GenSigSNA" SG_ 1801 VC_hcmrCurrentBin2Value "0";
BA_ "Confidence" SG_ 1801 VC_hcmrCurrentBin3Value 1;
BA_ "GenSigSNA" SG_ 1801 VC_hcmrCurrentBin3Value "0";
BA_ "Confidence" SG_ 1801 VC_hcmrCurrentBin4Value 1;
BA_ "GenSigSNA" SG_ 1801 VC_hcmrCurrentBin4Value "0";
BA_ "Confidence" SG_ 1801 VC_hcmrCurrentBin5Value 1;
BA_ "GenSigSNA" SG_ 1801 VC_hcmrCurrentBin5Value "0";
BA_ "Confidence" SG_ 1801 VC_hcmrRegionAndSide 1;
BA_ "GenSigSNA" SG_ 1801 VC_hcmrRegionAndSide "0";
BA_ "Confidence" SG_ 705 VCFRONT_logging10HzIndex 1;
BA_ "Confidence" SG_ 705 VCFRONT_pumpBatteryOutVoltage 0;
BA_ "Confidence" SG_ 705 VCFRONT_pumpPowertrainOutVoltage 0;
BA_ "Confidence" SG_ 705 VCFRONT_pumpBatteryInitd 0;
BA_ "Confidence" SG_ 705 VCFRONT_pumpPowertrainInitd 0;
BA_ "Confidence" SG_ 705 VCFRONT_pumpBatteryEnabled 0;
BA_ "Confidence" SG_ 705 VCFRONT_pumpPowertrainEnabled 0;
BA_ "Confidence" SG_ 705 VCFRONT_pumpBatteryPowerOn 0;
BA_ "Confidence" SG_ 705 VCFRONT_pumpPowertrainPowerOn 0;
BA_ "Confidence" SG_ 705 VCFRONT_pumpsWake 0;
BA_ "Confidence" SG_ 705 VCFRONT_pumpBatSpiError 0;
BA_ "Confidence" SG_ 705 VCFRONT_pumpPtSpiError 0;
BA_ "Confidence" SG_ 705 VCFRONT_coolantFlowChillerActual 0;
BA_ "Confidence" SG_ 705 VCFRONT_radiatorFanOutVoltage 0;
BA_ "Confidence" SG_ 705 VCFRONT_radiatorFanInitd 0;
BA_ "Confidence" SG_ 705 VCFRONT_radiatorFanEnabled 0;
BA_ "Confidence" SG_ 705 VCFRONT_radiatorFanPowerOn 0;
BA_ "Confidence" SG_ 705 VCFRONT_radiatorFanPhaseCurrent 0;
BA_ "Confidence" SG_ 705 VCFRONT_radiatorFanPhaseIMax 0;
BA_ "Confidence" SG_ 705 VCFRONT_thmlFanSpiError 0;
BA_ "Confidence" SG_ 705 VCFRONT_chargeTrapNominalCOP1Bat 0;
BA_ "SystemSignalLongSymbol" SG_ 705 VCFRONT_chargeTrapNominalCOP1Bat "VCFRONT_chargeTrapNominalCOP1BattHeat";
BA_ "Confidence" SG_ 705 VCFRONT_chargeTrapNominalCOP1Chi 0;
BA_ "SystemSignalLongSymbol" SG_ 705 VCFRONT_chargeTrapNominalCOP1Chi "VCFRONT_chargeTrapNominalCOP1ChillerBattHeat";
BA_ "Confidence" SG_ 897 VCFRONT_logging1HzIndex 1;
BA_ "Confidence" SG_ 897 VCFRONT_modeTransitionID 0;
BA_ "Confidence" SG_ 897 VCFRONT_modeDesired 0;
BA_ "Confidence" SG_ 897 VCFRONT_targetPTActiveCool 0;
BA_ "Confidence" SG_ 897 VCFRONT_targetPtOptionalActiveCo 0;
BA_ "SystemSignalLongSymbol" SG_ 897 VCFRONT_targetPtOptionalActiveCo "VCFRONT_targetPtOptionalActiveCool";
BA_ "Confidence" SG_ 897 VCFRONT_targetPTPassive 0;
BA_ "Confidence" SG_ 897 VCFRONT_targetBatActiveCool 0;
BA_ "Confidence" SG_ 897 VCFRONT_targetBatOptionalActiveC 0;
BA_ "SystemSignalLongSymbol" SG_ 897 VCFRONT_targetBatOptionalActiveC "VCFRONT_targetBatOptionalActiveCool";
BA_ "Confidence" SG_ 897 VCFRONT_targetBatPassive 0;
BA_ "Confidence" SG_ 897 VCFRONT_targetBatActiveHeat 0;
BA_ "Confidence" SG_ 897 VCFRONT_condenserPressureLimit 0;
BA_ "Confidence" SG_ 897 VCFRONT_fanDemandCondenser 0;
BA_ "Confidence" SG_ 897 VCFRONT_fanDemandRadiator 0;
BA_ "Confidence" SG_ 897 VCFRONT_tempRefrigSuction 0;
BA_ "GenSigSNA" SG_ 897 VCFRONT_tempRefrigSuction "255";
BA_ "Confidence" SG_ 897 VCFRONT_pumpBatteryFETTemp 0;
BA_ "GenSigSNA" SG_ 897 VCFRONT_pumpBatteryFETTemp "255";
BA_ "Confidence" SG_ 897 VCFRONT_pumpPowertrainFETTemp 0;
BA_ "GenSigSNA" SG_ 897 VCFRONT_pumpPowertrainFETTemp "255";
BA_ "Confidence" SG_ 897 VCFRONT_radiatorFanFETTemp 0;
BA_ "GenSigSNA" SG_ 897 VCFRONT_radiatorFanFETTemp "255";
BA_ "Confidence" SG_ 897 VCFRONT_radiatorFanRunReason 0;
BA_ "Confidence" SG_ 897 VCFRONT_coolantValveModeWrong 0;
BA_ "Confidence" SG_ 897 VCFRONT_coolantTempBasedMode 0;
BA_ "Confidence" SG_ 897 VCFRONT_coolantValveRecalReason 0;
BA_ "Confidence" SG_ 897 VCFRONT_coolantValveCountRange 0;
BA_ "GenSigSNA" SG_ 897 VCFRONT_coolantValveCountRange "1023";
BA_ "Confidence" SG_ 897 VCFRONT_coolantValveAngleDrift 0;
BA_ "Confidence" SG_ 897 VCFRONT_coolantValveRecalCount 0;
BA_ "Confidence" SG_ 897 VCFRONT_coolantValveWindupEst 0;
BA_ "Confidence" SG_ 897 VCFRONT_coolantValveRadBypass 0;
BA_ "GenSigSNA" SG_ 897 VCFRONT_coolantValveRadBypass "127";
BA_ "Confidence" SG_ 897 VCFRONT_usingModeledPs 0;
BA_ "Confidence" SG_ 897 VCFRONT_usingModeledPd 0;
BA_ "Confidence" SG_ 897 VCFRONT_usingModeledPl 0;
BA_ "Confidence" SG_ 897 VCFRONT_usingModeledTs 0;
BA_ "Confidence" SG_ 897 VCFRONT_usingModeledTd 0;
BA_ "Confidence" SG_ 897 VCFRONT_usingModeledTl 0;
BA_ "Confidence" SG_ 897 VCFRONT_hpChargeCableType 0;
BA_ "Confidence" SG_ 897 VCFRONT_subcoolActual 0;
BA_ "Confidence" SG_ 897 VCFRONT_hpSubcoolTarget 0;
BA_ "Confidence" SG_ 897 VCFRONT_CMPDischargeSuperheat 0;
BA_ "Confidence" SG_ 897 VCFRONT_hpCOP 0;
BA_ "Confidence" SG_ 897 VCFRONT_lowSideWattsLift 0;
BA_ "Confidence" SG_ 897 VCFRONT_tempSuperheatActual 0;
BA_ "GenSigSNA" SG_ 897 VCFRONT_tempSuperheatActual "1023";
BA_ "Confidence" SG_ 897 VCFRONT_tempSuperheatTarget 0;
BA_ "Confidence" SG_ 897 VCFRONT_refrigerantHasBeenFilled 0;
BA_ "Confidence" SG_ 897 VCFRONT_refCommissionStatus 0;
BA_ "Confidence" SG_ 897 VCFRONT_LCCPurgeActive 0;
BA_ "Confidence" SG_ 897 VCFRONT_exteriorQuietModeEnabled 0;
BA_ "Confidence" SG_ 897 VCFRONT_exteriorQuietModeAllowed 0;
BA_ "Confidence" SG_ 897 VCFRONT_CCQdotFdFrwrdTarget 0;
BA_ "Confidence" SG_ 897 VCFRONT_CCQdotFdbk 0;
BA_ "Confidence" SG_ 897 VCFRONT_CCQdotActual 0;
BA_ "Confidence" SG_ 897 VCFRONT_evapFdFrwrdTarget 0;
BA_ "Confidence" SG_ 897 VCFRONT_evapFdbk 0;
BA_ "Confidence" SG_ 897 VCFRONT_DIQdotA 0;
BA_ "Confidence" SG_ 897 VCFRONT_evapFdFrwrdTargetMinimum 0;
BA_ "Confidence" SG_ 897 VCFRONT_passiveCoolingState 0;
BA_ "Confidence" SG_ 897 VCFRONT_totalLoadCoolingDominant 0;
BA_ "Confidence" SG_ 897 VCFRONT_feedfwdLoadCoolingDomina 0;
BA_ "SystemSignalLongSymbol" SG_ 897 VCFRONT_feedfwdLoadCoolingDomina "VCFRONT_feedfwdLoadCoolingDominant";
BA_ "Confidence" SG_ 897 VCFRONT_modelLoadCoolingDominant 0;
BA_ "Confidence" SG_ 897 VCFRONT_hpPotentialLowRefrig 0;
BA_ "Confidence" SG_ 897 VCFRONT_hpRefrigerantPurgeState 0;
BA_ "Confidence" SG_ 897 VCFRONT_estPressureLiq 0;
BA_ "Confidence" SG_ 897 VCFRONT_estPressureSuct 0;
BA_ "Confidence" SG_ 897 VCFRONT_estPressureDisch 0;
BA_ "Confidence" SG_ 897 VCFRONT_estTempLiq 0;
BA_ "Confidence" SG_ 897 VCFRONT_estTempSuct 0;
BA_ "Confidence" SG_ 897 VCFRONT_estTempDisch 0;
BA_ "Confidence" SG_ 897 VCFRONT_estCompressorRpm 0;
BA_ "Confidence" SG_ 897 VCFRONT_estQLift 0;
BA_ "Confidence" SG_ 897 VCFRONT_cycleModelConverged 0;
BA_ "Confidence" SG_ 897 VCFRONT_compStandbyCoastDownMode 0;
BA_ "Confidence" SG_ 897 VCFRONT_compStandbyShowroomMode 0;
BA_ "Confidence" SG_ 897 VCFRONT_chillerExvCalibOffset 0;
BA_ "Confidence" SG_ 897 VCFRONT_evapExvCalibOffset 0;
BA_ "Confidence" SG_ 897 VCFRONT_recircExvCalibOffset 0;
BA_ "Confidence" SG_ 897 VCFRONT_lccExvCalibOffset 0;
BA_ "Confidence" SG_ 897 VCFRONT_ccLeftExvCalibOffset 0;
BA_ "Confidence" SG_ 897 VCFRONT_ccRightExvCalibOffset 0;
BA_ "Confidence" SG_ 897 VCFRONT_chillerEXVControlState 0;
BA_ "Confidence" SG_ 897 VCFRONT_evapEXVControlState 0;
BA_ "Confidence" SG_ 897 VCFRONT_recircEXVControlState 0;
BA_ "Confidence" SG_ 897 VCFRONT_lccEXVControlState 0;
BA_ "Confidence" SG_ 897 VCFRONT_cclEXVControlState 0;
BA_ "Confidence" SG_ 897 VCFRONT_ccrEXVControlState 0;
BA_ "Confidence" SG_ 897 VCFRONT_chillerExvCalibFailed 0;
BA_ "Confidence" SG_ 897 VCFRONT_evapExvCalibFailed 0;
BA_ "Confidence" SG_ 897 VCFRONT_recircExvCalibFailed 0;
BA_ "Confidence" SG_ 897 VCFRONT_lccExvCalibFailed 0;
BA_ "Confidence" SG_ 897 VCFRONT_ccLeftExvCalibFailed 0;
BA_ "Confidence" SG_ 897 VCFRONT_ccRightExvCalibFailed 0;
BA_ "Confidence" SG_ 897 VCFRONT_ambientTempSniffActive 0;
BA_ "Confidence" SG_ 897 VCFRONT_ambientTempPassiveSniffi 0;
BA_ "SystemSignalLongSymbol" SG_ 897 VCFRONT_ambientTempPassiveSniffi "VCFRONT_ambientTempPassiveSniffing";
BA_ "Confidence" SG_ 897 VCFRONT_ambientTempRadSampling 0;
BA_ "Confidence" SG_ 897 VCFRONT_ambientTempSpeedSampling 0;
BA_ "Confidence" SG_ 897 VCFRONT_feedFwdMDotEvaporator 0;
BA_ "Confidence" SG_ 897 VCFRONT_hpCabinHeatBatteryHeatAm 0;
BA_ "SystemSignalLongSymbol" SG_ 897 VCFRONT_hpCabinHeatBatteryHeatAm "VCFRONT_hpCabinHeatBatteryHeatAmbSrc";
BA_ "Confidence" SG_ 897 VCFRONT_hpCabinHeatBatteryHeatCO 0;
BA_ "SystemSignalLongSymbol" SG_ 897 VCFRONT_hpCabinHeatBatteryHeatCO "VCFRONT_hpCabinHeatBatteryHeatCOP1";
BA_ "Confidence" SG_ 897 VCFRONT_feedFwdMDotCabinCondense 0;
BA_ "SystemSignalLongSymbol" SG_ 897 VCFRONT_feedFwdMDotCabinCondense "VCFRONT_feedFwdMDotCabinCondenser";
BA_ "Confidence" SG_ 897 VCFRONT_feedBackEvapTempControll 0;
BA_ "SystemSignalLongSymbol" SG_ 897 VCFRONT_feedBackEvapTempControll "VCFRONT_feedBackEvapTempController";
BA_ "Confidence" SG_ 897 VCFRONT_feedBackDuctTempControll 0;
BA_ "SystemSignalLongSymbol" SG_ 897 VCFRONT_feedBackDuctTempControll "VCFRONT_feedBackDuctTempController";
BA_ "Confidence" SG_ 897 VCFRONT_isSolenoidAllowed 0;
BA_ "Confidence" SG_ 897 VCFRONT_maxChillerCoolingPower 0;
BA_ "Confidence" SG_ 897 VCFRONT_fanControlRadCanCool 0;
BA_ "Confidence" SG_ 897 VCFRONT_fanControlFeedfwdActive 0;
BA_ "Confidence" SG_ 897 VCFRONT_fanControlRadiatorUa 0;
BA_ "Confidence" SG_ 897 VCFRONT_fanControlRadiatorInletT 0;
BA_ "SystemSignalLongSymbol" SG_ 897 VCFRONT_fanControlRadiatorInletT "VCFRONT_fanControlRadiatorInletTemp";
BA_ "Confidence" SG_ 897 VCFRONT_hpASBatteryHeatingAllowe 0;
BA_ "SystemSignalLongSymbol" SG_ 897 VCFRONT_hpASBatteryHeatingAllowe "VCFRONT_hpASBatteryHeatingAllowed";
BA_ "Confidence" SG_ 897 VCFRONT_hpCOP1BatteryHeatingAllo 0;
BA_ "SystemSignalLongSymbol" SG_ 897 VCFRONT_hpCOP1BatteryHeatingAllo "VCFRONT_hpCOP1BatteryHeatingAllowed";
BA_ "Confidence" SG_ 897 VCFRONT_hpCabinHeatScavengeOnly 0;
BA_ "Confidence" SG_ 897 VCFRONT_hpCabinHeatAmbientSource 0;
BA_ "Confidence" SG_ 897 VCFRONT_hpCabinHeatReheatScaveng 0;
BA_ "SystemSignalLongSymbol" SG_ 897 VCFRONT_hpCabinHeatReheatScaveng "VCFRONT_hpCabinHeatReheatScavenge";
BA_ "Confidence" SG_ 897 VCFRONT_hpCabinHeatReheatAmbient 0;
BA_ "SystemSignalLongSymbol" SG_ 897 VCFRONT_hpCabinHeatReheatAmbient "VCFRONT_hpCabinHeatReheatAmbientSource";
BA_ "Confidence" SG_ 897 VCFRONT_hpCabinHeatBlend 0;
BA_ "Confidence" SG_ 897 VCFRONT_hpCabinHeatCOP1 0;
BA_ "Confidence" SG_ 897 VCFRONT_hpCabinHeatBatteryHeatRe 0;
BA_ "SystemSignalLongSymbol" SG_ 897 VCFRONT_hpCabinHeatBatteryHeatRe "VCFRONT_hpCabinHeatBatteryHeatReheatAmbSrc";
BA_ "Confidence" SG_ 897 VCFRONT_hpCabinHeatBatteryCoolRe 0;
BA_ "SystemSignalLongSymbol" SG_ 897 VCFRONT_hpCabinHeatBatteryCoolRe "VCFRONT_hpCabinHeatBatteryCoolReheat";
BA_ "Confidence" SG_ 897 VCFRONT_hpCabinCoolEvaporator 0;
BA_ "Confidence" SG_ 897 VCFRONT_hpCabinCoolEvaporatorReh 0;
BA_ "SystemSignalLongSymbol" SG_ 897 VCFRONT_hpCabinCoolEvaporatorReh "VCFRONT_hpCabinCoolEvaporatorReheat";
BA_ "Confidence" SG_ 897 VCFRONT_hpBatteryHeatAmbientSour 0;
BA_ "SystemSignalLongSymbol" SG_ 897 VCFRONT_hpBatteryHeatAmbientSour "VCFRONT_hpBatteryHeatAmbientSource";
BA_ "Confidence" SG_ 897 VCFRONT_hpBatteryHeatCOP1 0;
BA_ "Confidence" SG_ 897 VCFRONT_hpBatteryCool 0;
BA_ "Confidence" SG_ 897 VCFRONT_hpBatteryCoolCabinConden 0;
BA_ "SystemSignalLongSymbol" SG_ 897 VCFRONT_hpBatteryCoolCabinConden "VCFRONT_hpBatteryCoolCabinCondenserCD";
BA_ "Confidence" SG_ 897 VCFRONT_hpBatteryCoolCabinC_0001 0;
BA_ "SystemSignalLongSymbol" SG_ 897 VCFRONT_hpBatteryCoolCabinC_0001 "VCFRONT_hpBatteryCoolCabinCondenserHD";
BA_ "Confidence" SG_ 897 VCFRONT_hpBatteryCoolCabinReheat 0;
BA_ "Confidence" SG_ 897 VCFRONT_hpBatteryCoolEvaporator 0;
BA_ "Confidence" SG_ 897 VCFRONT_suctionSuperheatEstTsSNA 0;
BA_ "Confidence" SG_ 897 VCFRONT_tempRefrigSuctionEst 0;
BA_ "Confidence" SG_ 897 VCFRONT_hpBattOverTempHvacDisabl 0;
BA_ "SystemSignalLongSymbol" SG_ 897 VCFRONT_hpBattOverTempHvacDisabl "VCFRONT_hpBattOverTempHvacDisable";
BA_ "Confidence" SG_ 897 VCFRONT_hpDiagLouverCalib 0;
BA_ "Confidence" SG_ 897 VCFRONT_hpDiagHighSideNotNominal 0;
BA_ "Confidence" SG_ 897 VCFRONT_hpForceModeRadClear 0;
BA_ "Confidence" SG_ 897 VCFRONT_estPressureDischargeSat 0;
BA_ "Confidence" SG_ 897 VCFRONT_tempRefrigLiquid 0;
BA_ "GenSigSNA" SG_ 897 VCFRONT_tempRefrigLiquid "2047";
BA_ "Confidence" SG_ 897 VCFRONT_totalBattHeatingPower 0;
BA_ "Confidence" SG_ 897 VCFRONT_hpPotentialFrozenRadiato 0;
BA_ "SystemSignalLongSymbol" SG_ 897 VCFRONT_hpPotentialFrozenRadiato "VCFRONT_hpPotentialFrozenRadiator";
BA_ "Confidence" SG_ 897 VCFRONT_passiveSeriesRegOn 0;
BA_ "Confidence" SG_ 897 VCFRONT_passiveDemandRadBypass 0;
BA_ "Confidence" SG_ 897 VCFRONT_targetLccActiveCoolCap 0;
BA_ "Confidence" SG_ 897 VCFRONT_targetLccActiveCoolEff 1;
BA_ "Confidence" SG_ 897 VCFRONT_coolantValveDailyAngleTr 1;
BA_ "SystemSignalLongSymbol" SG_ 897 VCFRONT_coolantValveDailyAngleTr "VCFRONT_coolantValveDailyAngleTravel";
BA_ "Confidence" SG_ 897 VCFRONT_dischargePressureLimit 1;
BA_ "Confidence" SG_ 897 VCFRONT_radBypassMoveReason 1;
BA_ "Confidence" SG_ 897 VCFRONT_hpBattHeatingPower 1;
BA_ "Confidence" SG_ 897 VCFRONT_hpColdStagnationLimit 0;
BA_ "Confidence" SG_ 897 VCFRONT_hpHotStagnationLimit 0;
BA_ "Confidence" SG_ 897 VCFRONT_hpCompFlowIndex 0;
BA_ "Confidence" SG_ 897 VCFRONT_hpCompFlowIndexFiltered 0;
BA_ "Confidence" SG_ 897 VCFRONT_subcoolEstTlSNA 0;
BA_ "Confidence" SG_ 897 VCFRONT_subcoolEstPlSNA 0;
BA_ "Confidence" SG_ 897 VCFRONT_tempRefrigLiquidEst 0;
BA_ "Confidence" SG_ 897 VCFRONT_pressureRefrigLiquidEst 0;
BA_ "Confidence" SG_ 897 VCFRONT_cmpIsentropicCheckPassed 0;
BA_ "Confidence" SG_ 897 VCFRONT_louverPosReason 0;
BA_ "Confidence" SG_ 897 VCFRONT_hpEnergyFlowIndex 0;
BA_ "Confidence" SG_ 897 VCFRONT_hpEnergyFlowIndexFiltere 0;
BA_ "SystemSignalLongSymbol" SG_ 897 VCFRONT_hpEnergyFlowIndexFiltere "VCFRONT_hpEnergyFlowIndexFiltered";
BA_ "Confidence" SG_ 897 VCFRONT_ductLeftAtSS 0;
BA_ "Confidence" SG_ 897 VCFRONT_ductRightAtSS 0;
BA_ "Confidence" SG_ 897 VCFRONT_minCompressorRPMAllowed 0;
BA_ "Confidence" SG_ 897 VCFRONT_ccRefrigerantMassFlow 0;
BA_ "Confidence" SG_ 897 VCFRONT_highSideDpResidual 0;
BA_ "Confidence" SG_ 897 VCFRONT_abnormalHighSuctionSuper 0;
BA_ "SystemSignalLongSymbol" SG_ 897 VCFRONT_abnormalHighSuctionSuper "VCFRONT_abnormalHighSuctionSuperheat";
BA_ "Confidence" SG_ 897 VCFRONT_coolantValveAngleTravel 0;
BA_ "Confidence" SG_ 897 VCFRONT_chargeShuttleType 0;
BA_ "Confidence" SG_ 897 VCFRONT_hpRefrigTempSensorCheckC 0;
BA_ "SystemSignalLongSymbol" SG_ 897 VCFRONT_hpRefrigTempSensorCheckC "VCFRONT_hpRefrigTempSensorCheckCanFire";
BA_ "Confidence" SG_ 897 VCFRONT_hpRefrigPressureSensorCh 0;
BA_ "SystemSignalLongSymbol" SG_ 897 VCFRONT_hpRefrigPressureSensorCh "VCFRONT_hpRefrigPressureSensorCheckCanFire";
BA_ "Confidence" SG_ 897 VCFRONT_tempSuperheatActFiltered 1;
BA_ "Confidence" SG_ 897 VCFRONT_tempRefrigDischarge 1;
BA_ "GenSigSNA" SG_ 897 VCFRONT_tempRefrigDischarge "2047";
BA_ "Confidence" SG_ 897 VCFRONT_pumpBatteryRPMTarget 1;
BA_ "GenSigSNA" SG_ 897 VCFRONT_pumpBatteryRPMTarget "255";
BA_ "Confidence" SG_ 897 VCFRONT_pumpPowertrainRPMTarget 1;
BA_ "GenSigSNA" SG_ 897 VCFRONT_pumpPowertrainRPMTarget "255";
BA_ "Confidence" SG_ 897 VCFRONT_coolantFlowChillerTarget 1;
BA_ "Confidence" SG_ 897 VCFRONT_radiatorFanRPMTarget 1;
BA_ "GenSigSNA" SG_ 897 VCFRONT_radiatorFanRPMTarget "255";
BA_ "Confidence" SG_ 897 VCFRONT_preventReEntryTillNexthp 0;
BA_ "SystemSignalLongSymbol" SG_ 897 VCFRONT_preventReEntryTillNexthp "VCFRONT_preventReEntryTillNexthpResetCOP1";
BA_ "Confidence" SG_ 897 VCFRONT_chillerBattHeatingPowerA 0;
BA_ "SystemSignalLongSymbol" SG_ 897 VCFRONT_chillerBattHeatingPowerA "VCFRONT_chillerBattHeatingPowerAvailable";
BA_ "Confidence" SG_ 897 VCFRONT_isExpectedQChillerVeryHi 0;
BA_ "SystemSignalLongSymbol" SG_ 897 VCFRONT_isExpectedQChillerVeryHi "VCFRONT_isExpectedQChillerVeryHighCOP1";
BA_ "Confidence" SG_ 897 VCFRONT_superheatProtectionLimit 0;
BA_ "Confidence" SG_ 897 VCFRONT_chillerDemandWatts 0;
BA_ "Confidence" SG_ 897 VCFRONT_nominalTevapHWLimit 0;
BA_ "Confidence" SG_ 897 VCFRONT_ambientTempState 1;
BA_ "Confidence" SG_ 897 VCFRONT_ambientTempUnlatchReason 1;
BA_ "Confidence" SG_ 897 VCFRONT_compressorSuctionVaporQu 1;
BA_ "SystemSignalLongSymbol" SG_ 897 VCFRONT_compressorSuctionVaporQu "VCFRONT_compressorSuctionVaporQuality";
BA_ "Confidence" SG_ 897 VCFRONT_cabinHeatingCOP1MinActiv 1;
BA_ "SystemSignalLongSymbol" SG_ 897 VCFRONT_cabinHeatingCOP1MinActiv "VCFRONT_cabinHeatingCOP1MinActiveRefCharge";
BA_ "Confidence" SG_ 513 VCFRONT_loggingAndVitals10HzInde 1;
BA_ "SystemSignalLongSymbol" SG_ 513 VCFRONT_loggingAndVitals10HzInde "VCFRONT_loggingAndVitals10HzIndex";
BA_ "Confidence" SG_ 513 VCFRONT_pumpBatteryRPMActual 1;
BA_ "GenSigSNA" SG_ 513 VCFRONT_pumpBatteryRPMActual "255";
BA_ "Confidence" SG_ 513 VCFRONT_pumpPowertrainRPMActual 1;
BA_ "GenSigSNA" SG_ 513 VCFRONT_pumpPowertrainRPMActual "255";
BA_ "Confidence" SG_ 513 VCFRONT_radiatorFanRPMActual 1;
BA_ "GenSigSNA" SG_ 513 VCFRONT_radiatorFanRPMActual "255";
BA_ "Confidence" SG_ 513 VCFRONT_exvFlowTarget 1;
BA_ "Confidence" SG_ 513 VCFRONT_activeLouverOpenPosTarg 1;
BA_ "Confidence" SG_ 513 VCFRONT_pressureRefrigLiquid 1;
BA_ "GenSigSNA" SG_ 513 VCFRONT_pressureRefrigLiquid "511";
BA_ "Confidence" SG_ 513 VCFRONT_fanDemand 0;
BA_ "Confidence" SG_ 513 VCFRONT_compressorState 0;
BA_ "Confidence" SG_ 513 VCFRONT_compDemandEvap 0;
BA_ "Confidence" SG_ 513 VCFRONT_exvState 0;
BA_ "Confidence" SG_ 513 VCFRONT_solenoidEvapState 0;
BA_ "Confidence" SG_ 513 VCFRONT_compDemandChiller 0;
BA_ "Confidence" SG_ 513 VCFRONT_coolantValveMode 0;
BA_ "Confidence" SG_ 513 VCFRONT_compFaultSeverity 0;
BA_ "Confidence" SG_ 513 VCFRONT_solenoidEngaged 0;
BA_ "Confidence" SG_ 513 VCFRONT_hpHighSideHX 0;
BA_ "Confidence" SG_ 513 VCFRONT_hpLowSideHX 0;
BA_ "Confidence" SG_ 513 VCFRONT_hpDominantLoad 0;
BA_ "Confidence" SG_ 513 VCFRONT_hpBlendType 0;
BA_ "Confidence" SG_ 513 VCFRONT_hpQuietModeEnabled 0;
BA_ "Confidence" SG_ 513 VCFRONT_hpCabinLoadType 0;
BA_ "Confidence" SG_ 513 VCFRONT_hpBatteryLoadType 0;
BA_ "Confidence" SG_ 513 VCFRONT_hpReqCoolantMode 0;
BA_ "Confidence" SG_ 513 VCFRONT_hpReqTransScavenge 0;
BA_ "Confidence" SG_ 513 VCFRONT_compLiqPumpOutState 0;
BA_ "Confidence" SG_ 513 VCFRONT_frunkStateDBG 0;
BA_ "Confidence" SG_ 513 VCFRONT_frunkSwitchGroupState 0;
BA_ "Confidence" SG_ 513 VCFRONT_chillerExvFlow 0;
BA_ "Confidence" SG_ 513 VCFRONT_evapExvFlow 0;
BA_ "Confidence" SG_ 513 VCFRONT_recircExvFlow 0;
BA_ "Confidence" SG_ 513 VCFRONT_lccExvFlow 0;
BA_ "Confidence" SG_ 513 VCFRONT_cclExvFlow 0;
BA_ "Confidence" SG_ 513 VCFRONT_ccrExvFlow 0;
BA_ "Confidence" SG_ 513 VCFRONT_chillerExvState 0;
BA_ "Confidence" SG_ 513 VCFRONT_evapExvState 0;
BA_ "Confidence" SG_ 513 VCFRONT_recircExvState 0;
BA_ "Confidence" SG_ 513 VCFRONT_chillerExvFlowTarget 0;
BA_ "Confidence" SG_ 513 VCFRONT_evapExvFlowTarget 0;
BA_ "Confidence" SG_ 513 VCFRONT_recircExvFlowTarget 0;
BA_ "Confidence" SG_ 513 VCFRONT_lccExvFlowTarget 0;
BA_ "Confidence" SG_ 513 VCFRONT_cclExvFlowTarget 0;
BA_ "Confidence" SG_ 513 VCFRONT_ccrExvFlowTarget 0;
BA_ "Confidence" SG_ 513 VCFRONT_lccExvState 0;
BA_ "Confidence" SG_ 513 VCFRONT_cclExvState 0;
BA_ "Confidence" SG_ 513 VCFRONT_ccrExvState 0;
BA_ "Confidence" SG_ 737 VCFRONT_statusIndex 1;
BA_ "Confidence" SG_ 737 VCFRONT_homelinkCommStatus 1;
BA_ "GenSigSNA" SG_ 737 VCFRONT_homelinkCommStatus "0";
BA_ "Confidence" SG_ 929 VCFRONT_vehicleStatusMuxIndex 1;
BA_ "Confidence" SG_ 929 VCFRONT_vehicleStatusCounter 0;
BA_ "Confidence" SG_ 929 VCFRONT_vehicleStatusChecksum 0;
BA_ "Confidence" SG_ 929 VCFRONT_preconditionRequest 0;
BA_ "Confidence" SG_ 929 VCFRONT_APGlassHeaterState 0;
BA_ "GenSigSNA" SG_ 929 VCFRONT_APGlassHeaterState "0";
BA_ "Confidence" SG_ 929 VCFRONT_thermalSystemType 0;
BA_ "GenSigSNA" SG_ 929 VCFRONT_thermalSystemType "1";
BA_ "Confidence" SG_ 929 VCFRONT_standbySupplySupported 0;
BA_ "Confidence" SG_ 929 VCFRONT_driverPresent 0;
BA_ "Confidence" SG_ 929 VCFRONT_passengerPresent 0;
BA_ "Confidence" SG_ 929 VCFRONT_accPlusAvailable 0;
BA_ "Confidence" SG_ 929 VCFRONT_diPowerOnState 0;
BA_ "Confidence" SG_ 929 VCFRONT_12vStatusForDrive 0;
BA_ "Confidence" SG_ 929 VCFRONT_dcr12VMilliOhms 0;
BA_ "Confidence" SG_ 929 VC_userPresenceState 0;
BA_ "Confidence" SG_ 929 VCFRONT_factoryLimitsOverrideOk 0;
BA_ "Confidence" SG_ 929 VCFRONT_ota12VSupportRequest 0;
BA_ "Confidence" SG_ 929 VCFRONT_driverBuckleStatus 0;
BA_ "Confidence" SG_ 929 VCFRONT_driverDoorStatus 0;
BA_ "Confidence" SG_ 929 VCFRONT_driverUnbuckled 0;
BA_ "GenSigSNA" SG_ 929 VCFRONT_driverUnbuckled "2";
BA_ "Confidence" SG_ 929 VCFRONT_passengerUnbuckled 0;
BA_ "GenSigSNA" SG_ 929 VCFRONT_passengerUnbuckled "2";
BA_ "Confidence" SG_ 929 VCFRONT_2RowLeftUnbuckled 0;
BA_ "GenSigSNA" SG_ 929 VCFRONT_2RowLeftUnbuckled "2";
BA_ "Confidence" SG_ 929 VCFRONT_2RowCenterUnbuckled 0;
BA_ "GenSigSNA" SG_ 929 VCFRONT_2RowCenterUnbuckled "2";
BA_ "Confidence" SG_ 929 VCFRONT_2RowRightUnbuckled 0;
BA_ "GenSigSNA" SG_ 929 VCFRONT_2RowRightUnbuckled "2";
BA_ "Confidence" SG_ 929 VCFRONT_pcsEFuseVoltage 0;
BA_ "GenSigSNA" SG_ 929 VCFRONT_pcsEFuseVoltage "1023";
BA_ "Confidence" SG_ 929 VCFRONT_bmsHvChargeEnable 0;
BA_ "Confidence" SG_ 929 VCFRONT_3RowLeftUnbuckled 0;
BA_ "GenSigSNA" SG_ 929 VCFRONT_3RowLeftUnbuckled "2";
BA_ "Confidence" SG_ 929 VCFRONT_3RowRightUnbuckled 0;
BA_ "GenSigSNA" SG_ 929 VCFRONT_3RowRightUnbuckled "2";
BA_ "Confidence" SG_ 929 VCFRONT_maxBattHeatRejection 0;
BA_ "Confidence" SG_ 929 VCFRONT_hvacReqBattCoolOutTemp 0;
BA_ "Confidence" SG_ 929 VCFRONT_PCSCurrent 0;
BA_ "Confidence" SG_ 929 VCFRONT_refSystemNominal 0;
BA_ "Confidence" SG_ 929 VCFRONT_driverEnteredCabinEstima 0;
BA_ "SystemSignalLongSymbol" SG_ 929 VCFRONT_driverEnteredCabinEstima "VCFRONT_driverEnteredCabinEstimateDBG";
BA_ "Confidence" SG_ 929 VCFRONT_anySWEFuseActive 0;
BA_ "Confidence" SG_ 929 VCFRONT_hpBattHeatingPowerTrgt 0;
BA_ "Confidence" SG_ 258 VCLEFT_doorClosureStatusFront 0;
BA_ "GenSigSNA" SG_ 258 VCLEFT_doorClosureStatusFront "0";
BA_ "Confidence" SG_ 258 VCLEFT_doorClosureStatusRear 0;
BA_ "GenSigSNA" SG_ 258 VCLEFT_doorClosureStatusRear "0";
BA_ "Confidence" SG_ 258 VCLEFT_frontLatchSwitch 0;
BA_ "Confidence" SG_ 258 VCLEFT_rearLatchSwitch 0;
BA_ "Confidence" SG_ 258 VCLEFT_frontHandlePulled 0;
BA_ "Confidence" SG_ 258 VCLEFT_rearHandlePulled 0;
BA_ "Confidence" SG_ 258 VCLEFT_frontRelActuatorSwitch 0;
BA_ "Confidence" SG_ 258 VCLEFT_rearRelActuatorSwitch 0;
BA_ "Confidence" SG_ 258 VCLEFT_frontLatchStatus 0;
BA_ "GenSigSNA" SG_ 258 VCLEFT_frontLatchStatus "0";
BA_ "Confidence" SG_ 258 VCLEFT_rearLatchStatus 0;
BA_ "GenSigSNA" SG_ 258 VCLEFT_rearLatchStatus "0";
BA_ "Confidence" SG_ 258 VCLEFT_lastDoorReqSourceFront 0;
BA_ "Confidence" SG_ 258 VCLEFT_lastDoorReqSourceRear 0;
BA_ "Confidence" SG_ 258 VCLEFT_frontIntSwitchPressed 0;
BA_ "Confidence" SG_ 258 VCLEFT_rearIntSwitchPressed 0;
BA_ "Confidence" SG_ 258 VCLEFT_mirrorTiltXPosition 0;
BA_ "Confidence" SG_ 258 VCLEFT_mirrorTiltYPosition 0;
BA_ "Confidence" SG_ 258 VCLEFT_mirrorState 0;
BA_ "Confidence" SG_ 258 VCLEFT_mirrorFoldState 0;
BA_ "Confidence" SG_ 258 VCLEFT_mirrorRecallState 0;
BA_ "Confidence" SG_ 258 VCLEFT_mirrorHeatState 0;
BA_ "GenSigSNA" SG_ 258 VCLEFT_mirrorHeatState "0";
BA_ "Confidence" SG_ 258 VCLEFT_rearHandlePulledPersist 0;
BA_ "Confidence" SG_ 258 VCLEFT_frontHandlePulledPersist 0;
BA_ "Confidence" SG_ 258 VCLEFT_mirrorDipped 0;
BA_ "Confidence" SG_ 626 VCLEFT_epbmDebugIndex 1;
BA_ "Confidence" SG_ 626 VCLEFT_epbmCaliperState 0;
BA_ "Confidence" SG_ 626 VCLEFT_epbmMotorEnabled 0;
BA_ "Confidence" SG_ 626 VCLEFT_epbMotorCurrent 0;
BA_ "Confidence" SG_ 626 VCLEFT_epbmApplyVoltage 0;
BA_ "Confidence" SG_ 626 VCLEFT_epbmReleaseVoltage 0;
BA_ "Confidence" SG_ 626 VCLEFT_summonFaultReason 1;
BA_ "Confidence" SG_ 626 VCLEFT_epbSummonState 1;
BA_ "Confidence" SG_ 626 VCLEFT_epbmSummonState 1;
BA_ "Confidence" SG_ 626 VCLEFT_epbUnitStatus 1;
BA_ "Confidence" SG_ 626 VCLEFT_epbmFaultStatus 1;
BA_ "Confidence" SG_ 626 VCLEFT_epbFaultStatus 1;
BA_ "Confidence" SG_ 626 VCLEFT_epbmSystemStatus 1;
BA_ "Confidence" SG_ 1140 VCLEFT_cdpRequestState 0;
BA_ "Confidence" SG_ 1140 VCLEFT_epbmSystemStatusQF 0;
BA_ "Confidence" SG_ 1140 VCLEFT_epbmUnitStatus 0;
BA_ "Confidence" SG_ 1140 VCLEFT_epbmCdpState 0;
BA_ "Confidence" SG_ 1140 VCLEFT_epbmStatusCounter 0;
BA_ "Confidence" SG_ 1140 VCLEFT_epbmStatusChecksum 0;
BA_ "Confidence" SG_ 770 VCLEFT_infoIndex 1;
BA_ "Confidence" SG_ 770 VCLEFT_infoBuildType 0;
BA_ "Confidence" SG_ 770 VCLEFT_infoBuildConfigId 0;
BA_ "Confidence" SG_ 770 VCLEFT_infoHardwareId 0;
BA_ "Confidence" SG_ 770 VCLEFT_infoComponentId 0;
BA_ "Confidence" SG_ 770 VCLEFT_infoPcbaId 0;
BA_ "Confidence" SG_ 770 VCLEFT_infoAssemblyId 0;
BA_ "GenSigSNA" SG_ 770 VCLEFT_infoAssemblyId "255";
BA_ "Confidence" SG_ 770 VCLEFT_infoUsageId 0;
BA_ "Confidence" SG_ 770 VCLEFT_infoSubUsageId 0;
BA_ "Confidence" SG_ 770 VCLEFT_infoAppCrc 0;
BA_ "Confidence" SG_ 770 VCLEFT_infoAppGitHash 0;
BA_ "Confidence" SG_ 770 VCLEFT_infoBootGitHash 0;
BA_ "Confidence" SG_ 770 VCLEFT_infoPlatformType 0;
BA_ "Confidence" SG_ 770 VCLEFT_infoBootUdsProtoVersion 0;
BA_ "Confidence" SG_ 770 VCLEFT_infoBootCrc 0;
VAL_ 628 UI_lightFlashRequest 3 "LIGHT_FLASH_SENTRY" 2 "LIGHT_FLASH_MOBILE_APP" 1 "LIGHT_FLASH_HOMELINK" 0 "LIGHT_FLASH_INACTIVE" ;
VAL_ 628 UI_steeringWheelHeatLevelReq 3 "STEERING_WHEEL_HEAT_LEVEL3" 2 "STEERING_WHEEL_HEAT_LEVEL2" 1 "STEERING_WHEEL_HEAT_LEVEL1" 0 "STEERING_WHEEL_HEAT_OFF" ;
VAL_ 628 UI_leftRearSeatAdjustmentRequest 6 "UI_ADJUSTABLE_FOLD_FLAT_REQUEST_STOP" 5 "UI_ADJUSTABLE_FOLD_FLAT_REQUEST_TOGGLE_FOLD" 4 "UI_ADJUSTABLE_FOLD_FLAT_REQUEST_REARWARD_FAST" 3 "UI_ADJUSTABLE_FOLD_FLAT_REQUEST_REARWARD_COMFORT" 2 "UI_ADJUSTABLE_FOLD_FLAT_REQUEST_FORWARD_FAST" 1 "UI_ADJUSTABLE_FOLD_FLAT_REQUEST_FORWARD_COMFORT" 0 "UI_ADJUSTABLE_FOLD_FLAT_REQUEST_NONE" ;
VAL_ 628 UI_rightRearSeatAdjustmentReques 6 "UI_ADJUSTABLE_FOLD_FLAT_REQUEST_STOP" 5 "UI_ADJUSTABLE_FOLD_FLAT_REQUEST_TOGGLE_FOLD" 4 "UI_ADJUSTABLE_FOLD_FLAT_REQUEST_REARWARD_FAST" 3 "UI_ADJUSTABLE_FOLD_FLAT_REQUEST_REARWARD_COMFORT" 2 "UI_ADJUSTABLE_FOLD_FLAT_REQUEST_FORWARD_FAST" 1 "UI_ADJUSTABLE_FOLD_FLAT_REQUEST_FORWARD_COMFORT" 0 "UI_ADJUSTABLE_FOLD_FLAT_REQUEST_NONE" ;
VAL_ 628 UI_rearSeatChildLock 3 "UI_ADJUSTABLE_FOLD_FLAT_CHILD_LOCK_BOTH" 2 "UI_ADJUSTABLE_FOLD_FLAT_CHILD_LOCK_RIGHT" 1 "UI_ADJUSTABLE_FOLD_FLAT_CHILD_LOCK_LEFT" 0 "UI_ADJUSTABLE_FOLD_FLAT_CHILD_LOCK_NONE" ;
VAL_ 628 UI_windowRequest 6 "WINDOW_REQUEST_GOTO_RELATIVE_PERCENT" 5 "WINDOW_REQUEST_GOTO_CLOSED_CARWASH" 4 "WINDOW_REQUEST_GOTO_OPEN" 3 "WINDOW_REQUEST_GOTO_CLOSED" 2 "WINDOW_REQUEST_GOTO_VENT" 1 "WINDOW_REQUEST_GOTO_PERCENT" 0 "WINDOW_REQUEST_IDLE" ;
VAL_ 644 UI_transportMode 1 "TRANSPORT_MODE_ENABLED" 0 "TRANSPORT_MODE_DISABLED" ;
VAL_ 644 UI_showroomMode 1 "SHOWROOM_MODE_ENABLED" 0 "SHOWROOM_MODE_DISABLED" ;
VAL_ 644 UI_serviceMode 1 "SERVICE_MODE_ENABLED" 0 "SERVICE_MODE_DISABLED" ;
VAL_ 644 UI_serviceModePlus 1 "SERVICE_MODE_PLUS_ENABLED" 0 "SERVICE_MODE_PLUS_DISABLED" ;
VAL_ 644 UI_lightShowType 5 "LIGHT_SHOW_TYPE_STANDARD_CNY24" 4 "LIGHT_SHOW_TYPE_STANDARD_THE_ARRIVAL" 3 "LIGHT_SHOW_TYPE_STANDARD_CNY23" 2 "LIGHT_SHOW_TYPE_STANDARD_AULD_LANG_SYNE" 1 "LIGHT_SHOW_TYPE_STANDARD_CAROL_OF_THE_BELLS" 0 "LIGHT_SHOW_TYPE_CUSTOM_USB" ;
VAL_ 595 UI_ventPanelControlRequestIndex 1 "1" 0 "0" ;
VAL_ 595 UI_ventPanelLeftLateralMode 2 "SWING" 1 "SPLIT" 0 "SINGLE" ;
VAL_ 595 UI_ventPanelRightLateralMode 2 "SWING" 1 "SPLIT" 0 "SINGLE" ;
VAL_ 595 UI_hvacReqActiveVents 3 "OFF" 2 "RIGHT" 1 "LEFT" 0 "BOTH" ;
VAL_ 609 VCFRONT_12VBatteryStatusIndex 5 "Mux5" 4 "Mux4" 3 "Mux3" 2 "Mux2" 1 "Mux1" 0 "Mux0" ;
VAL_ 609 VCFRONT_batterySMState 10 "BATTERY_SM_STATE_EXTERNAL_LV_BUS_CONTROL" 9 "BATTERY_SM_STATE_RECOVERY" 8 "BATTERY_SM_STATE_FAULT" 7 "BATTERY_SM_STATE_SHORTED_CELL_TEST" 6 "BATTERY_SM_STATE_DISCONNECTED_BATTERY_TEST" 5 "BATTERY_SM_STATE_OTA_STANDBY" 4 "BATTERY_SM_STATE_RESISTANCE_ESTIMATION" 3 "BATTERY_SM_STATE_STANDBY" 2 "BATTERY_SM_STATE_DISCHARGE" 1 "BATTERY_SM_STATE_CHARGE" 0 "BATTERY_SM_STATE_INIT" ;
VAL_ 609 VCFRONT_eFuseRecoveryStateDBG 4 "VC_LVBMB_EFUSE_RECOVERY_STATE_BLOCKED" 3 "VC_LVBMB_EFUSE_RECOVERY_STATE_FINISH" 2 "VC_LVBMB_EFUSE_RECOVERY_STATE_CONNECT" 1 "VC_LVBMB_EFUSE_RECOVERY_STATE_SETUP" 0 "VC_LVBMB_EFUSE_RECOVERY_STATE_INACTIVE" ;
VAL_ 609 VCFRONT_batteryLINScheduleDBG 7 "VC_LVBMS_LIN_SCHEDULE_SNA" 6 "VC_LVBMS_LIN_SCHEDULE_OTHER" 4 "VC_LVBMS_LIN_SCHEDULE_DEFAULT_2" 3 "VC_LVBMS_LIN_SCHEDULE_DEFAULT_1" 2 "VC_LVBMS_LIN_SCHEDULE_DIAGNOSTIC" 1 "VC_LVBMS_LIN_SCHEDULE_RESET" 0 "VC_LVBMS_LIN_SCHEDULE_OFF" ;
VAL_ 609 VCFRONT_IBSVoltage 4095 "SNA" ;
VAL_ 609 VCFRONT_IBSTemperature 2047 "IBS_TEMPERATURE_SNA" ;
VAL_ 609 VCFRONT_LVBatteryStatusForDrive 2 "LV_BATTERY_EXIT_DRIVE_REQUESTED" 1 "LV_BATTERY_READY_FOR_DRIVE" 0 "LV_BATTERY_NOT_READY_FOR_DRIVE" ;
VAL_ 609 VCFRONT_LVBatteryType 5 "LV_BATTERY_TYPE_TESLA_48V_LI_ION" 4 "LV_BATTERY_TYPE_TESLA_16V_LI_ION" 3 "LV_BATTERY_TYPE_CATL_LI_ION" 2 "LV_BATTERY_TYPE_CLARIOS_B24_FLOODED" 1 "LV_BATTERY_TYPE_ATLASBX_B24_FLOODED" 0 "LV_BATTERY_TYPE_UNKNOWN" ;
VAL_ 609 VCFRONT_IBSVoltageFiltered 16383 "SNA" 16382 "MAX" 16381 "MIN" ;
VAL_ 609 VCFRONT_LVBMS_LVBusVoltageSource 3 "VC_LVBMS_VOLTAGE_SOURCE_LVBMS" 2 "VC_LVBMS_VOLTAGE_SOURCE_VBAT_MONITOR" 1 "VC_LVBMS_VOLTAGE_SOURCE_IBS" 0 "VC_LVBMS_VOLTAGE_SOURCE_NONE" ;
VAL_ 609 VCFRONT_LVBMS_LVPackCurrentSourc 2 "VC_LV_PACK_CURRENT_SOURCE_LVBMS" 1 "VC_LV_PACK_CURRENT_SOURCE_IBS" 0 "VC_LV_PACK_CURRENT_SOURCE_NONE" ;
VAL_ 609 VCFRONT_LVBatterySupportRqrdTrig 14336 "LV_BATTERY_SUPPORT_REQUIRED_TRIGGER_SOC_IMBALANCE_AND_CORRECTION" 12288 "LV_BATTERY_SUPPORT_REQUIRED_TRIGGER_IMBALANCE_AND_CORRECTION" 10240 "LV_BATTERY_SUPPORT_REQUIRED_TRIGGER_SOC_AND_CORRECTION" 8192 "LV_BATTERY_SUPPORT_REQUIRED_TRIGGER_CORRECTION" 6144 "LV_BATTERY_SUPPORT_REQUIRED_TRIGGER_SOC_AND_IMBALANCE" 4096 "LV_BATTERY_SUPPORT_REQUIRED_TRIGGER_IMBALANCE" 2048 "LV_BATTERY_SUPPORT_REQUIRED_TRIGGER_SOC" 1024 "LV_BATTERY_SUPPORT_REQUIRED_TRIGGER_POST_OTA" 512 "LV_BATTERY_SUPPORT_REQUIRED_TRIGGER_EXIT_TRANSPORT_MODE" 256 "LV_BATTERY_SUPPORT_REQUIRED_TRIGGER_POWER_ON_RESET" 128 "LV_BATTERY_SUPPORT_REQUIRED_TRIGGER_PERIODIC_CHARGE" 64 "LV_BATTERY_SUPPORT_REQUIRED_TRIGGER_AH_COUNT" 32 "LV_BATTERY_SUPPORT_REQUIRED_TRIGGER_UNKNOWN_VOLTAGE" 20 "LV_BATTERY_SUPPORT_REQUIRED_TRIGGER_RAW_VC_VOLTAGES" 16 "LV_BATTERY_SUPPORT_REQUIRED_TRIGGER_VBAT_RAW_VOLTAGE" 12 "LV_BATTERY_SUPPORT_REQUIRED_TRIGGER_RAW_BATTERY_VOLTAGES" 10 "LV_BATTERY_SUPPORT_REQUIRED_TRIGGER_PACK_VOLTAGES" 8 "LV_BATTERY_SUPPORT_REQUIRED_TRIGGER_PACK_RAW_VOLTAGE" 5 "LV_BATTERY_SUPPORT_REQUIRED_TRIGGER_IBS_VOLTAGES" 4 "LV_BATTERY_SUPPORT_REQUIRED_TRIGGER_IBS_RAW_VOLTAGE" 3 "LV_BATTERY_SUPPORT_REQUIRED_TRIGGER_FILTERED_VOLTAGES" 2 "LV_BATTERY_SUPPORT_REQUIRED_TRIGGER_PACK_FILTERED_VOLTAGE" 1 "LV_BATTERY_SUPPORT_REQUIRED_TRIGGER_IBS_FILTERED_VOLTAGE" 0 "LV_BATTERY_SUPPORT_REQUIRED_TRIGGER_NONE" ;
VAL_ 609 VCFRONT_voltageProfile 3 "VOLTAGE_PROFILE_ALWAYS_CLOSED_CONTACTORS" 2 "VOLTAGE_PROFILE_REDUCED_FLOAT" 1 "VOLTAGE_PROFILE_FLOAT" 0 "VOLTAGE_PROFILE_CHARGE" ;
VAL_ 609 VCFRONT_IBSVoltageRawDBG 16383 "SNA" 16382 "MAX" 16381 "MIN" ;
VAL_ 2017 VCFRONT_LVHealthStatus 3 "BACKUP_COMPROMISED" 2 "LATENT_FAULT" 1 "HEALTHY_LIMITED" 0 "DOMAIN_HEALTHY" ;
VAL_ 2017 VCFRONT_LVStatusForDrive 6 "STATUS_FOR_DRIVE_ACTIVE_DECEL" 5 "STATUS_FOR_DRIVE_PULL_TO_SHOULDER" 4 "STATUS_FOR_DRIVE_LIMP" 3 "STATUS_FOR_DRIVE_RETURN_TO_SERVICE" 2 "STATUS_FOR_DRIVE_READY_LIMITED" 1 "STATUS_FOR_DRIVE_READY" 0 "STATUS_FOR_DRIVE_NOT_READY" ;
VAL_ 2017 VCFRONT_LVPowerSecondsToSafeHarb 65535 "INDEFINITE" ;
VAL_ 2016 VCFRONT_LVHealthDebugIndex 1 "FRONT_CHECK_RESULTS_1" 0 "UNHEALTHY_REASONS" ;
VAL_ 545 VCFRONT_LVPowerStateIndex 1 "Mux1" 0 "Mux0" ;
VAL_ 545 VCFRONT_vehiclePowerState 3 "VEHICLE_POWER_STATE_DRIVE" 2 "VEHICLE_POWER_STATE_ACCESSORY" 1 "VEHICLE_POWER_STATE_CONDITIONING" 0 "VEHICLE_POWER_STATE_OFF" ;
VAL_ 545 VCFRONT_cpLVRequest 3 "LV_FAULT" 2 "LV_GOING_DOWN" 1 "LV_ON" 0 "LV_OFF" ;
VAL_ 545 VCFRONT_epasLVState 3 "LV_FAULT" 2 "LV_GOING_DOWN" 1 "LV_ON" 0 "LV_OFF" ;
VAL_ 545 VCFRONT_hvcLVRequest 3 "LV_FAULT" 2 "LV_GOING_DOWN" 1 "LV_ON" 0 "LV_OFF" ;
VAL_ 545 VCFRONT_tasLVState 3 "LV_FAULT" 2 "LV_GOING_DOWN" 1 "LV_ON" 0 "LV_OFF" ;
VAL_ 545 VCFRONT_pcsLVState 3 "LV_FAULT" 2 "LV_GOING_DOWN" 1 "LV_ON" 0 "LV_OFF" ;
VAL_ 545 VCFRONT_CMPDLVState 3 "LV_FAULT" 2 "LV_GOING_DOWN" 1 "LV_ON" 0 "LV_OFF" ;
VAL_ 545 VCFRONT_hcmlLVState 3 "LV_FAULT" 2 "LV_GOING_DOWN" 1 "LV_ON" 0 "LV_OFF" ;
VAL_ 545 VCFRONT_hcmrLVState 3 "LV_FAULT" 2 "LV_GOING_DOWN" 1 "LV_ON" 0 "LV_OFF" ;
VAL_ 545 VCFRONT_MCUAudioLVState 3 "LV_FAULT" 2 "LV_GOING_DOWN" 1 "LV_ON" 0 "LV_OFF" ;
VAL_ 545 VCFRONT_espValveLVState 3 "LV_FAULT" 2 "LV_GOING_DOWN" 1 "LV_ON" 0 "LV_OFF" ;
VAL_ 545 VCFRONT_MCUGraphicsLVState 3 "LV_FAULT" 2 "LV_GOING_DOWN" 1 "LV_ON" 0 "LV_OFF" ;
VAL_ 545 VC_hvStateRequest 7 "VC_HV_REQUEST_STATE_RESERVED" 2 "VC_HV_REQUEST_STATE_HV_UP" 1 "VC_HV_REQUEST_STATE_LV_SUPPORT_ONLY" 0 "VC_HV_REQUEST_STATE_NONE" ;
VAL_ 545 VC_persistAccPortPowerState 4 "STATE_KEEP_AWAKE_OVERRIDDEN_NOTIFY_USER" 3 "STATE_KEEP_AWAKE_ALLOW_SLEEP" 2 "STATE_KEEP_AWAKE_ACTIVE" 1 "STATE_KEEP_AWAKE_ARMED" 0 "STATE_KEEP_AWAKE_DISARMED" ;
VAL_ 753 VCFRONT_eFuseDebugStatusIndex 19 "INVALID" 18 "MCU_MISC" 17 "LV_BATTERY_DEBUG" 16 "MISC_RAILS" 15 "RAILS_A_B" 14 "PUMPS" 13 "VBAT_FUSED_HIGH_CURRENT" 12 "HEADLAMPS" 11 "MCU_LOGIC" 10 "SLEEP_BYPASS" 9 "AUTOPILOT_2" 8 "AUTOPILOT_1" 7 "ESP_VALVE" 6 "ESP_MOTOR" 5 "EPAS3S" 4 "EPAS3P" 3 "IBOOSTER" 2 "PCS" 1 "VCLEFT" 0 "VCRIGHT" ;
VAL_ 753 VCFRONT_leftControllerState 3 "EFUSE_STATE_SNA" 2 "EFUSE_STATE_LOCKED_OUT" 1 "EFUSE_STATE_ON" 0 "EFUSE_STATE_OFF" ;
VAL_ 753 VCFRONT_vcleftSelfTestResult 12 "EFUSE_SELF_TEST_EFUSE_RESULT_SNA" 11 "EFUSE_SELF_TEST_EFUSE_RESULT_SKIPPED" 10 "EFUSE_SELF_TEST_EFUSE_RESULT_FAILED_NOT_LATCHED" 9 "EFUSE_SELF_TEST_EFUSE_RESULT_FAILED_TURN_OFF_PATH_TOO_SLOW" 8 "EFUSE_SELF_TEST_EFUSE_RESULT_FAILED_ENABLE_HIGH_MALFUNCTION" 7 "EFUSE_SELF_TEST_EFUSE_RESULT_FAILED_POWER_FET_CHANNEL_OPEN" 6 "EFUSE_SELF_TEST_EFUSE_RESULT_FAILED_ENABLE_LOW_MALFUNCTION" 5 "EFUSE_SELF_TEST_EFUSE_RESULT_FAILED_POWER_FET_STUCK_ON" 4 "EFUSE_SELF_TEST_EFUSE_RESULT_FAILED_EFUSE_OUTPUT_SHORT" 3 "EFUSE_SELF_TEST_EFUSE_RESULT_FAILED_RAILS_UNSTABLE" 2 "EFUSE_SELF_TEST_EFUSE_RESULT_PASSED" 1 "EFUSE_SELF_TEST_EFUSE_RESULT_RUNNING" 0 "EFUSE_SELF_TEST_EFUSE_RESULT_NOT_RUN" ;
VAL_ 753 VCFRONT_leftControllerEFuseVNFSt 7 "EFUSE_ASIC_STATE_SELF_TEST" 6 "EFUSE_ASIC_STATE_SELF_TEST_PREP" 5 "EFUSE_ASIC_STATE_LOCKED" 4 "EFUSE_ASIC_STATE_UNLOCKED" 3 "EFUSE_ASIC_STATE_CONFIGURATION" 2 "EFUSE_ASIC_STATE_WAKEUP" 1 "EFUSE_ASIC_STATE_STANDBY" 0 "EFUSE_ASIC_STATE_UNKNOWN" ;
VAL_ 753 VCFRONT_leftControllerEFuseVNFSe 3 "EFUSE_SELF_TEST_SKIPPED" 2 "EFUSE_SELF_TEST_COMPLETE" 1 "EFUSE_SELF_TEST_ACTIVE" 0 "EFUSE_SELF_TEST_NOT_COMPLETE" ;
VAL_ 753 VCFRONT_PCSState 3 "EFUSE_STATE_SNA" 2 "EFUSE_STATE_LOCKED_OUT" 1 "EFUSE_STATE_ON" 0 "EFUSE_STATE_OFF" ;
VAL_ 753 VCFRONT_pcsSelfTestResult 12 "EFUSE_SELF_TEST_EFUSE_RESULT_SNA" 11 "EFUSE_SELF_TEST_EFUSE_RESULT_SKIPPED" 10 "EFUSE_SELF_TEST_EFUSE_RESULT_FAILED_NOT_LATCHED" 9 "EFUSE_SELF_TEST_EFUSE_RESULT_FAILED_TURN_OFF_PATH_TOO_SLOW" 8 "EFUSE_SELF_TEST_EFUSE_RESULT_FAILED_ENABLE_HIGH_MALFUNCTION" 7 "EFUSE_SELF_TEST_EFUSE_RESULT_FAILED_POWER_FET_CHANNEL_OPEN" 6 "EFUSE_SELF_TEST_EFUSE_RESULT_FAILED_ENABLE_LOW_MALFUNCTION" 5 "EFUSE_SELF_TEST_EFUSE_RESULT_FAILED_POWER_FET_STUCK_ON" 4 "EFUSE_SELF_TEST_EFUSE_RESULT_FAILED_EFUSE_OUTPUT_SHORT" 3 "EFUSE_SELF_TEST_EFUSE_RESULT_FAILED_RAILS_UNSTABLE" 2 "EFUSE_SELF_TEST_EFUSE_RESULT_PASSED" 1 "EFUSE_SELF_TEST_EFUSE_RESULT_RUNNING" 0 "EFUSE_SELF_TEST_EFUSE_RESULT_NOT_RUN" ;
VAL_ 753 VCFRONT_PCSEFuseVNFState 7 "EFUSE_ASIC_STATE_SELF_TEST" 6 "EFUSE_ASIC_STATE_SELF_TEST_PREP" 5 "EFUSE_ASIC_STATE_LOCKED" 4 "EFUSE_ASIC_STATE_UNLOCKED" 3 "EFUSE_ASIC_STATE_CONFIGURATION" 2 "EFUSE_ASIC_STATE_WAKEUP" 1 "EFUSE_ASIC_STATE_STANDBY" 0 "EFUSE_ASIC_STATE_UNKNOWN" ;
VAL_ 753 VCFRONT_PCSEFuseVNFSelfTestStatu 3 "EFUSE_SELF_TEST_SKIPPED" 2 "EFUSE_SELF_TEST_COMPLETE" 1 "EFUSE_SELF_TEST_ACTIVE" 0 "EFUSE_SELF_TEST_NOT_COMPLETE" ;
VAL_ 753 VCFRONT_iBoosterState 3 "EFUSE_STATE_SNA" 2 "EFUSE_STATE_LOCKED_OUT" 1 "EFUSE_STATE_ON" 0 "EFUSE_STATE_OFF" ;
VAL_ 753 VCFRONT_iBoosterSelfTestResult 12 "EFUSE_SELF_TEST_EFUSE_RESULT_SNA" 11 "EFUSE_SELF_TEST_EFUSE_RESULT_SKIPPED" 10 "EFUSE_SELF_TEST_EFUSE_RESULT_FAILED_NOT_LATCHED" 9 "EFUSE_SELF_TEST_EFUSE_RESULT_FAILED_TURN_OFF_PATH_TOO_SLOW" 8 "EFUSE_SELF_TEST_EFUSE_RESULT_FAILED_ENABLE_HIGH_MALFUNCTION" 7 "EFUSE_SELF_TEST_EFUSE_RESULT_FAILED_POWER_FET_CHANNEL_OPEN" 6 "EFUSE_SELF_TEST_EFUSE_RESULT_FAILED_ENABLE_LOW_MALFUNCTION" 5 "EFUSE_SELF_TEST_EFUSE_RESULT_FAILED_POWER_FET_STUCK_ON" 4 "EFUSE_SELF_TEST_EFUSE_RESULT_FAILED_EFUSE_OUTPUT_SHORT" 3 "EFUSE_SELF_TEST_EFUSE_RESULT_FAILED_RAILS_UNSTABLE" 2 "EFUSE_SELF_TEST_EFUSE_RESULT_PASSED" 1 "EFUSE_SELF_TEST_EFUSE_RESULT_RUNNING" 0 "EFUSE_SELF_TEST_EFUSE_RESULT_NOT_RUN" ;
VAL_ 753 VCFRONT_EPAS3PState 3 "EFUSE_STATE_SNA" 2 "EFUSE_STATE_LOCKED_OUT" 1 "EFUSE_STATE_ON" 0 "EFUSE_STATE_OFF" ;
VAL_ 753 VCFRONT_EPAS3PSelfTestResult 12 "EFUSE_SELF_TEST_EFUSE_RESULT_SNA" 11 "EFUSE_SELF_TEST_EFUSE_RESULT_SKIPPED" 10 "EFUSE_SELF_TEST_EFUSE_RESULT_FAILED_NOT_LATCHED" 9 "EFUSE_SELF_TEST_EFUSE_RESULT_FAILED_TURN_OFF_PATH_TOO_SLOW" 8 "EFUSE_SELF_TEST_EFUSE_RESULT_FAILED_ENABLE_HIGH_MALFUNCTION" 7 "EFUSE_SELF_TEST_EFUSE_RESULT_FAILED_POWER_FET_CHANNEL_OPEN" 6 "EFUSE_SELF_TEST_EFUSE_RESULT_FAILED_ENABLE_LOW_MALFUNCTION" 5 "EFUSE_SELF_TEST_EFUSE_RESULT_FAILED_POWER_FET_STUCK_ON" 4 "EFUSE_SELF_TEST_EFUSE_RESULT_FAILED_EFUSE_OUTPUT_SHORT" 3 "EFUSE_SELF_TEST_EFUSE_RESULT_FAILED_RAILS_UNSTABLE" 2 "EFUSE_SELF_TEST_EFUSE_RESULT_PASSED" 1 "EFUSE_SELF_TEST_EFUSE_RESULT_RUNNING" 0 "EFUSE_SELF_TEST_EFUSE_RESULT_NOT_RUN" ;
VAL_ 753 VCFRONT_EPAS3PEFuseVNFState 7 "EFUSE_ASIC_STATE_SELF_TEST" 6 "EFUSE_ASIC_STATE_SELF_TEST_PREP" 5 "EFUSE_ASIC_STATE_LOCKED" 4 "EFUSE_ASIC_STATE_UNLOCKED" 3 "EFUSE_ASIC_STATE_CONFIGURATION" 2 "EFUSE_ASIC_STATE_WAKEUP" 1 "EFUSE_ASIC_STATE_STANDBY" 0 "EFUSE_ASIC_STATE_UNKNOWN" ;
VAL_ 753 VCFRONT_EPAS3PEFuseHardshortThre 15 "VNF1048_HSHT_160_MV" 14 "VNF1048_HSHT_139_3_MV" 13 "VNF1048_HSHT_121_3_MV" 12 "VNF1048_HSHT_105_6_MV" 11 "VNF1048_HSHT_91_9_MV" 10 "VNF1048_HSHT_80_MV" 9 "VNF1048_HSHT_69_6_MV" 8 "VNF1048_HSHT_60_6_MV" 7 "VNF1048_HSHT_52_8_MV" 6 "VNF1048_HSHT_45_9_MV" 5 "VNF1048_HSHT_40_MV" 4 "VNF1048_HSHT_34_8_MV" 3 "VNF1048_HSHT_30_3_MV" 2 "VNF1048_HSHT_26_4_MV" 1 "VNF1048_HSHT_23_MV" 0 "VNF1048_HSHT_20_MV" ;
VAL_ 753 VCFRONT_EPAS3PEFuseVNFSelfTestSt 3 "EFUSE_SELF_TEST_SKIPPED" 2 "EFUSE_SELF_TEST_COMPLETE" 1 "EFUSE_SELF_TEST_ACTIVE" 0 "EFUSE_SELF_TEST_NOT_COMPLETE" ;
VAL_ 753 VCFRONT_EPAS3SState 3 "EFUSE_STATE_SNA" 2 "EFUSE_STATE_LOCKED_OUT" 1 "EFUSE_STATE_ON" 0 "EFUSE_STATE_OFF" ;
VAL_ 753 VCFRONT_EPAS3SSelfTestResult 12 "EFUSE_SELF_TEST_EFUSE_RESULT_SNA" 11 "EFUSE_SELF_TEST_EFUSE_RESULT_SKIPPED" 10 "EFUSE_SELF_TEST_EFUSE_RESULT_FAILED_NOT_LATCHED" 9 "EFUSE_SELF_TEST_EFUSE_RESULT_FAILED_TURN_OFF_PATH_TOO_SLOW" 8 "EFUSE_SELF_TEST_EFUSE_RESULT_FAILED_ENABLE_HIGH_MALFUNCTION" 7 "EFUSE_SELF_TEST_EFUSE_RESULT_FAILED_POWER_FET_CHANNEL_OPEN" 6 "EFUSE_SELF_TEST_EFUSE_RESULT_FAILED_ENABLE_LOW_MALFUNCTION" 5 "EFUSE_SELF_TEST_EFUSE_RESULT_FAILED_POWER_FET_STUCK_ON" 4 "EFUSE_SELF_TEST_EFUSE_RESULT_FAILED_EFUSE_OUTPUT_SHORT" 3 "EFUSE_SELF_TEST_EFUSE_RESULT_FAILED_RAILS_UNSTABLE" 2 "EFUSE_SELF_TEST_EFUSE_RESULT_PASSED" 1 "EFUSE_SELF_TEST_EFUSE_RESULT_RUNNING" 0 "EFUSE_SELF_TEST_EFUSE_RESULT_NOT_RUN" ;
VAL_ 753 VCFRONT_EPAS3SEFuseVNFState 7 "EFUSE_ASIC_STATE_SELF_TEST" 6 "EFUSE_ASIC_STATE_SELF_TEST_PREP" 5 "EFUSE_ASIC_STATE_LOCKED" 4 "EFUSE_ASIC_STATE_UNLOCKED" 3 "EFUSE_ASIC_STATE_CONFIGURATION" 2 "EFUSE_ASIC_STATE_WAKEUP" 1 "EFUSE_ASIC_STATE_STANDBY" 0 "EFUSE_ASIC_STATE_UNKNOWN" ;
VAL_ 753 VCFRONT_EPAS3SEFuseVNFSelfTestSt 3 "EFUSE_SELF_TEST_SKIPPED" 2 "EFUSE_SELF_TEST_COMPLETE" 1 "EFUSE_SELF_TEST_ACTIVE" 0 "EFUSE_SELF_TEST_NOT_COMPLETE" ;
VAL_ 753 VCFRONT_ESPMotorState 3 "EFUSE_STATE_SNA" 2 "EFUSE_STATE_LOCKED_OUT" 1 "EFUSE_STATE_ON" 0 "EFUSE_STATE_OFF" ;
VAL_ 753 VCFRONT_ESPMotorSelfTestResult 12 "EFUSE_SELF_TEST_EFUSE_RESULT_SNA" 11 "EFUSE_SELF_TEST_EFUSE_RESULT_SKIPPED" 10 "EFUSE_SELF_TEST_EFUSE_RESULT_FAILED_NOT_LATCHED" 9 "EFUSE_SELF_TEST_EFUSE_RESULT_FAILED_TURN_OFF_PATH_TOO_SLOW" 8 "EFUSE_SELF_TEST_EFUSE_RESULT_FAILED_ENABLE_HIGH_MALFUNCTION" 7 "EFUSE_SELF_TEST_EFUSE_RESULT_FAILED_POWER_FET_CHANNEL_OPEN" 6 "EFUSE_SELF_TEST_EFUSE_RESULT_FAILED_ENABLE_LOW_MALFUNCTION" 5 "EFUSE_SELF_TEST_EFUSE_RESULT_FAILED_POWER_FET_STUCK_ON" 4 "EFUSE_SELF_TEST_EFUSE_RESULT_FAILED_EFUSE_OUTPUT_SHORT" 3 "EFUSE_SELF_TEST_EFUSE_RESULT_FAILED_RAILS_UNSTABLE" 2 "EFUSE_SELF_TEST_EFUSE_RESULT_PASSED" 1 "EFUSE_SELF_TEST_EFUSE_RESULT_RUNNING" 0 "EFUSE_SELF_TEST_EFUSE_RESULT_NOT_RUN" ;
VAL_ 753 VCFRONT_ESPMotorEFuseVNFState 7 "EFUSE_ASIC_STATE_SELF_TEST" 6 "EFUSE_ASIC_STATE_SELF_TEST_PREP" 5 "EFUSE_ASIC_STATE_LOCKED" 4 "EFUSE_ASIC_STATE_UNLOCKED" 3 "EFUSE_ASIC_STATE_CONFIGURATION" 2 "EFUSE_ASIC_STATE_WAKEUP" 1 "EFUSE_ASIC_STATE_STANDBY" 0 "EFUSE_ASIC_STATE_UNKNOWN" ;
VAL_ 753 VCFRONT_ESPMotorEFuseVNFSelfTest 3 "EFUSE_SELF_TEST_SKIPPED" 2 "EFUSE_SELF_TEST_COMPLETE" 1 "EFUSE_SELF_TEST_ACTIVE" 0 "EFUSE_SELF_TEST_NOT_COMPLETE" ;
VAL_ 753 VCFRONT_ESPValveState 3 "EFUSE_STATE_SNA" 2 "EFUSE_STATE_LOCKED_OUT" 1 "EFUSE_STATE_ON" 0 "EFUSE_STATE_OFF" ;
VAL_ 753 VCFRONT_autopilot2State 3 "EFUSE_STATE_SNA" 2 "EFUSE_STATE_LOCKED_OUT" 1 "EFUSE_STATE_ON" 0 "EFUSE_STATE_OFF" ;
VAL_ 753 VCFRONT_vbatFusedSelfTestResult 12 "EFUSE_SELF_TEST_EFUSE_RESULT_SNA" 11 "EFUSE_SELF_TEST_EFUSE_RESULT_SKIPPED" 10 "EFUSE_SELF_TEST_EFUSE_RESULT_FAILED_NOT_LATCHED" 9 "EFUSE_SELF_TEST_EFUSE_RESULT_FAILED_TURN_OFF_PATH_TOO_SLOW" 8 "EFUSE_SELF_TEST_EFUSE_RESULT_FAILED_ENABLE_HIGH_MALFUNCTION" 7 "EFUSE_SELF_TEST_EFUSE_RESULT_FAILED_POWER_FET_CHANNEL_OPEN" 6 "EFUSE_SELF_TEST_EFUSE_RESULT_FAILED_ENABLE_LOW_MALFUNCTION" 5 "EFUSE_SELF_TEST_EFUSE_RESULT_FAILED_POWER_FET_STUCK_ON" 4 "EFUSE_SELF_TEST_EFUSE_RESULT_FAILED_EFUSE_OUTPUT_SHORT" 3 "EFUSE_SELF_TEST_EFUSE_RESULT_FAILED_RAILS_UNSTABLE" 2 "EFUSE_SELF_TEST_EFUSE_RESULT_PASSED" 1 "EFUSE_SELF_TEST_EFUSE_RESULT_RUNNING" 0 "EFUSE_SELF_TEST_EFUSE_RESULT_NOT_RUN" ;
VAL_ 753 VCFRONT_IBSUnfilteredTemperature -32768 "SNA" ;
VAL_ 769 VCFRONT_infoIndex 255 "END" 41 "SUBCOMPONENT14" 40 "SUBCOMPONENT13" 39 "SUBCOMPONENT12" 38 "SUBCOMPONENT11" 37 "SUBCOMPONENT10" 36 "SUBCOMPONENT9" 35 "SUBCOMPONENT8" 34 "SUBCOMPONENT7" 33 "SUBCOMPONENT6" 32 "SUBCOMPONENT5" 31 "SUBCOMPONENT4" 24 "SUBCOMPONENT3" 23 "SUBCOMPONENT2" 20 "UDS_PROTOCOL_BOOTCRC" 19 "VERSION_DEPRECATED" 18 "BOOTLOADER_GITHASH" 17 "APP_GITHASH" 16 "SUBCOMPONENT1" 15 "BOOTLOADER_CRC" 14 "BOOTLOADER_SVN" 13 "APP_CRC" 11 "PCBAID_ASSYID_USAGEID" 10 "BUILD_HWID_COMPONENTID" 9 "DEPRECATED_9" 8 "DEPRECATED_8" 7 "DEPRECATED_7" 6 "DEPRECATED_6" 5 "DEPRECATED_5" 4 "DEPRECATED_4" 3 "DEPRECATED_3" 2 "DEPRECATED_2" 1 "DEPRECATED_1" 0 "DEPRECATED_0" ;
VAL_ 769 VCFRONT_infoBuildType 4 "INFO_MFG_BUILD" 3 "INFO_TRACEABLE_CI_BUILD" 2 "INFO_LOCAL_BUILD" 1 "INFO_PLATFORM_BUILD" 0 "INFO_UNKNOWN_BUILD" ;
VAL_ 769 VCFRONT_infoAssemblyId 255 "ASSEMBLY_SNA" 1 "ASSEMBLY1" ;
VAL_ 1801 VCFRONT_logging0point1HzIndex 31 "END" 30 "HEADLAMP_LEFT_ECULESS_IO_DIAGNOSTIC" 29 "HEADLAMP_RIGHT_ECULESS_IO_DIAGNOSTIC" 28 "COMPRESSOR_WEAR_COUNTERS" 27 "HEADLAMP_RIGHT_EEPROM_INFO" 26 "HEADLAMP_LEFT_EEPROM_INFO" 25 "EXV_VALVE_TYPES" 24 "PART_FAILURE_CONFIDENCE_CONTINUED" 23 "PART_FAILURE_CONFIDENCE" 22 "LIGHT_DEBUG" 21 "HEADLAMP_COMM_FAULT_COUNTERS" 20 "HEADLAMP_MIGRATION" 19 "EXV_TOTAL_DISTANCE_COUNTERS_3" 18 "EXV_TOTAL_DISTANCE_COUNTERS_2" 17 "EXV_TOTAL_DISTANCE_COUNTERS_1" 16 "EXV_CCR_COUNTERS_2" 15 "EXV_CCR_COUNTERS_1" 14 "EXV_CCL_COUNTERS_2" 13 "EXV_CCL_COUNTERS_1" 12 "EXV_LCC_COUNTERS_2" 11 "EXV_LCC_COUNTERS_1" 10 "EXV_RECIRC_COUNTERS_2" 9 "EXV_RECIRC_COUNTERS_1" 8 "EXV_EVAPORATOR_COUNTERS_2" 7 "EXV_EVAPORATOR_COUNTERS_1" 6 "EXV_CHILLER_COUNTERS_2" 5 "EXV_CHILLER_COUNTERS_1" 4 "HEADLAMP_AIMED_POSITION" 3 "HEADLAMP_CURRENT_POSITION" 2 "HCMR_LED_TEMPS" 1 "HCML_LED_TEMPS" 0 "LIGHT_CURRENTS" ;
VAL_ 1801 VC_hcmlFactoryOfOrigin 3 "HELLA_MEXICO" 2 "HELLA_SLOVAKIA" 1 "HELLA_CHINA" 0 "UNKNOWN" ;
VAL_ 1801 VC_hcmlHellaPartNumberStatus 1 "FAULT" 0 "OK" ;
VAL_ 1801 VC_hcmlCurrentBinMappingType 2 "BIN_MAP_TYPE_2" 1 "BIN_MAP_TYPE_1" 0 "BIN_MAP_TYPE_UNKNOWN" ;
VAL_ 1801 VC_hcmlCurrentBin0Value 7 "INVALID_LIGHTCLASS" 4 "LIGHTCLASS_4" 3 "LIGHTCLASS_3" 2 "LIGHTCLASS_2" 1 "LIGHTCLASS_1" 0 "LIGHTCLASS_SNA" ;
VAL_ 1801 VC_hcmlCurrentBin1Value 7 "INVALID_LIGHTCLASS" 4 "LIGHTCLASS_4" 3 "LIGHTCLASS_3" 2 "LIGHTCLASS_2" 1 "LIGHTCLASS_1" 0 "LIGHTCLASS_SNA" ;
VAL_ 1801 VC_hcmlCurrentBin2Value 7 "INVALID_LIGHTCLASS" 4 "LIGHTCLASS_4" 3 "LIGHTCLASS_3" 2 "LIGHTCLASS_2" 1 "LIGHTCLASS_1" 0 "LIGHTCLASS_SNA" ;
VAL_ 1801 VC_hcmlCurrentBin3Value 7 "INVALID_LIGHTCLASS" 4 "LIGHTCLASS_4" 3 "LIGHTCLASS_3" 2 "LIGHTCLASS_2" 1 "LIGHTCLASS_1" 0 "LIGHTCLASS_SNA" ;
VAL_ 1801 VC_hcmlCurrentBin4Value 7 "INVALID_LIGHTCLASS" 4 "LIGHTCLASS_4" 3 "LIGHTCLASS_3" 2 "LIGHTCLASS_2" 1 "LIGHTCLASS_1" 0 "LIGHTCLASS_SNA" ;
VAL_ 1801 VC_hcmlCurrentBin5Value 7 "INVALID_LIGHTCLASS" 4 "LIGHTCLASS_4" 3 "LIGHTCLASS_3" 2 "LIGHTCLASS_2" 1 "LIGHTCLASS_1" 0 "LIGHTCLASS_SNA" ;
VAL_ 1801 VC_hcmlRegionAndSide 6 "HEADLAMP_REGION_AND_SIDE_ECE_RHD_RIGHT" 5 "HEADLAMP_REGION_AND_SIDE_ECE_RHD_LEFT" 4 "HEADLAMP_REGION_AND_SIDE_ECE_LHD_RIGHT" 3 "HEADLAMP_REGION_AND_SIDE_ECE_LHD_LEFT" 2 "HEADLAMP_REGION_AND_SIDE_SAE_RIGHT" 1 "HEADLAMP_REGION_AND_SIDE_SAE_LEFT" 0 "HEADLAMP_REGION_AND_SIDE_SNA" ;
VAL_ 1801 VC_hcmrFactoryOfOrigin 3 "HELLA_MEXICO" 2 "HELLA_SLOVAKIA" 1 "HELLA_CHINA" 0 "UNKNOWN" ;
VAL_ 1801 VC_hcmrHellaPartNumberStatus 1 "FAULT" 0 "OK" ;
VAL_ 1801 VC_hcmrCurrentBinMappingType 2 "BIN_MAP_TYPE_2" 1 "BIN_MAP_TYPE_1" 0 "BIN_MAP_TYPE_UNKNOWN" ;
VAL_ 1801 VC_hcmrCurrentBin0Value 7 "INVALID_LIGHTCLASS" 4 "LIGHTCLASS_4" 3 "LIGHTCLASS_3" 2 "LIGHTCLASS_2" 1 "LIGHTCLASS_1" 0 "LIGHTCLASS_SNA" ;
VAL_ 1801 VC_hcmrCurrentBin1Value 7 "INVALID_LIGHTCLASS" 4 "LIGHTCLASS_4" 3 "LIGHTCLASS_3" 2 "LIGHTCLASS_2" 1 "LIGHTCLASS_1" 0 "LIGHTCLASS_SNA" ;
VAL_ 1801 VC_hcmrCurrentBin2Value 7 "INVALID_LIGHTCLASS" 4 "LIGHTCLASS_4" 3 "LIGHTCLASS_3" 2 "LIGHTCLASS_2" 1 "LIGHTCLASS_1" 0 "LIGHTCLASS_SNA" ;
VAL_ 1801 VC_hcmrCurrentBin3Value 7 "INVALID_LIGHTCLASS" 4 "LIGHTCLASS_4" 3 "LIGHTCLASS_3" 2 "LIGHTCLASS_2" 1 "LIGHTCLASS_1" 0 "LIGHTCLASS_SNA" ;
VAL_ 1801 VC_hcmrCurrentBin4Value 7 "INVALID_LIGHTCLASS" 4 "LIGHTCLASS_4" 3 "LIGHTCLASS_3" 2 "LIGHTCLASS_2" 1 "LIGHTCLASS_1" 0 "LIGHTCLASS_SNA" ;
VAL_ 1801 VC_hcmrCurrentBin5Value 7 "INVALID_LIGHTCLASS" 4 "LIGHTCLASS_4" 3 "LIGHTCLASS_3" 2 "LIGHTCLASS_2" 1 "LIGHTCLASS_1" 0 "LIGHTCLASS_SNA" ;
VAL_ 1801 VC_hcmrRegionAndSide 6 "HEADLAMP_REGION_AND_SIDE_ECE_RHD_RIGHT" 5 "HEADLAMP_REGION_AND_SIDE_ECE_RHD_LEFT" 4 "HEADLAMP_REGION_AND_SIDE_ECE_LHD_RIGHT" 3 "HEADLAMP_REGION_AND_SIDE_ECE_LHD_LEFT" 2 "HEADLAMP_REGION_AND_SIDE_SAE_RIGHT" 1 "HEADLAMP_REGION_AND_SIDE_SAE_LEFT" 0 "HEADLAMP_REGION_AND_SIDE_SNA" ;
VAL_ 705 VCFRONT_logging10HzIndex 5 "END" 4 "EXV_TORQUE_COUNT" 3 "ACTIVE_LOUVER_RADAR" 2 "COMPRESSOR_REFRIGERANT_LOUVER" 1 "THERMAL_FAN_COOLANT_COMP" 0 "COOLANT_PUMPS_FAN" ;
VAL_ 897 VCFRONT_logging1HzIndex 26 "END" 25 "MISC_FOUR" 24 "POWER_RATIONALITY_VCRIGHT" 23 "POWER_RATIONALITY_VCLEFT" 22 "SLEEP_WAKE" 21 "MISC_THREE" 20 "HSD_CURRENTS_2" 19 "HSD_CURRENTS_1" 18 "MISC_TWO" 17 "HP_PT_TARGETS" 16 "COOLANT_2" 15 "BODY_CONTROL" 14 "HP_MODE_OPTIONS_AND_ESTIMATES" 13 "HP_MODE_SELECT_AND_ESTIMATES" 12 "HP_ARBITRATION" 11 "HP_PRESSURE_CONTROL" 10 "HP_TEMPS_AND_DEMANDS" 9 "HP_DISSIPATION_AND_POWER" 8 "HP_EXV_CALIBRATION" 7 "HP_CYCLE_MODEL" 6 "HP_CONTROL_LOOP_AND_STATE" 5 "HP_DATA_AND_ACCUMULATORS" 4 "HP_EXV_RANGE" 3 "MISC_ONE" 2 "COOLANT_VALVE" 1 "FAN_DEMAND_CONDENSER_AND_FET_TEMPS" 0 "COOLANT" ;
VAL_ 897 VCFRONT_modeTransitionID 54 "SER_14_apInletOvertemp" 53 "ENTER_AMBIENTSOURCE_DRIVERLESS_SELF_TEST" 52 "SER_13_driverlessSelfTestActive" 51 "ENTER_SERIES_COP1" 50 "PAR_13_charge_battNeedsActiveCooling" 49 "SER_12_charge_battNeedsCooling" 48 "PAR_12_drive_cabinOverheatProtectActive" 47 "PAR_11_batteryDischarge" 46 "SER_11_service_highCoolantFlowReq" 45 "PAR_10_charge_battNearPassiveTarget" 44 "PAR_9_FC_battAboveHotStagnationTemp" 43 "PAR_8_FC_battNeedsActiveCooling_evapEnabled" 42 "PAR_7_FC_battNeedsActiveCooling_evapDisabled" 41 "PAR_6_drive_battAboveHotStagnationTemp" 40 "PAR_5_drive_cannotPassivelyCoolBatt" 39 "PAR_4_drive_chillerPassivelyCoolsBatt" 38 "PAR_3_drive_ptNeedsActiveCooling" 37 "PAR_2_drive_battNeedsActiveCooling_evapDisabled" 36 "PAR_1_drive_battNeedsActiveCooling_evapEnabled" 35 "SER_10_charge_battBelowPassiveTarget" 34 "SER_9_FC_battNeedsActiveCooling_evapEnabled" 33 "SER_8_FC_battNeedsActiveCooling_evapDisabled" 32 "SER_7_FC_battHeatingNeeded" 31 "SER_6_drive_battBelowPassiveOrNeedsHeat" 30 "SER_5_drive_radPassivelyCoolsBatt" 29 "SER_4_drive_chillerPassivelyCools" 28 "SER_3_drive_battBelowHotStagnationTemp" 27 "SER_2_drive_battNeedsActiveCooling_evapDisabled" 26 "SER_1_drive_battNeedsActiveCooling_evapEnabled" 25 "EXIT_AMBIENTSOURCE" 24 "ENTER_AMBIENTSOURCE" 23 "UNDEFINED" 22 "OVERRIDE" 21 "INIT" 20 "PARALLEL_10_batteryDischarge" 19 "PARALLEL_9_drive_batteryThermalLimiting" 18 "SERIES_9_drive_driveUnitThermalLimiting" 17 "SERIES_8_preConditioning_batteryNeedsHeat" 16 "PARALLEL_8_fastCharge_batteryWantsHeat" 15 "PARALLEL_7_fastCharge_batteryWantsCool" 14 "SERIES_7_fastCharge_batteryWantsCool" 13 "SERIES_6_fastCharge_batteryNeedsHeat" 12 "PARALLEL_6_charge_batteryWantsCool" 11 "PARALLEL_5_charge_batteryWantsHeat" 10 "SERIES_5_charge_batteryWantsHeat" 9 "SERIES_4_charge_batteryNeedsHeat" 8 "PARALLEL_4_drive_batteryNeedsCool" 7 "PARALLEL_3_drive_batteryWantsCool" 6 "PARALLEL_2_drive_batteryWantsHeat" 5 "SERIES_3_drive_batteryWantsHeat" 4 "SERIES_2_drive_batteryNeedsHeat" 3 "SERIES_1_drive_batteryWantsCool" 2 "SERIES_F3_faultTempSensors" 1 "SERIES_F2_faultPumps" 0 "PARALLEL_F1_noFlowRequest" ;
VAL_ 897 VCFRONT_modeDesired 3 "AMBIENT_SOURCE" 2 "BLEND" 1 "PARALLEL" 0 "SERIES" ;
VAL_ 897 VCFRONT_tempRefrigSuction 255 "SNA" ;
VAL_ 897 VCFRONT_pumpBatteryFETTemp 255 "SNA" ;
VAL_ 897 VCFRONT_pumpPowertrainFETTemp 255 "SNA" ;
VAL_ 897 VCFRONT_radiatorFanFETTemp 255 "SNA" ;
VAL_ 897 VCFRONT_radiatorFanRunReason 13 "FACTORY_NO_COOLANT" 12 "DRIVERLESS_SELF_TEST" 11 "BATTERY_DISCHARGE" 10 "DI_BURN_IN" 9 "RAD_CLEAR" 8 "UDS" 7 "MIN_ON_NVH" 6 "MIN_ON_GLOBAL" 5 "COAST_MODE" 4 "HEAT_PUMP" 3 "NVH_MASKING" 2 "AMBIENT_SNIFF" 1 "ACTIVE_MANAGER" 0 "NONE" ;
VAL_ 897 VCFRONT_coolantTempBasedMode 3 "AMBIENT_SOURCE" 2 "BLEND" 1 "PARALLEL" 0 "SERIES" ;
VAL_ 897 VCFRONT_coolantValveRecalReason 6 "NVRAM_LOSS" 5 "MOTOR_FEEDBACK_INTERRUPTED" 4 "SELF_TEST" 3 "CALIBRATION_FAULT_NO_TRAVEL" 2 "GENERAL_FAULT" 1 "MAX_TRAVEL" 0 "UNDEFINED" ;
VAL_ 897 VCFRONT_coolantValveCountRange 1023 "SNA" ;
VAL_ 897 VCFRONT_coolantValveRadBypass 127 "SNA" ;
VAL_ 897 VCFRONT_hpChargeCableType 2 "AC_CHARGER_PRESENT" 1 "DC_CHARGER_PRESENT" 0 "NO_CHARGER_PRESENT" ;
VAL_ 897 VCFRONT_tempSuperheatActual 1023 "SNA" ;
VAL_ 897 VCFRONT_refCommissionStatus 2 "REFRIGERANT_COMMISSIONED" 1 "REFRIGERANT_UNCOMMISSIONED" 0 "REFRIGERANT_UNKNOWN" ;
VAL_ 897 VCFRONT_passiveCoolingState 3 "CannotCoolBattery" 2 "ChillerAndRadCoolSeriesLoop" 1 "ChillerCoolsParallelBattLoop" 0 "ChillerCoolsSeriesLoop" ;
VAL_ 897 VCFRONT_hpRefrigerantPurgeState 2 "COMPLETE" 1 "EVAP_PURGE" 0 "IDLE" ;
VAL_ 897 VCFRONT_chillerEXVControlState 5 "PARKED" 4 "CALIBRATING_TIMEOUT" 3 "CALIBRATING" 2 "DISCHARGE" 1 "ACTIVE" 0 "INIT" ;
VAL_ 897 VCFRONT_evapEXVControlState 5 "PARKED" 4 "CALIBRATING_TIMEOUT" 3 "CALIBRATING" 2 "DISCHARGE" 1 "ACTIVE" 0 "INIT" ;
VAL_ 897 VCFRONT_recircEXVControlState 5 "PARKED" 4 "CALIBRATING_TIMEOUT" 3 "CALIBRATING" 2 "DISCHARGE" 1 "ACTIVE" 0 "INIT" ;
VAL_ 897 VCFRONT_lccEXVControlState 5 "PARKED" 4 "CALIBRATING_TIMEOUT" 3 "CALIBRATING" 2 "DISCHARGE" 1 "ACTIVE" 0 "INIT" ;
VAL_ 897 VCFRONT_cclEXVControlState 5 "PARKED" 4 "CALIBRATING_TIMEOUT" 3 "CALIBRATING" 2 "DISCHARGE" 1 "ACTIVE" 0 "INIT" ;
VAL_ 897 VCFRONT_ccrEXVControlState 5 "PARKED" 4 "CALIBRATING_TIMEOUT" 3 "CALIBRATING" 2 "DISCHARGE" 1 "ACTIVE" 0 "INIT" ;
VAL_ 897 VCFRONT_tempRefrigLiquid 2047 "SNA" ;
VAL_ 897 VCFRONT_radBypassMoveReason 11 "DRIVERLESS_SELF_TEST" 10 "HEATPUMP" 9 "UDS" 8 "EXIT_SERIES" 7 "ACTIVE_BATT_UNBYPASS" 6 "ACTIVE_PT_UNBYPASS" 5 "RAD_HEAT_UNBYPASS" 4 "RAD_HEAT_BYPASS" 3 "PASSIVE_BYPASS" 2 "PASSIVE_UNBYPASS" 1 "INIT_BYPASS" 0 "INIT_UNBYPASS" ;
VAL_ 897 VCFRONT_louverPosReason 11 "DRIVERLESS_SELF_TEST" 10 "BATTERY_DISCHARGE" 9 "HIGH_SPEED" 8 "UDS" 7 "COAST_MODE" 6 "FAN_FAULT" 5 "FAN_RUN" 4 "BOUNDS_CHECK" 3 "SNIFFING" 2 "PASSIVE_MANAGER" 1 "CONDENSOR_MANAGER" 0 "NONE" ;
VAL_ 897 VCFRONT_chargeShuttleType 3 "CHARGE_SHUTTLE_COP1" 2 "CHARGE_SHUTTLE_LCCR" 1 "CHARGE_SHUTTLE_STANDARD" 0 "CHARGE_SHUTTLE_NONE" ;
VAL_ 897 VCFRONT_tempRefrigDischarge 2047 "SNA" ;
VAL_ 897 VCFRONT_pumpBatteryRPMTarget 255 "SNA" ;
VAL_ 897 VCFRONT_pumpPowertrainRPMTarget 255 "SNA" ;
VAL_ 897 VCFRONT_radiatorFanRPMTarget 255 "SNA" ;
VAL_ 897 VCFRONT_ambientTempState 3 "SNIFFING" 2 "LATCHED" 1 "MEASUREING" 0 "INIT" ;
VAL_ 897 VCFRONT_ambientTempUnlatchReason 6 "SNIFF_STARTDRIVE" 5 "SNIFF_BLOCKED" 4 "SNIFF_TIMEBASED" 3 "LOUVERS_CLOSED" 2 "FAN_AIRFLOW" 1 "VEHICLE_SPEED" 0 "NONE" ;
VAL_ 513 VCFRONT_loggingAndVitals10HzInde 4 "END" 3 "EXV_FLOW_TARGET" 2 "EXV_FLOW" 1 "STATES_AND_SENSORS" 0 "TARGETS_AND_ACTUALS_0" ;
VAL_ 513 VCFRONT_pumpBatteryRPMActual 255 "SNA" ;
VAL_ 513 VCFRONT_pumpPowertrainRPMActual 255 "SNA" ;
VAL_ 513 VCFRONT_radiatorFanRPMActual 255 "SNA" ;
VAL_ 513 VCFRONT_pressureRefrigLiquid 511 "SNA" ;
VAL_ 513 VCFRONT_compressorState 3 "FAULT" 2 "RUNNING" 1 "READY" 0 "STANDBY" ;
VAL_ 513 VCFRONT_exvState 10 "INIT_CLOSE_OVERDRIVE" 9 "CALIB_CLOSE_OVERDRIVE" 8 "CALIB_CLOSE" 7 "READY_SHUT" 6 "OVERDRIVING_SHUT" 5 "WAIT" 4 "FAULTED" 3 "READY" 2 "INIT_CLOSE" 1 "INIT_OPEN" 0 "UNINIT" ;
VAL_ 513 VCFRONT_solenoidEvapState 3 "SOLENOID_FAULTED" 2 "SOLENOID_CLOSED" 1 "SOLENOID_OPENED" 0 "SOLENOID_UNDEFINED" ;
VAL_ 513 VCFRONT_coolantValveMode 3 "AMBIENT_SOURCE" 2 "BLEND" 1 "PARALLEL" 0 "SERIES" ;
VAL_ 513 VCFRONT_compFaultSeverity 3 "HIGH" 2 "MEDIUM" 1 "LOW" 0 "NONE" ;
VAL_ 513 VCFRONT_hpHighSideHX 3 "hpHighSideHX_BOTH" 2 "hpHighSideHX_CC" 1 "hpHighSideHX_LCC" 0 "hpHighSideHX_NONE" ;
VAL_ 513 VCFRONT_hpLowSideHX 3 "hpLowSideHX_BOTH" 2 "hpLowSideHX_EVAP" 1 "hpLowSideHX_CHILLER" 0 "hpLowSideHX_NONE" ;
VAL_ 513 VCFRONT_hpDominantLoad 6 "hpDominantLoad_HIGH_BOTH" 5 "hpDominantLoad_CC" 4 "hpDominantLoad_LCC" 3 "hpDominantLoad_LOW_BOTH" 2 "hpDominantLoad_CHILLER" 1 "hpDominantLoad_EVAP" 0 "hpDominantLoad_NONE" ;
VAL_ 513 VCFRONT_hpBlendType 2 "HP_FULL" 1 "HP_PARTIAL" 0 "HP_NONE" ;
VAL_ 513 VCFRONT_hpCabinLoadType 3 "hpCabinLoadType_EVAP" 2 "hpCabinLoadType_REHEAT" 1 "hpCabinLoadType_CC" 0 "hpCabinLoadType_NONE" ;
VAL_ 513 VCFRONT_hpBatteryLoadType 2 "BATT_COOL" 1 "BATT_HEAT" 0 "NONE" ;
VAL_ 513 VCFRONT_hpReqCoolantMode 4 "AMBIENT_SOURCE" 3 "PARALLEL" 2 "SERIES_BYPASS" 1 "SERIES_NO_BYPASS" 0 "ANY" ;
VAL_ 513 VCFRONT_compLiqPumpOutState 5 "COMP_LIQ_PUMP_OUT_ABORTED" 4 "COMP_LIQ_PUMP_OUT_COMPLETED" 3 "COMP_LIQ_PUMP_OUT_RUNNING" 2 "COMP_LIQ_PUMP_OUT_ALLOWED" 1 "COMP_LIQ_PUMP_OUT_WAITING" 0 "COMP_LIQ_PUMP_OUT_NOT_ALLOWED" ;
VAL_ 513 VCFRONT_frunkStateDBG 12 "FRUNK_STATE_FAULT_RELEASED" 11 "FRUNK_STATE_RESETTING" 10 "FRUNK_STATE_RELEASING_EXTENDING_2" 9 "FRUNK_STATE_RELEASING_RETRACTING_2" 8 "FRUNK_STATE_RELEASING_EXTENDING_1" 7 "FRUNK_STATE_RELEASING_RETRACTING_1" 6 "FRUNK_STATE_FAULT_CLOSED" 5 "FRUNK_STATE_FAULT_OPENED" 4 "FRUNK_STATE_FAULT" 3 "FRUNK_STATE_AJAR" 2 "FRUNK_STATE_OPENED" 1 "FRUNK_STATE_CLOSED" 0 "FRUNK_STATE_INIT" ;
VAL_ 513 VCFRONT_frunkSwitchGroupState 3 "FRUNKSWITCH_GROUP_CLOSED" 2 "FRUNKSWITCH_GROUP_OPENED" 1 "FRUNKSWITCH_GROUP_MISMATCHED" 0 "FRUNKSWITCH_GROUP_UNKNOWN" ;
VAL_ 513 VCFRONT_chillerExvState 10 "INIT_CLOSE_OVERDRIVE" 9 "CALIB_CLOSE_OVERDRIVE" 8 "CALIB_CLOSE" 7 "READY_SHUT" 6 "OVERDRIVING_SHUT" 5 "WAIT" 4 "FAULTED" 3 "READY" 2 "INIT_CLOSE" 1 "INIT_OPEN" 0 "UNINIT" ;
VAL_ 513 VCFRONT_evapExvState 10 "INIT_CLOSE_OVERDRIVE" 9 "CALIB_CLOSE_OVERDRIVE" 8 "CALIB_CLOSE" 7 "READY_SHUT" 6 "OVERDRIVING_SHUT" 5 "WAIT" 4 "FAULTED" 3 "READY" 2 "INIT_CLOSE" 1 "INIT_OPEN" 0 "UNINIT" ;
VAL_ 513 VCFRONT_recircExvState 10 "INIT_CLOSE_OVERDRIVE" 9 "CALIB_CLOSE_OVERDRIVE" 8 "CALIB_CLOSE" 7 "READY_SHUT" 6 "OVERDRIVING_SHUT" 5 "WAIT" 4 "FAULTED" 3 "READY" 2 "INIT_CLOSE" 1 "INIT_OPEN" 0 "UNINIT" ;
VAL_ 513 VCFRONT_lccExvState 10 "INIT_CLOSE_OVERDRIVE" 9 "CALIB_CLOSE_OVERDRIVE" 8 "CALIB_CLOSE" 7 "READY_SHUT" 6 "OVERDRIVING_SHUT" 5 "WAIT" 4 "FAULTED" 3 "READY" 2 "INIT_CLOSE" 1 "INIT_OPEN" 0 "UNINIT" ;
VAL_ 513 VCFRONT_cclExvState 10 "INIT_CLOSE_OVERDRIVE" 9 "CALIB_CLOSE_OVERDRIVE" 8 "CALIB_CLOSE" 7 "READY_SHUT" 6 "OVERDRIVING_SHUT" 5 "WAIT" 4 "FAULTED" 3 "READY" 2 "INIT_CLOSE" 1 "INIT_OPEN" 0 "UNINIT" ;
VAL_ 513 VCFRONT_ccrExvState 10 "INIT_CLOSE_OVERDRIVE" 9 "CALIB_CLOSE_OVERDRIVE" 8 "CALIB_CLOSE" 7 "READY_SHUT" 6 "OVERDRIVING_SHUT" 5 "WAIT" 4 "FAULTED" 3 "READY" 2 "INIT_CLOSE" 1 "INIT_OPEN" 0 "UNINIT" ;
VAL_ 737 VCFRONT_statusIndex 7 "INVALID" 6 "USER_PRESENCE" 5 "THERMAL" 4 "SYSTEM_HEALTH" 3 "REFRIGERANT_SYSTEM" 2 "HOMELINK" 1 "VEHICLE_STATE" 0 "BODY_CONTROLS" ;
VAL_ 737 VCFRONT_homelinkCommStatus 3 "HOMELINK_COMM_STATUS_FAULT" 2 "HOMELINK_COMM_STATUS_ON" 1 "HOMELINK_COMM_STATUS_OFF" 0 "HOMELINK_COMM_STATUS_SNA" ;
VAL_ 929 VCFRONT_vehicleStatusMuxIndex 1 "MUX1" 0 "MUX0" ;
VAL_ 929 VCFRONT_APGlassHeaterState 4 "HEATER_STATE_FAULT" 3 "HEATER_STATE_OFF_UNAVAILABLE" 2 "HEATER_STATE_OFF" 1 "HEATER_STATE_ON" 0 "HEATER_STATE_SNA" ;
VAL_ 929 VCFRONT_thermalSystemType 1 "HEAT_PUMP_THERMAL_SYSTEM" 0 "LEGACY_THERMAL_SYSTEM" ;
VAL_ 929 VCFRONT_diPowerOnState 5 "DI_POWERED_ON_FOR_WINCH" 4 "DI_POWER_GOING_DOWN" 3 "DI_POWERED_ON_FOR_DRIVE" 2 "DI_POWERED_ON_FOR_STATIONARY_HEAT" 1 "DI_POWERED_ON_FOR_SUMMON" 0 "DI_POWERED_OFF" ;
VAL_ 929 VCFRONT_12vStatusForDrive 2 "EXIT_DRIVE_REQUESTED_12V" 1 "READY_FOR_DRIVE_12V" 0 "NOT_READY_FOR_DRIVE_12V" ;
VAL_ 929 VC_userPresenceState 3 "TIMED_OUT" 2 "PRESENT" 1 "NOT_PRESENT" 0 "INIT" ;
VAL_ 929 VCFRONT_driverBuckleStatus 1 "BUCKLED" 0 "UNBUCKLED" ;
VAL_ 929 VCFRONT_driverDoorStatus 1 "DOOR_CLOSED" 0 "DOOR_OPEN" ;
VAL_ 929 VCFRONT_driverUnbuckled 2 "CHIME_SNA" 1 "CHIME_OCCUPIED_AND_UNBUCKLED" 0 "CHIME_NONE" ;
VAL_ 929 VCFRONT_passengerUnbuckled 2 "CHIME_SNA" 1 "CHIME_OCCUPIED_AND_UNBUCKLED" 0 "CHIME_NONE" ;
VAL_ 929 VCFRONT_2RowLeftUnbuckled 2 "CHIME_SNA" 1 "CHIME_OCCUPIED_AND_UNBUCKLED" 0 "CHIME_NONE" ;
VAL_ 929 VCFRONT_2RowCenterUnbuckled 2 "CHIME_SNA" 1 "CHIME_OCCUPIED_AND_UNBUCKLED" 0 "CHIME_NONE" ;
VAL_ 929 VCFRONT_2RowRightUnbuckled 2 "CHIME_SNA" 1 "CHIME_OCCUPIED_AND_UNBUCKLED" 0 "CHIME_NONE" ;
VAL_ 929 VCFRONT_pcsEFuseVoltage 1023 "SNA" ;
VAL_ 929 VCFRONT_3RowLeftUnbuckled 2 "CHIME_SNA" 1 "CHIME_OCCUPIED_AND_UNBUCKLED" 0 "CHIME_NONE" ;
VAL_ 929 VCFRONT_3RowRightUnbuckled 2 "CHIME_SNA" 1 "CHIME_OCCUPIED_AND_UNBUCKLED" 0 "CHIME_NONE" ;
VAL_ 258 VCLEFT_doorClosureStatusFront 8 "CLOSURE_STATUS_FAULT" 2 "CLOSURE_STATUS_CLOSED" 1 "CLOSURE_STATUS_OPEN" 0 "CLOSURE_STATUS_SNA" ;
VAL_ 258 VCLEFT_doorClosureStatusRear 8 "CLOSURE_STATUS_FAULT" 2 "CLOSURE_STATUS_CLOSED" 1 "CLOSURE_STATUS_OPEN" 0 "CLOSURE_STATUS_SNA" ;
VAL_ 258 VCLEFT_frontLatchStatus 8 "LATCH_FAULT" 7 "LATCH_DEFAULT" 6 "LATCH_TIMEOUT" 5 "LATCH_AJAR" 4 "LATCH_OPENING" 3 "LATCH_CLOSING" 2 "LATCH_CLOSED" 1 "LATCH_OPENED" 0 "LATCH_SNA" ;
VAL_ 258 VCLEFT_rearLatchStatus 8 "LATCH_FAULT" 7 "LATCH_DEFAULT" 6 "LATCH_TIMEOUT" 5 "LATCH_AJAR" 4 "LATCH_OPENING" 3 "LATCH_CLOSING" 2 "LATCH_CLOSED" 1 "LATCH_OPENED" 0 "LATCH_SNA" ;
VAL_ 258 VCLEFT_lastDoorReqSourceFront 4 "DOOR_REQUEST_SOURCE_ECU" 3 "DOOR_REQUEST_SOURCE_VCSEC" 2 "DOOR_REQUEST_SOURCE_EXTERIOR_HANDLE" 1 "DOOR_REQUEST_SOURCE_INTERIOR_BUTTON" 0 "DOOR_REQUEST_SOURCE_UNKNOWN" ;
VAL_ 258 VCLEFT_lastDoorReqSourceRear 4 "DOOR_REQUEST_SOURCE_ECU" 3 "DOOR_REQUEST_SOURCE_VCSEC" 2 "DOOR_REQUEST_SOURCE_EXTERIOR_HANDLE" 1 "DOOR_REQUEST_SOURCE_INTERIOR_BUTTON" 0 "DOOR_REQUEST_SOURCE_UNKNOWN" ;
VAL_ 258 VCLEFT_mirrorState 5 "MIRROR_STATE_CALIBRATION" 4 "MIRROR_STATE_RECALL" 3 "MIRROR_STATE_FOLD_UNFOLD" 2 "MIRROR_STATE_TILT_Y" 1 "MIRROR_STATE_TILT_X" 0 "MIRROR_STATE_IDLE" ;
VAL_ 258 VCLEFT_mirrorFoldState 4 "MIRROR_FOLD_STATE_UNFOLDING" 3 "MIRROR_FOLD_STATE_FOLDING" 2 "MIRROR_FOLD_STATE_UNFOLDED" 1 "MIRROR_FOLD_STATE_FOLDED" 0 "MIRROR_FOLD_STATE_UNKNOWN" ;
VAL_ 258 VCLEFT_mirrorRecallState 5 "MIRROR_RECALL_STATE_RECALLING_STOPPED" 4 "MIRROR_RECALL_STATE_RECALLING_FAILED" 3 "MIRROR_RECALL_STATE_RECALLING_COMPLETE" 2 "MIRROR_RECALL_STATE_RECALLING_AXIS_2" 1 "MIRROR_RECALL_STATE_RECALLING_AXIS_1" 0 "MIRROR_RECALL_STATE_INIT" ;
VAL_ 258 VCLEFT_mirrorHeatState 4 "HEATER_STATE_FAULT" 3 "HEATER_STATE_OFF_UNAVAILABLE" 2 "HEATER_STATE_OFF" 1 "HEATER_STATE_ON" 0 "HEATER_STATE_SNA" ;
VAL_ 626 VCLEFT_epbmDebugIndex 1 "TRANSITIONS" 0 "STATES" ;
VAL_ 626 VCLEFT_epbmCaliperState 6 "EPB_SAVED_CALIPERSTATE_WINCHMODE" 5 "EPB_SAVED_CALIPERSTATE_SERVICE" 4 "EPB_SAVED_CALIPERSTATE_OPEN" 3 "EPB_SAVED_CALIPERSTATE_PARK" 2 "EPB_SAVED_CALIPERSTATE_REAPPLY" 1 "EPB_SAVED_CALIPERSTATE_UNKNOWN" 0 "EPB_SAVED_CALIPERSTATE_UNSAVED" ;
VAL_ 626 VCLEFT_summonFaultReason 30 "EPB_SUMMONFAULT_MONITOR_TYPE_UNKNOWN" 29 "EPB_SUMMONFAULT_AP_MONITOR" 28 "EPB_SUMMONFAULT_REMOTE_DID_NOT_START" 27 "EPB_SUMMONFAULT_INVALID_REMOTE_STATE" 26 "EPB_SUMMONFAULT_START_IN_UNAVAILABLE" 25 "EPB_SUMMONFAULT_REMOTE_UNIT_FAULTED" 24 "EPB_SUMMONFAULT_LOCAL_UNIT_FAULTED" 23 "EPB_SUMMONFAULT_REMOTE_SUMMON_FAULTED" 22 "EPB_SUMMONFAULT_EPBREMOTE_MIA" 21 "EPB_SUMMONFAULT_PASSIVE_REQUEST" 20 "EPB_SUMMONFAULT_DI_STATE_INVALID" 19 "EPB_SUMMONFAULT_EPB_FAULT" 18 "EPB_SUMMONFAULT_MISMATCH" 17 "EPB_SUMMONFAULT_OOC" 16 "EPB_SUMMONFAULT_PM_REQUEST" 15 "EPB_SUMMONFAULT_PM_MIA" 14 "EPB_SUMMONFAULT_PARK_MIA" 13 "EPB_SUMMONFAULT_EXTERNAL" 12 "EPB_SUMMONFAULT_SPEED" 11 "EPB_SUMMONFAULT_EPBM_REQUEST" 10 "EPB_SUMMONFAULT_EAC_NOT_ALLOWED" 9 "EPB_SUMMONFAULT_VEH_CAN_FAULT" 8 "EPB_SUMMONFAULT_ESP_FAULT" 7 "EPB_SUMMONFAULT_DAS_FAULT" 6 "EPB_SUMMONFAULT_DI_APC_FAULT" 5 "EPB_SUMMONFAULT_DI_FAULT" 4 "EPB_SUMMONFAULT_EPBM_MIA" 3 "EPB_SUMMONFAULT_ESP_MIA" 2 "EPB_SUMMONFAULT_DAS_MIA" 1 "EPB_SUMMONFAULT_DI_MIA" 0 "EPB_SUMMONFAULT_NONE" ;
VAL_ 626 VCLEFT_epbSummonState 6 "EPB_SUMMON_UNAVAILABLE" 5 "EPB_SUMMON_FAULT" 4 "EPB_SUMMON_COMPLETE" 3 "EPB_SUMMON_ACTIVE" 2 "EPB_SUMMON_ARMED" 1 "EPB_SUMMON_IDLE" 0 "EPB_SUMMON_INIT" ;
VAL_ 626 VCLEFT_epbmSummonState 6 "EPB_SUMMON_UNAVAILABLE" 5 "EPB_SUMMON_FAULT" 4 "EPB_SUMMON_COMPLETE" 3 "EPB_SUMMON_ACTIVE" 2 "EPB_SUMMON_ARMED" 1 "EPB_SUMMON_IDLE" 0 "EPB_SUMMON_INIT" ;
VAL_ 626 VCLEFT_epbUnitStatus 23 "EPB_STATUS_COUNT" 22 "EPB_STATUS_AUTONOMY_OPEN" 21 "EPB_STATUS_FREE_ROLL_MODE" 20 "EPB_STATUS_DYNAMIC_PARKING" 19 "EPB_STATUS_EXTERNAL_PARKING" 18 "EPB_STATUS_RELEASING_FOR_EXTERNAL_PARK" 17 "EPB_STATUS_EXTERNAL_DYNAMIC" 16 "EPB_STATUS_SUMMON_PARKING" 15 "EPB_STATUS_SUMMON_RELEASING" 14 "EPB_STATUS_SUMMON" 13 "EPB_STATUS_WINCHMODE_PENDING" 12 "EPB_STATUS_PARK_PENDING" 11 "EPB_STATUS_SERVICE_RELEASING" 10 "EPB_STATUS_RELEASING" 9 "EPB_STATUS_DYNAMIC_APPLYING" 8 "EPB_STATUS_PARKING" 7 "EPB_STATUS_WINCHMODE_RELEASING" 6 "EPB_STATUS_WINCHMODE" 5 "EPB_STATUS_SERVICE" 4 "EPB_STATUS_START" 3 "EPB_STATUS_PARK" 2 "EPB_STATUS_DYNAMIC" 1 "EPB_STATUS_OPEN" 0 "EPB_STATUS_UNKNOWN" ;
VAL_ 626 VCLEFT_epbmFaultStatus 3 "EPB_STATUS_FAULT_IDLE" 2 "EPB_STATUS_FAULT" 1 "EPB_STATUS_RETRY" 0 "EPB_STATUS_NOMINAL" ;
VAL_ 626 VCLEFT_epbFaultStatus 3 "EPB_STATUS_FAULT_IDLE" 2 "EPB_STATUS_FAULT" 1 "EPB_STATUS_RETRY" 0 "EPB_STATUS_NOMINAL" ;
VAL_ 626 VCLEFT_epbmSystemStatus 8 "EPB_VEHICLE_STATUS_MISMATCH" 7 "EPB_VEHICLE_STATUS_FAULT_SECURE" 6 "EPB_VEHICLE_STATUS_FAULT" 5 "EPB_VEHICLE_STATUS_RELEASING" 4 "EPB_VEHICLE_STATUS_PARKING" 3 "EPB_VEHICLE_STATUS_DYNAMIC" 2 "EPB_VEHICLE_STATUS_PARKED" 1 "EPB_VEHICLE_STATUS_RELEASED" 0 "EPB_VEHICLE_STATUS_UNKNOWN" ;
VAL_ 1140 VCLEFT_cdpRequestState 1 "EPB_CDP_REQUEST_VALID" 0 "EPB_CDP_REQUEST_INVALID" ;
VAL_ 1140 VCLEFT_epbmSystemStatusQF 1 "EPBM_SYSTEM_STATUS_INVALID" 0 "EPBM_SYSTEM_STATUS_VALID" ;
VAL_ 1140 VCLEFT_epbmUnitStatus 23 "EPB_STATUS_COUNT" 22 "EPB_STATUS_AUTONOMY_OPEN" 21 "EPB_STATUS_FREE_ROLL_MODE" 20 "EPB_STATUS_DYNAMIC_PARKING" 19 "EPB_STATUS_EXTERNAL_PARKING" 18 "EPB_STATUS_RELEASING_FOR_EXTERNAL_PARK" 17 "EPB_STATUS_EXTERNAL_DYNAMIC" 16 "EPB_STATUS_SUMMON_PARKING" 15 "EPB_STATUS_SUMMON_RELEASING" 14 "EPB_STATUS_SUMMON" 13 "EPB_STATUS_WINCHMODE_PENDING" 12 "EPB_STATUS_PARK_PENDING" 11 "EPB_STATUS_SERVICE_RELEASING" 10 "EPB_STATUS_RELEASING" 9 "EPB_STATUS_DYNAMIC_APPLYING" 8 "EPB_STATUS_PARKING" 7 "EPB_STATUS_WINCHMODE_RELEASING" 6 "EPB_STATUS_WINCHMODE" 5 "EPB_STATUS_SERVICE" 4 "EPB_STATUS_START" 3 "EPB_STATUS_PARK" 2 "EPB_STATUS_DYNAMIC" 1 "EPB_STATUS_OPEN" 0 "EPB_STATUS_UNKNOWN" ;
VAL_ 1140 VCLEFT_epbmCdpState 2 "EPB_CDP_STATE_FAULT" 1 "EPB_CDP_STATE_VALID" 0 "EPB_CDP_STATE_UNKNOWN" ;
VAL_ 770 VCLEFT_infoIndex 255 "END" 41 "SUBCOMPONENT14" 40 "SUBCOMPONENT13" 39 "SUBCOMPONENT12" 38 "SUBCOMPONENT11" 37 "SUBCOMPONENT10" 36 "SUBCOMPONENT9" 35 "SUBCOMPONENT8" 34 "SUBCOMPONENT7" 33 "SUBCOMPONENT6" 32 "SUBCOMPONENT5" 31 "SUBCOMPONENT4" 24 "SUBCOMPONENT3" 23 "SUBCOMPONENT2" 20 "UDS_PROTOCOL_BOOTCRC" 19 "VERSION_DEPRECATED" 18 "BOOTLOADER_GITHASH" 17 "APP_GITHASH" 16 "SUBCOMPONENT1" 15 "BOOTLOADER_CRC" 14 "BOOTLOADER_SVN" 13 "APP_CRC" 11 "PCBAID_ASSYID_USAGEID" 10 "BUILD_HWID_COMPONENTID" 9 "DEPRECATED_9" 8 "DEPRECATED_8" 7 "DEPRECATED_7" 6 "DEPRECATED_6" 5 "DEPRECATED_5" 4 "DEPRECATED_4" 3 "DEPRECATED_3" 2 "DEPRECATED_2" 1 "DEPRECATED_1" 0 "DEPRECATED_0" ;
VAL_ 770 VCLEFT_infoBuildType 4 "INFO_MFG_BUILD" 3 "INFO_TRACEABLE_CI_BUILD" 2 "INFO_LOCAL_BUILD" 1 "INFO_PLATFORM_BUILD" 0 "INFO_UNKNOWN_BUILD" ;
VAL_ 770 VCLEFT_infoAssemblyId 255 "ASSEMBLY_SNA" 1 "ASSEMBLY1" ;
